VERSION ""

NS_ :

BS_:

BU_: PowertrainControlModule AtmosphericSensor SafetyRestraintSystem2 Aftertreatment_2_GasOutlet Aftertreatment_2_GasIntake DieselParticulateFilterControl Turbocharger SafetyRestraintSystem1 CabDisplay2 Aftertreatment_1_GasOutlet Aftertreatment_1_GasIntake OnBoardDataLogger OffBoardDiagnosticTool2 OffBoardDiagnosticTool1 FileServer ParkingBrakeController SeatController2 FanDriveController SteeringColumnUnit CommunicationUnitRadio CommunicationUnitSatellite CommunicationUnitCellular PropulsionBatteryCharger ChassisController2 ChassisController1 EngineValveControl AuxiliaryHeater2 AuxiliaryHeater1 ClutchUnit RampControl InformationSystem1 SuspensionSystemController2 OilSensor VehicleDynamicStability ExhaustEmissionController TransmissionDisplay2 TransmissionDisplay1 ClimateControl2 WaterPumpController RearAxleSteeringController LightingOperatorControl SeatController1 IgnitionController2 IgnitionController1 TirePressureController CabController2 CabController1 PneumaticSystemController SuspensionSystemController1 HydraulicPumpController EnduranceBrakingSystem RetarderExhaustEngine2 OnBoardDiagnosticUnit HeadwayController RetarderExhaustEngine1 CabDisplay1 ManagementComputer VirtualTerminal OffVehicleGateway PowerTakeOffFront HitchControl AuxiliaryValveControl BodyController TractorTrailerBridge1 StarterSystem ElectricalSystem VehicleSecurity VehicleNavigation AerodynamicControl ElectricalChargingSystem ClimateControl1 TripRecorder InstrumentCluster SuspensionDriveAxle2 SuspensionDriveAxle1 SuspensionSteerAxle SteeringController FuelSystem CruiseControl RetarderDriveline RetarderEngine BrakesDriveAxle2 BrakesDriveAxle1 BrakesSystemController BrakesSteerAxle AxleDrive2 AxleDrive1 AxleSteering PowerTakeOff ShiftConsoleSecondary ShiftConsolePrimary Transmission2 Transmission1 Engine2 Engine1

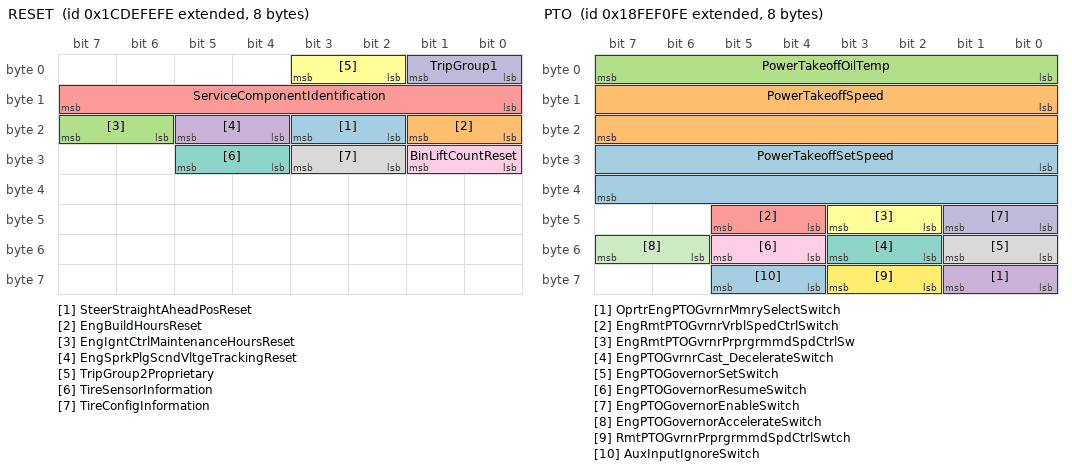
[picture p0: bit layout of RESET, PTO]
BO_ 2631859966 RESET: 8 Vector__XXX
 SG_ SteerStraightAheadPosReset : 18|2@1+ (1,0) [0|3] "" Vector__XXX
 SG_ EngBuildHoursReset : 16|2@1+ (1,0) [0|3] "" Vector__XXX
 SG_ EngIgntCtrlMaintenanceHoursReset : 22|2@1+ (1,0) [0|3] "" Vector__XXX
 SG_ EngSprkPlgScndVltgeTrackingReset : 20|2@1+ (1,0) [0|3] "" Vector__XXX
 SG_ ServiceComponentIdentification : 8|8@1+ (1,0) [0|250] "ID" Vector__XXX
 SG_ TripGroup2Proprietary : 2|2@1+ (1,0) [0|3] "" Vector__XXX
 SG_ TireSensorInformation : 28|2@1+ (1,0) [0|3] "" Vector__XXX
 SG_ TireConfigInformation : 26|2@1+ (1,0) [0|3] "" Vector__XXX
 SG_ BinLiftCountReset : 24|2@1+ (1,0) [0|3] "" Vector__XXX
 SG_ TripGroup1 : 0|2@1+ (1,0) [0|3] "" Vector__XXX

BO_ 2566840830 RC: 19 Vector__XXX
 SG_ PercentTorqueAtPeakTorquePoint5 : 144|8@1+ (1,-125) [-125|0] "%" Vector__XXX
 SG_ ReferenceRetarderTorque : 128|16@1+ (1,0) [0|64255] "Nm" Vector__XXX
 SG_ RetarderSpeedAtPeakTorquePoint5 : 112|16@1+ (0.125,0) [0|8031.875] "rpm" Vector__XXX
 SG_ PercentTorqueAtPoint4 : 104|8@1+ (1,-125) [-125|0] "%" Vector__XXX
 SG_ RetarderSpeedAtPoint4 : 88|16@1+ (0.125,0) [0|8031.875] "rpm" Vector__XXX
 SG_ PercentTorqueAtPoint3 : 80|8@1+ (1,-125) [-125|0] "%" Vector__XXX
 SG_ RetarderSpeedAtPoint3 : 64|16@1+ (0.125,0) [0|8031.875] "rpm" Vector__XXX
 SG_ PercentTorqueAtMaxSpeedPoint2 : 56|8@1+ (1,-125) [-125|0] "%" Vector__XXX
 SG_ MaxRetarderSpeedPoint2 : 40|16@1+ (0.125,0) [0|8031.875] "rpm" Vector__XXX
 SG_ PercentTorqueAtIdlePoint1 : 32|8@1+ (1,-125) [-125|0] "%" Vector__XXX
 SG_ RetarderSpeedAtIdlePoint1 : 16|16@1+ (0.125,0) [0|8031.875] "rpm" Vector__XXX
 SG_ RetarderCtrlMethod : 8|8@1+ (1,0) [0|250] "steps" Vector__XXX
 SG_ RetarderLocation : 4|4@1+ (1,0) [0|15] "" Vector__XXX
 SG_ RetarderType : 0|4@1+ (1,0) [0|15] "" Vector__XXX

BO_ 2633930238 RBI: 8 Vector__XXX
 SG_ EngOperationTimeSinceRebuild : 0|32@1+ (1,0) [0|4211081215] "s" Vector__XXX

BO_ 2566844670 PTO: 8 Vector__XXX
 SG_ PowerTakeoffSetSpeed : 24|16@1+ (0.125,0) [0|8031.875] "rpm" Vector__XXX
 SG_ PowerTakeoffSpeed : 8|16@1+ (0.125,0) [0|8031.875] "rpm" Vector__XXX
 SG_ PowerTakeoffOilTemp : 0|8@1+ (1,-40) [-40|210] "°C" Vector__XXX
 SG_ OprtrEngPTOGvrnrMmrySelectSwitch : 56|2@1+ (1,0) [0|3] "" Vector__XXX
 SG_ EngRmtPTOGvrnrVrblSpedCtrlSwitch : 44|2@1+ (1,0) [0|3] "" Vector__XXX
 SG_ EngRmtPTOGvrnrPrprgrmmdSpdCtrlSw : 42|2@1+ (1,0) [0|3] "" Vector__XXX
 SG_ EngPTOGvrnrCast_DecelerateSwitch : 50|2@1+ (1,0) [0|3] "" Vector__XXX
 SG_ EngPTOGovernorSetSwitch : 48|2@1+ (1,0) [0|3] "" Vector__XXX
 SG_ EngPTOGovernorResumeSwitch : 52|2@1+ (1,0) [0|3] "" Vector__XXX
 SG_ EngPTOGovernorEnableSwitch : 40|2@1+ (1,0) [0|3] "" Vector__XXX
 SG_ EngPTOGovernorAccelerateSwitch : 54|2@1+ (1,0) [0|3] "" Vector__XXX
 SG_ RmtPTOGvrnrPrprgrmmdSpdCtrlSwtch : 58|2@1+ (1,0) [0|3] "" Vector__XXX
 SG_ AuxInputIgnoreSwitch : 60|2@1+ (1,0) [0|3] "" Vector__XXX

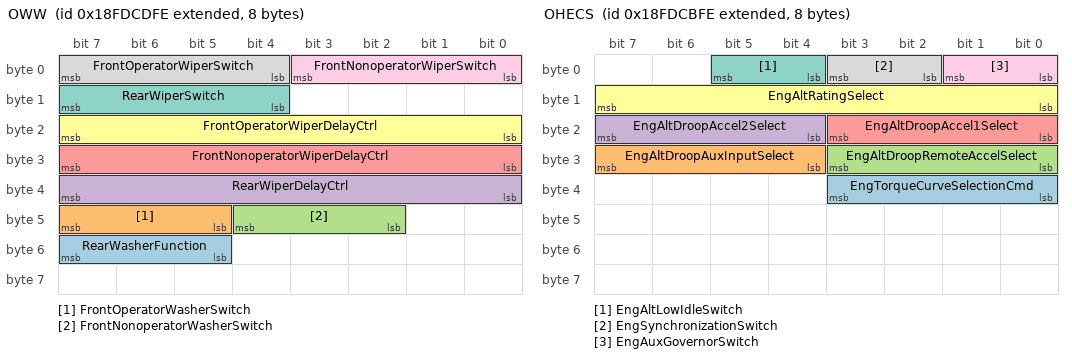
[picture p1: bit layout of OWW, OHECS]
BO_ 2566770174 OWW: 8 Vector__XXX
 SG_ RearWasherFunction : 53|3@1+ (1,0) [0|7] "" Vector__XXX
 SG_ FrontOperatorWasherSwitch : 45|3@1+ (1,0) [0|7] "" Vector__XXX
 SG_ FrontNonoperatorWasherSwitch : 42|3@1+ (1,0) [0|7] "" Vector__XXX
 SG_ RearWiperDelayCtrl : 32|8@1+ (0.4,0) [0|100] "%" Vector__XXX
 SG_ FrontNonoperatorWiperDelayCtrl : 24|8@1+ (0.4,0) [0|100] "%" Vector__XXX
 SG_ FrontOperatorWiperDelayCtrl : 16|8@1+ (0.4,0) [0|100] "%" Vector__XXX
 SG_ RearWiperSwitch : 12|4@1+ (1,0) [0|15] "" Vector__XXX
 SG_ FrontOperatorWiperSwitch : 4|4@1+ (1,0) [0|15] "" Vector__XXX
 SG_ FrontNonoperatorWiperSwitch : 0|4@1+ (1,0) [0|15] "" Vector__XXX

BO_ 2566769662 OHECS: 8 Vector__XXX
 SG_ EngTorqueCurveSelectionCmd : 32|4@1+ (1,0) [0|15] "" Vector__XXX
 SG_ EngAltDroopAuxInputSelect : 28|4@1+ (1,0) [0|15] "" Vector__XXX
 SG_ EngAltDroopRemoteAccelSelect : 24|4@1+ (1,0) [0|15] "" Vector__XXX
 SG_ EngAltDroopAccel2Select : 20|4@1+ (1,0) [0|15] "" Vector__XXX
 SG_ EngAltDroopAccel1Select : 16|4@1+ (1,0) [0|15] "" Vector__XXX
 SG_ EngAltRatingSelect : 8|8@1+ (1,0) [0|255] "" Vector__XXX
 SG_ EngAltLowIdleSwitch : 4|2@1+ (1,0) [0|3] "" Vector__XXX
 SG_ EngSynchronizationSwitch : 2|2@1+ (1,0) [0|3] "" Vector__XXX
 SG_ EngAuxGovernorSwitch : 0|2@1+ (1,0) [0|3] "" Vector__XXX

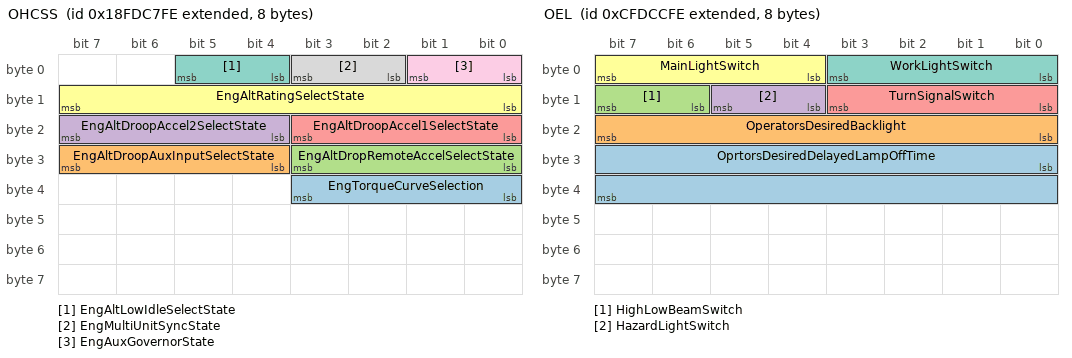
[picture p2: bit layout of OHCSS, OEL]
BO_ 2566768638 OHCSS: 8 Vector__XXX
 SG_ EngTorqueCurveSelection : 32|4@1+ (1,0) [0|15] "" Vector__XXX
 SG_ EngAltDroopAuxInputSelectState : 28|4@1+ (1,0) [0|15] "" Vector__XXX
 SG_ EngAltDropRemoteAccelSelectState : 24|4@1+ (1,0) [0|15] "" Vector__XXX
 SG_ EngAltDroopAccel2SelectState : 20|4@1+ (1,0) [0|15] "" Vector__XXX
 SG_ EngAltDroopAccel1SelectState : 16|4@1+ (1,0) [0|15] "" Vector__XXX
 SG_ EngAltRatingSelectState : 8|8@1+ (1,0) [0|255] "" Vector__XXX
 SG_ EngAltLowIdleSelectState : 4|2@1+ (1,0) [0|3] "" Vector__XXX
 SG_ EngMultiUnitSyncState : 2|2@1+ (1,0) [0|3] "" Vector__XXX
 SG_ EngAuxGovernorState : 0|2@1+ (1,0) [0|3] "" Vector__XXX

BO_ 2365443326 OEL: 8 Vector__XXX
 SG_ OprtorsDesiredDelayedLampOffTime : 24|16@1+ (1,0) [0|64255] "s" Vector__XXX
 SG_ OperatorsDesiredBacklight : 16|8@1+ (0.4,0) [0|100] "%" Vector__XXX
 SG_ HighLowBeamSwitch : 14|2@1+ (1,0) [0|3] "" Vector__XXX
 SG_ HazardLightSwitch : 12|2@1+ (1,0) [0|3] "" Vector__XXX
 SG_ TurnSignalSwitch : 8|4@1+ (1,0) [0|15] "" Vector__XXX
 SG_ MainLightSwitch : 4|4@1+ (1,0) [0|15] "" Vector__XXX
 SG_ WorkLightSwitch : 0|4@1+ (1,0) [0|15] "" Vector__XXX

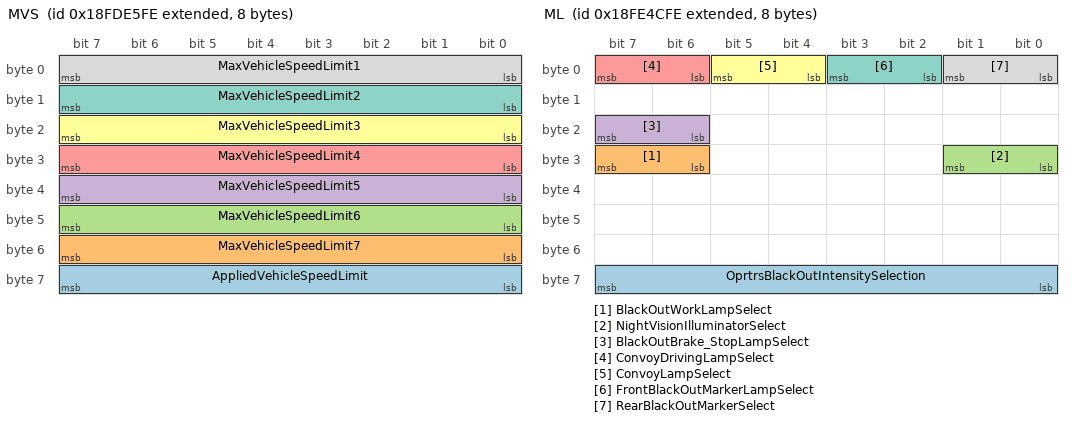
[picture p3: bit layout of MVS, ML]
BO_ 2566776318 MVS: 8 Vector__XXX
 SG_ AppliedVehicleSpeedLimit : 56|8@1+ (1,0) [0|250] "km/h" Vector__XXX
 SG_ MaxVehicleSpeedLimit7 : 48|8@1+ (1,0) [0|250] "km/h" Vector__XXX
 SG_ MaxVehicleSpeedLimit6 : 40|8@1+ (1,0) [0|250] "km/h" Vector__XXX
 SG_ MaxVehicleSpeedLimit5 : 32|8@1+ (1,0) [0|250] "km/h" Vector__XXX
 SG_ MaxVehicleSpeedLimit4 : 24|8@1+ (1,0) [0|250] "km/h" Vector__XXX
 SG_ MaxVehicleSpeedLimit3 : 16|8@1+ (1,0) [0|250] "km/h" Vector__XXX
 SG_ MaxVehicleSpeedLimit2 : 8|8@1+ (1,0) [0|250] "km/h" Vector__XXX
 SG_ MaxVehicleSpeedLimit1 : 0|8@1+ (1,0) [0|250] "km/h" Vector__XXX

BO_ 2566802686 ML: 8 Vector__XXX
 SG_ OprtrsBlackOutIntensitySelection : 56|8@1+ (0.4,0) [0|100] "%" Vector__XXX
 SG_ BlackOutWorkLampSelect : 30|2@1+ (1,0) [0|3] "" Vector__XXX
 SG_ NightVisionIlluminatorSelect : 24|2@1+ (1,0) [0|3] "" Vector__XXX
 SG_ BlackOutBrake_StopLampSelect : 22|2@1+ (1,0) [0|3] "" Vector__XXX
 SG_ ConvoyDrivingLampSelect : 6|2@1+ (1,0) [0|3] "" Vector__XXX
 SG_ ConvoyLampSelect : 4|2@1+ (1,0) [0|3] "" Vector__XXX
 SG_ FrontBlackOutMarkerLampSelect : 2|2@1+ (1,0) [0|3] "" Vector__XXX
 SG_ RearBlackOutMarkerSelect : 0|2@1+ (1,0) [0|3] "" Vector__XXX

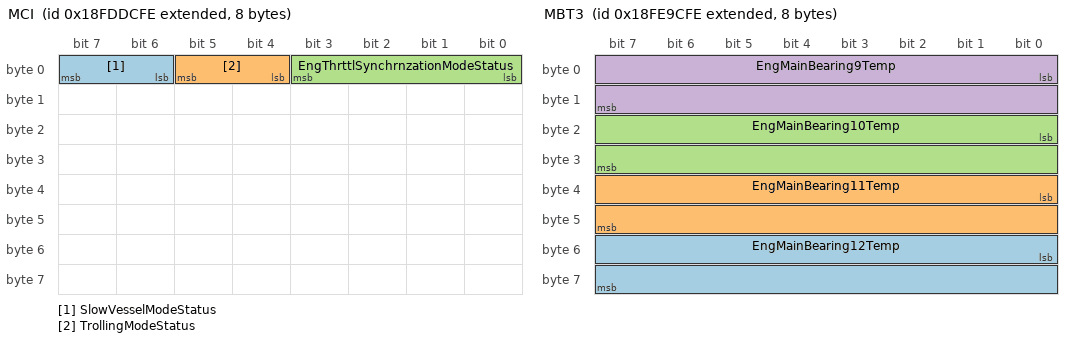
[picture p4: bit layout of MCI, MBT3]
BO_ 2566774014 MCI: 8 Vector__XXX
 SG_ SlowVesselModeStatus : 6|2@1+ (1,0) [0|3] "" Vector__XXX
 SG_ TrollingModeStatus : 4|2@1+ (1,0) [0|3] "" Vector__XXX
 SG_ EngThrttlSynchrnzationModeStatus : 0|4@1+ (1,0) [0|15] "" Vector__XXX

BO_ 2566823166 MBT3: 8 Vector__XXX
 SG_ EngMainBearing12Temp : 48|16@1+ (0.03125,-273) [-273|1734.96875] "°C" Vector__XXX
 SG_ EngMainBearing11Temp : 32|16@1+ (0.03125,-273) [-273|1734.96875] "°C" Vector__XXX
 SG_ EngMainBearing10Temp : 16|16@1+ (0.03125,-273) [-273|1734.96875] "°C" Vector__XXX
 SG_ EngMainBearing9Temp : 0|16@1+ (0.03125,-273) [-273|1734.96875] "°C" Vector__XXX

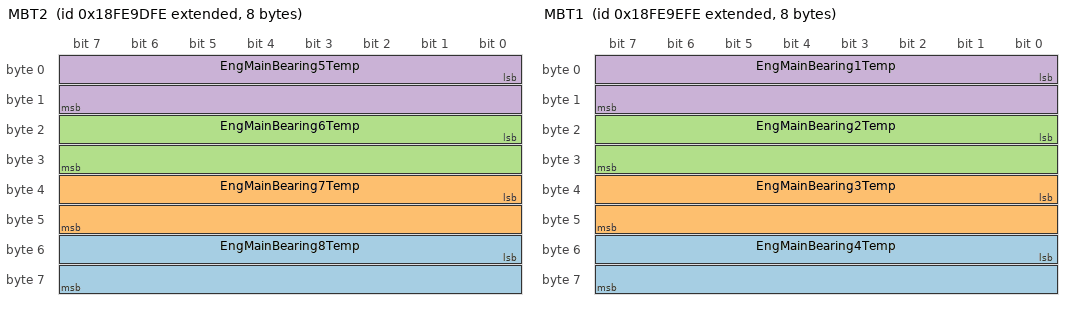
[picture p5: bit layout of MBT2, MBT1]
BO_ 2566823422 MBT2: 8 Vector__XXX
 SG_ EngMainBearing8Temp : 48|16@1+ (0.03125,-273) [-273|1734.96875] "°C" Vector__XXX
 SG_ EngMainBearing7Temp : 32|16@1+ (0.03125,-273) [-273|1734.96875] "°C" Vector__XXX
 SG_ EngMainBearing6Temp : 16|16@1+ (0.03125,-273) [-273|1734.96875] "°C" Vector__XXX
 SG_ EngMainBearing5Temp : 0|16@1+ (0.03125,-273) [-273|1734.96875] "°C" Vector__XXX

BO_ 2566823678 MBT1: 8 Vector__XXX
 SG_ EngMainBearing4Temp : 48|16@1+ (0.03125,-273) [-273|1734.96875] "°C" Vector__XXX
 SG_ EngMainBearing3Temp : 32|16@1+ (0.03125,-273) [-273|1734.96875] "°C" Vector__XXX
 SG_ EngMainBearing2Temp : 16|16@1+ (0.03125,-273) [-273|1734.96875] "°C" Vector__XXX
 SG_ EngMainBearing1Temp : 0|16@1+ (0.03125,-273) [-273|1734.96875] "°C" Vector__XXX

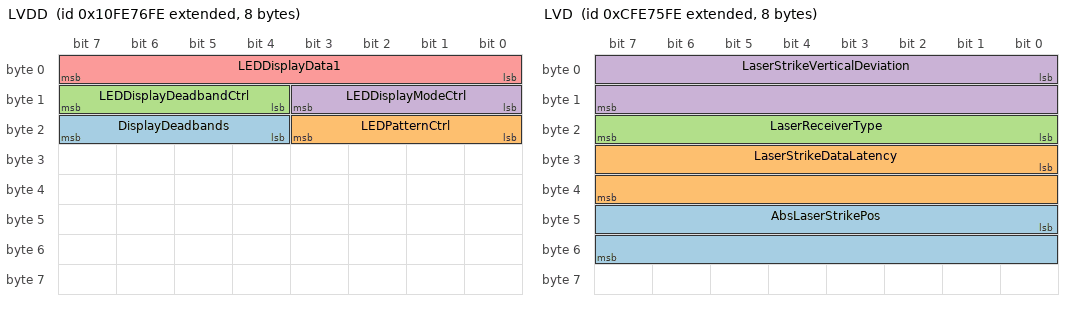
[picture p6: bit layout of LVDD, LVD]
BO_ 2432595710 LVDD: 8 Vector__XXX
 SG_ DisplayDeadbands : 20|4@1+ (1,0) [0|15] "" Vector__XXX
 SG_ LEDPatternCtrl : 16|4@1+ (1,0) [0|15] "" Vector__XXX
 SG_ LEDDisplayDeadbandCtrl : 12|4@1+ (1,0) [0|15] "" Vector__XXX
 SG_ LEDDisplayModeCtrl : 8|4@1+ (1,0) [0|15] "" Vector__XXX
 SG_ LEDDisplayData1 : 0|8@1+ (1,0) [0|255] "" Vector__XXX

BO_ 2365486590 LVD: 8 Vector__XXX
 SG_ AbsLaserStrikePos : 40|16@1+ (0.1,0) [0|6425.5] "mm" Vector__XXX
 SG_ LaserStrikeDataLatency : 24|16@1+ (5.12E-005,0) [0|3.289856] "s" Vector__XXX
 SG_ LaserReceiverType : 16|8@1+ (1,0) [0|250] "" Vector__XXX
 SG_ LaserStrikeVerticalDeviation : 0|16@1+ (0.1,-3200) [-3200|3225.5] "mm" Vector__XXX

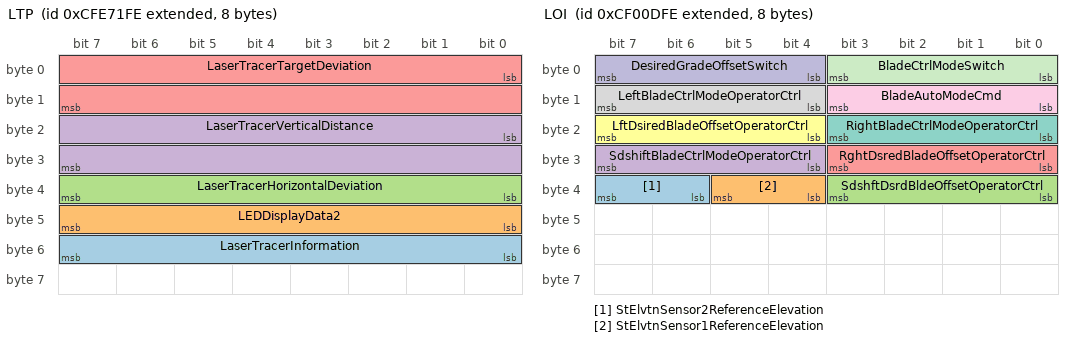
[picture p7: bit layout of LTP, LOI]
BO_ 2365485566 LTP: 8 Vector__XXX
 SG_ LaserTracerInformation : 48|8@1+ (1,0) [0|255] "" Vector__XXX
 SG_ LEDDisplayData2 : 40|8@1+ (1,0) [0|255] "" Vector__XXX
 SG_ LaserTracerHorizontalDeviation : 32|8@1+ (1,0) [0|200] "%" Vector__XXX
 SG_ LaserTracerVerticalDistance : 16|16@1+ (0.1,0) [0|6400] "mm" Vector__XXX
 SG_ LaserTracerTargetDeviation : 0|16@1+ (0.1,-3200) [-3200|3225.5] "mm" Vector__XXX

BO_ 2633939454 LTFI: 22 Vector__XXX
 SG_ TripDriveFuelEconomy : 160|16@1+ (0.001953125,0) [0|125.498046875] "km/L" Vector__XXX
 SG_ TripCruiseFuelUsed : 128|32@1+ (0.5,0) [0|2105540607.5] "L" Vector__XXX
 SG_ TripVehicleIdleFuelUsed : 96|32@1+ (0.5,0) [0|2105540607.5] "L" Vector__XXX
 SG_ TripPTOGovernorNonmovingFuelUsed : 64|32@1+ (0.5,0) [0|2105540607.5] "L" Vector__XXX
 SG_ TripPTOGovernorMovingFuelUsed : 32|32@1+ (0.5,0) [0|2105540607.5] "L" Vector__XXX
 SG_ TripDriveFuelUsed : 0|32@1+ (0.5,0) [0|2105540607.5] "L" Vector__XXX

BO_ 2365486334 LSP: 8 Vector__XXX
 SG_ BldeHeightSetPointHighResolution : 16|32@1+ (1E-007,-209.7152) [-209.7152|209.7152] "m" Vector__XXX
 SG_ ModifyLevelingSystemSetPoint : 0|16@1+ (0.1,-3200) [-3200|3225.5] "mm" Vector__XXX

BO_ 2364542462 LOI: 8 Vector__XXX
 SG_ StElvtnSensor2ReferenceElevation : 38|2@1+ (1,0) [0|3] "" Vector__XXX
 SG_ StElvtnSensor1ReferenceElevation : 36|2@1+ (1,0) [0|3] "" Vector__XXX
 SG_ SdshftDsrdBldeOffsetOperatorCtrl : 32|4@1+ (1,0) [0|15] "" Vector__XXX
 SG_ SdshiftBladeCtrlModeOperatorCtrl : 28|4@1+ (1,0) [0|15] "" Vector__XXX
 SG_ RghtDsredBladeOffsetOperatorCtrl : 24|4@1+ (1,0) [0|15] "" Vector__XXX
 SG_ LftDsiredBladeOffsetOperatorCtrl : 20|4@1+ (1,0) [0|15] "" Vector__XXX
 SG_ RightBladeCtrlModeOperatorCtrl : 16|4@1+ (1,0) [0|15] "" Vector__XXX
 SG_ LeftBladeCtrlModeOperatorCtrl : 12|4@1+ (1,0) [0|15] "" Vector__XXX
 SG_ BladeAutoModeCmd : 8|4@1+ (1,0) [0|15] "" Vector__XXX
 SG_ DesiredGradeOffsetSwitch : 4|4@1+ (1,0) [0|15] "" Vector__XXX
 SG_ BladeCtrlModeSwitch : 0|4@1+ (1,0) [0|15] "" Vector__XXX

BO_ 2365486078 LMP: 8 Vector__XXX
 SG_ MastPos : 0|16@1+ (0.1,-3200) [-3200|3225.5] "mm" Vector__XXX

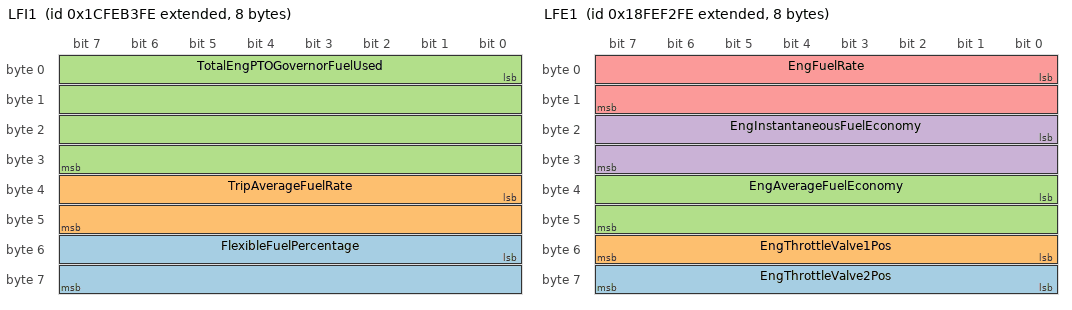
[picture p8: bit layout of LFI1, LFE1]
BO_ 2633937918 LFI1: 8 Vector__XXX
 SG_ FlexibleFuelPercentage : 48|16@1+ (0.0025,0) [0|100] "%" Vector__XXX
 SG_ TripAverageFuelRate : 32|16@1+ (0.05,0) [0|3212.75] "L/h" Vector__XXX
 SG_ TotalEngPTOGovernorFuelUsed : 0|32@1+ (0.5,0) [0|2105540607.5] "L" Vector__XXX

BO_ 2566845182 LFE1: 8 Vector__XXX
 SG_ EngThrottleValve2Pos : 56|8@1+ (0.4,0) [0|100] "%" Vector__XXX
 SG_ EngThrottleValve1Pos : 48|8@1+ (0.4,0) [0|100] "%" Vector__XXX
 SG_ EngAverageFuelEconomy : 32|16@1+ (0.001953125,0) [0|125.498046875] "km/L" Vector__XXX
 SG_ EngInstantaneousFuelEconomy : 16|16@1+ (0.001953125,0) [0|125.498046875] "km/L" Vector__XXX
 SG_ EngFuelRate : 0|16@1+ (0.05,0) [0|3212.75] "L/h" Vector__XXX

BO_ 2566842878 LFC1: 8 Vector__XXX
 SG_ EngTotalFuelUsed : 32|32@1+ (0.5,0) [0|2105540607.5] "L" Vector__XXX
 SG_ EngTripFuel : 0|32@1+ (0.5,0) [0|2105540607.5] "L" Vector__XXX

BO_ 2633883646 FWD: 8 Vector__XXX
 SG_ FrontWheelDriveActuatorStatus : 0|2@1+ (1,0) [0|3] "" Vector__XXX

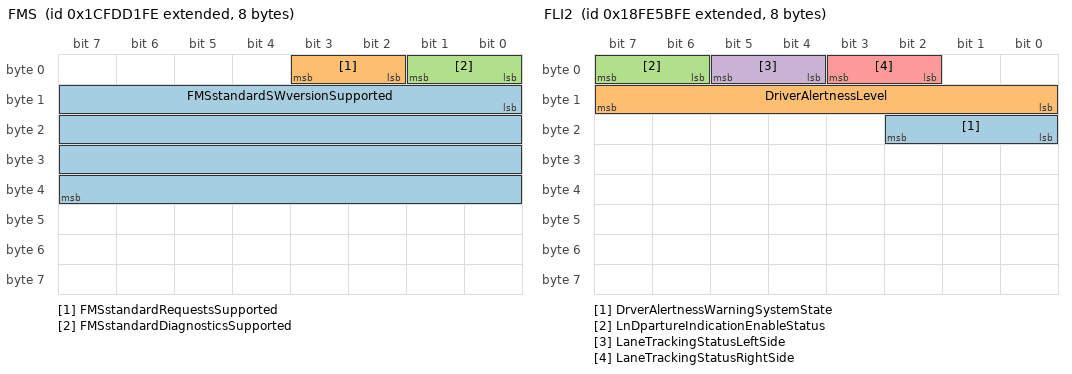
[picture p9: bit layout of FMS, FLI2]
BO_ 2633880062 FMS: 8 Vector__XXX
 SG_ FMSstandardSWversionSupported : 8|32@1+ (1,0) [0|255] "" Vector__XXX
 SG_ FMSstandardRequestsSupported : 2|2@1+ (1,0) [0|3] "" Vector__XXX
 SG_ FMSstandardDiagnosticsSupported : 0|2@1+ (1,0) [0|3] "" Vector__XXX

BO_ 2566806526 FLI2: 8 Vector__XXX
 SG_ DrverAlertnessWarningSystemState : 16|3@1+ (1,0) [0|7] "" Vector__XXX
 SG_ DriverAlertnessLevel : 8|8@1+ (0.4,0) [0|100] "%" Vector__XXX
 SG_ LnDpartureIndicationEnableStatus : 6|2@1+ (1,0) [0|3] "" Vector__XXX
 SG_ LaneTrackingStatusLeftSide : 4|2@1+ (1,0) [0|3] "" Vector__XXX
 SG_ LaneTrackingStatusRightSide : 2|2@1+ (1,0) [0|3] "" Vector__XXX

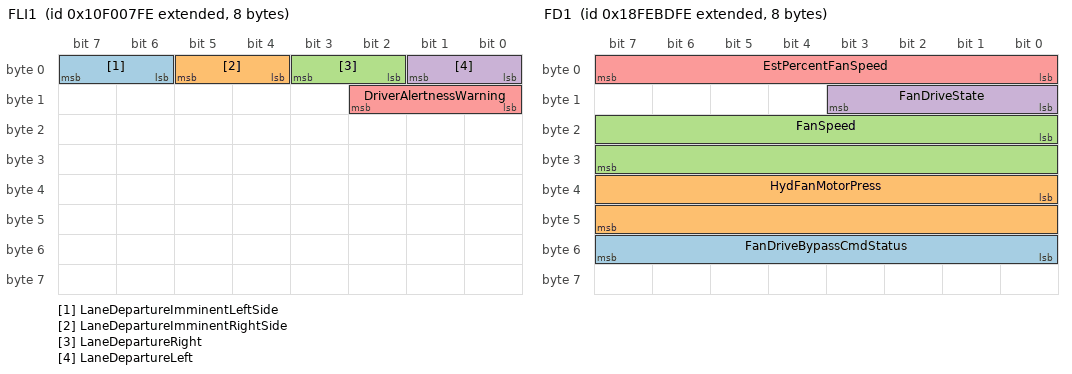
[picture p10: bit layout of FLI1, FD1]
BO_ 2431649790 FLI1: 8 Vector__XXX
 SG_ LaneDepartureImminentLeftSide : 6|2@1+ (1,0) [0|3] "" Vector__XXX
 SG_ LaneDepartureImminentRightSide : 4|2@1+ (1,0) [0|3] "" Vector__XXX
 SG_ LaneDepartureRight : 2|2@1+ (1,0) [0|3] "" Vector__XXX
 SG_ LaneDepartureLeft : 0|2@1+ (1,0) [0|3] "" Vector__XXX
 SG_ DriverAlertnessWarning : 8|3@1+ (1,0) [0|7] "" Vector__XXX

BO_ 2633929214 FL: 8 Vector__XXX
 SG_ EngFuelLeakage2 : 2|2@1+ (1,0) [0|3] "" Vector__XXX
 SG_ EngFuelLeakage1 : 0|2@1+ (1,0) [0|3] "" Vector__XXX

BO_ 2566831614 FD1: 8 Vector__XXX
 SG_ FanDriveBypassCmdStatus : 48|8@1+ (0.4,0) [0|100] "%" Vector__XXX
 SG_ HydFanMotorPress : 32|16@1+ (0.5,0) [0|32127.5] "kPa" Vector__XXX
 SG_ FanSpeed : 16|16@1+ (0.125,0) [0|8031.875] "rpm" Vector__XXX
 SG_ FanDriveState : 8|4@1+ (1,0) [0|15] "" Vector__XXX
 SG_ EstPercentFanSpeed : 0|8@1+ (0.4,0) [0|100] "%" Vector__XXX

BO_ 2566820094 ETH: 8 Vector__XXX
 SG_ EngTorqueLimit6AxleInput : 248|16@1+ (2,0) [0|128510] "Nm" Vector__XXX
 SG_ EngTorqueLimit5Switch : 232|16@1+ (1,0) [0|64255] "Nm" Vector__XXX
 SG_ EngTorqueLimit4Trans : 216|16@1+ (1,0) [0|64255] "Nm" Vector__XXX
 SG_ EngTorqueLimit3Trans : 200|16@1+ (1,0) [0|64255] "Nm" Vector__XXX
 SG_ TransGearRatio3 : 184|16@1+ (0.01,0) [0|642.55] "" Vector__XXX
 SG_ EngTorqueLimit2Trans : 168|16@1+ (1,0) [0|64255] "Nm" Vector__XXX
 SG_ TransGearRatio2 : 152|16@1+ (0.01,0) [0|642.55] "" Vector__XXX
 SG_ EngTorqueLimit1Trans : 136|16@1+ (1,0) [0|64255] "Nm" Vector__XXX
 SG_ TransGearRatio1 : 120|16@1+ (0.01,0) [0|642.55] "" Vector__XXX
 SG_ EngTorqueLimitFeature : 114|3@1+ (1,0) [0|7] "" Vector__XXX
 SG_ TorqueLimitingFeatureStatus : 112|2@1+ (1,0) [0|3] "" Vector__XXX
 SG_ CalibRecordDurationTime : 80|32@1+ (0.05,0) [0|210554060.75] "h" Vector__XXX
 SG_ CalibRecordStartYear : 72|8@1+ (1,1985) [1985|2235] "years" Vector__XXX
 SG_ CalibRecordStartDay : 64|8@1+ (0.25,0) [0.25|31.75] "days" Vector__XXX
 SG_ CalibRecordStartMonth : 56|8@1+ (1,0) [1|12] "months" Vector__XXX
 SG_ EngPeakTorque2 : 40|16@1+ (1,0) [0|64255] "Nm" Vector__XXX
 SG_ EngPeakTorque1 : 24|16@1+ (1,0) [0|64255] "Nm" Vector__XXX
 SG_ EngPower : 8|16@1+ (0.5,0) [0|32127.5] "kW" Vector__XXX
 SG_ NumberOfEngTorqueHistoryRecords : 0|8@1+ (1,0) [0|250] "records" Vector__XXX

BO_ 2364542206 ETC8: 8 Vector__XXX
 SG_ TransClutch_ConverterInputSpeed : 16|16@1+ (0.125,0) [0|8031.875] "rpm" Vector__XXX
 SG_ TransTorqueConverterRatio : 0|16@1+ (0.001,0) [0|64.255] "" Vector__XXX

BO_ 2566802174 ETC7: 8 Vector__XXX
 SG_ TransAutoNeutralSt : 50|2@1+ (1,0) [0|3] "" Vector__XXX
 SG_ TransWarningIndicator : 42|2@1+ (1,0) [0|3] "" Vector__XXX
 SG_ TrnsRverseGearShiftInhibitStatus : 40|2@1+ (1,0) [0|3] "" Vector__XXX
 SG_ TransMode8Indicator : 38|2@1+ (1,0) [0|3] "" Vector__XXX
 SG_ TransMode7Indicator : 36|2@1+ (1,0) [0|3] "" Vector__XXX
 SG_ TransMode6Indicator : 34|2@1+ (1,0) [0|3] "" Vector__XXX
 SG_ TransMode5Indicator : 32|2@1+ (1,0) [0|3] "" Vector__XXX
 SG_ TransRequestedGearFeedback : 24|8@1+ (1,-125) [-125|125] "" Vector__XXX
 SG_ TransMode1Indicator : 22|2@1+ (1,0) [0|3] "" Vector__XXX
 SG_ TransMode2Indicator : 20|2@1+ (1,0) [0|3] "" Vector__XXX
 SG_ TransMode3Indicator : 18|2@1+ (1,0) [0|3] "" Vector__XXX
 SG_ TransMode4Indicator : 16|2@1+ (1,0) [0|3] "" Vector__XXX
 SG_ TransShiftInhibitIndicator : 14|2@1+ (1,0) [0|3] "" Vector__XXX
 SG_ TransEngCrankEnable : 12|2@1+ (1,0) [0|3] "" Vector__XXX
 SG_ ActiveShiftConsoleIndicator : 10|2@1+ (1,0) [0|3] "" Vector__XXX
 SG_ TransReadyForBrakeRelease : 8|2@1+ (1,0) [0|3] "" Vector__XXX
 SG_ TrnsRqstedRangeDisplayFlashState : 6|2@1+ (1,0) [0|3] "" Vector__XXX
 SG_ TrnsRqstedRangeDisplayBlankState : 4|2@1+ (1,0) [0|3] "" Vector__XXX
 SG_ TransServiceIndicator : 2|2@1+ (1,0) [0|3] "" Vector__XXX
 SG_ TransAirSupplyPressIndicator : 48|2@1+ (1,0) [0|3] "" Vector__XXX
 SG_ TransMode10Indicator : 46|2@1+ (1,0) [0|3] "" Vector__XXX
 SG_ TransMode9Indicator : 44|2@1+ (1,0) [0|3] "" Vector__XXX
 SG_ TrnsCrrentRangeDisplayBlankState : 0|2@1+ (1,0) [0|3] "" Vector__XXX

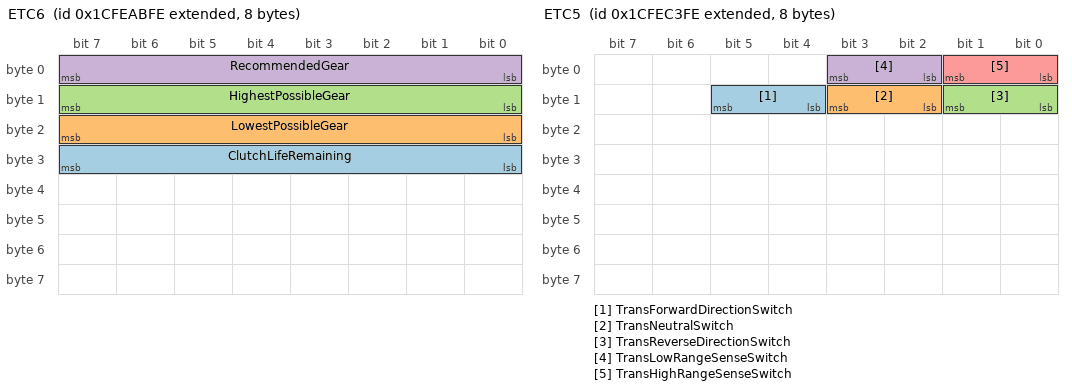
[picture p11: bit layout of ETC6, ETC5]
BO_ 2633935870 ETC6: 8 Vector__XXX
 SG_ ClutchLifeRemaining : 24|8@1+ (0.4,0) [0|100] "%" Vector__XXX
 SG_ LowestPossibleGear : 16|8@1+ (1,-125) [-125|125] "" Vector__XXX
 SG_ HighestPossibleGear : 8|8@1+ (1,-125) [-125|125] "" Vector__XXX
 SG_ RecommendedGear : 0|8@1+ (1,-125) [-125|125] "" Vector__XXX

BO_ 2633942014 ETC5: 8 Vector__XXX
 SG_ TransForwardDirectionSwitch : 12|2@1+ (1,0) [0|3] "" Vector__XXX
 SG_ TransNeutralSwitch : 10|2@1+ (1,0) [0|3] "" Vector__XXX
 SG_ TransReverseDirectionSwitch : 8|2@1+ (1,0) [0|3] "" Vector__XXX
 SG_ TransLowRangeSenseSwitch : 2|2@1+ (1,0) [0|3] "" Vector__XXX
 SG_ TransHighRangeSenseSwitch : 0|2@1+ (1,0) [0|3] "" Vector__XXX

BO_ 2633942526 ETC4: 8 Vector__XXX
 SG_ TransSynchronizerBrakeValue : 8|8@1+ (0.4,0) [0|100] "%" Vector__XXX
 SG_ TransSynchronizerClutchValue : 0|8@1+ (0.4,0) [0|100] "%" Vector__XXX

BO_ 2633943038 ETC3: 8 Vector__XXX
 SG_ TransInertiaBrakeActuator : 46|2@1+ (1,0) [0|3] "" Vector__XXX
 SG_ TransDefuelActuator : 44|2@1+ (1,0) [0|3] "" Vector__XXX
 SG_ TransLockupClutchActuator : 42|2@1+ (1,0) [0|3] "" Vector__XXX
 SG_ TransClutchActuator : 40|2@1+ (1,0) [0|3] "" Vector__XXX
 SG_ TransSplitterIndirectActuator : 38|2@1+ (1,0) [0|3] "" Vector__XXX
 SG_ TransSplitterDirectActuator : 36|2@1+ (1,0) [0|3] "" Vector__XXX
 SG_ TransRangeLowActuator : 34|2@1+ (1,0) [0|3] "" Vector__XXX
 SG_ TransRangeHighActuator : 32|2@1+ (1,0) [0|3] "" Vector__XXX
 SG_ TransShiftFingerGearActuator2 : 30|2@1+ (1,0) [0|3] "" Vector__XXX
 SG_ TransShiftFingerRailActuator2 : 28|2@1+ (1,0) [0|3] "" Vector__XXX
 SG_ TransShiftFingerGearActuator1 : 26|2@1+ (1,0) [0|3] "" Vector__XXX
 SG_ TransShiftFingerRailActuator1 : 24|2@1+ (1,0) [0|3] "" Vector__XXX
 SG_ TrnsShftFngerCenterRailIndicator : 20|2@1+ (1,0) [0|3] "" Vector__XXX
 SG_ TrnsShftFngerEngagementIndicator : 18|2@1+ (1,0) [0|3] "" Vector__XXX
 SG_ TransShiftFingerNeutralIndicator : 16|2@1+ (1,0) [0|3] "" Vector__XXX
 SG_ TransShiftFingerRailPos : 8|8@1+ (0.4,0) [0|100] "%" Vector__XXX
 SG_ TransShiftFingerGearPos : 0|8@1+ (0.4,0) [0|100] "%" Vector__XXX

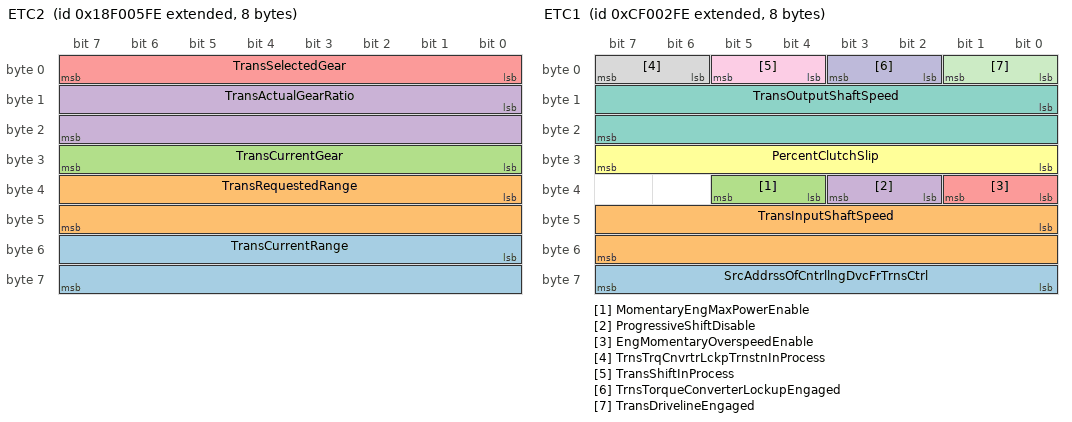
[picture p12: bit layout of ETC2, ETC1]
BO_ 2565867006 ETC2: 8 Vector__XXX
 SG_ TransCurrentRange : 48|16@1+ (1,0) [0|255] "" Vector__XXX
 SG_ TransRequestedRange : 32|16@1+ (1,0) [0|255] "" Vector__XXX
 SG_ TransCurrentGear : 24|8@1+ (1,-125) [-125|125] "" Vector__XXX
 SG_ TransActualGearRatio : 8|16@1+ (0.001,0) [0|64.255] "" Vector__XXX
 SG_ TransSelectedGear : 0|8@1+ (1,-125) [-125|125] "" Vector__XXX

BO_ 2364539646 ETC1: 8 Vector__XXX
 SG_ SrcAddrssOfCntrllngDvcFrTrnsCtrl : 56|8@1+ (1,0) [0|253] "" Vector__XXX
 SG_ TransInputShaftSpeed : 40|16@1+ (0.125,0) [0|8031.875] "rpm" Vector__XXX
 SG_ MomentaryEngMaxPowerEnable : 36|2@1+ (1,0) [0|3] "" Vector__XXX
 SG_ ProgressiveShiftDisable : 34|2@1+ (1,0) [0|3] "" Vector__XXX
 SG_ EngMomentaryOverspeedEnable : 32|2@1+ (1,0) [0|3] "" Vector__XXX
 SG_ PercentClutchSlip : 24|8@1+ (0.4,0) [0|100] "%" Vector__XXX
 SG_ TransOutputShaftSpeed : 8|16@1+ (0.125,0) [0|8031.875] "rpm" Vector__XXX
 SG_ TrnsTrqCnvrtrLckpTrnstnInProcess : 6|2@1+ (1,0) [0|3] "" Vector__XXX
 SG_ TransShiftInProcess : 4|2@1+ (1,0) [0|3] "" Vector__XXX
 SG_ TrnsTorqueConverterLockupEngaged : 2|2@1+ (1,0) [0|3] "" Vector__XXX
 SG_ TransDrivelineEngaged : 0|2@1+ (1,0) [0|3] "" Vector__XXX

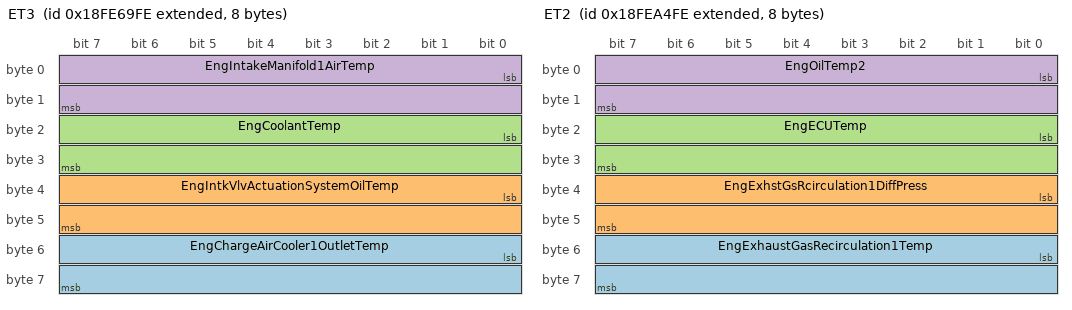
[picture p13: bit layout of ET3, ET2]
BO_ 2566810110 ET3: 8 Vector__XXX
 SG_ EngChargeAirCooler1OutletTemp : 48|16@1+ (0.03125,-273) [-273|1734.96875] "°C" Vector__XXX
 SG_ EngIntkVlvActuationSystemOilTemp : 32|16@1+ (0.03125,-273) [-273|1734.96875] "°C" Vector__XXX
 SG_ EngCoolantTemp : 16|16@1+ (0.03125,-273) [-273|1734.96875] "°C" Vector__XXX
 SG_ EngIntakeManifold1AirTemp : 0|16@1+ (0.03125,-273) [-273|1734.96875] "°C" Vector__XXX

BO_ 2566825214 ET2: 8 Vector__XXX
 SG_ EngExhaustGasRecirculation1Temp : 48|16@1+ (0.03125,-273) [-273|1734.96875] "°C" Vector__XXX
 SG_ EngExhstGsRcirculation1DiffPress : 32|16@1+ (0.0078125,-250) [-250|251.99] "kPa" Vector__XXX
 SG_ EngECUTemp : 16|16@1+ (0.03125,-273) [-273|1734.96875] "°C" Vector__XXX
 SG_ EngOilTemp2 : 0|16@1+ (0.03125,-273) [-273|1734.96875] "°C" Vector__XXX

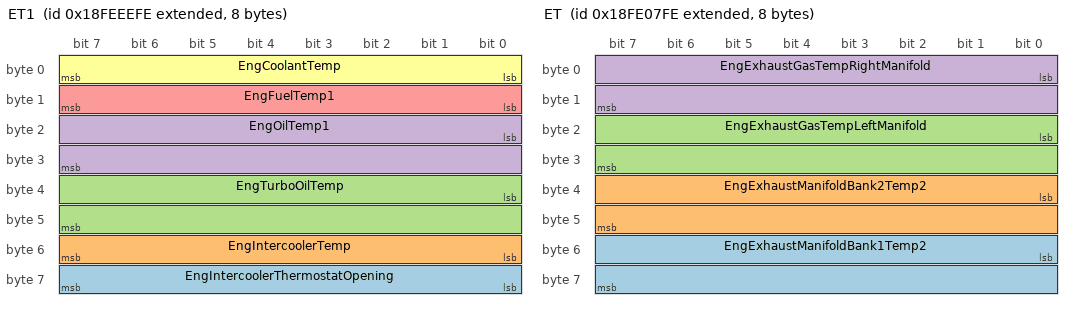
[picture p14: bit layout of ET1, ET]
BO_ 2566844158 ET1: 8 Vector__XXX
 SG_ EngIntercoolerThermostatOpening : 56|8@1+ (0.4,0) [0|100] "%" Vector__XXX
 SG_ EngIntercoolerTemp : 48|8@1+ (1,-40) [-40|210] "°C" Vector__XXX
 SG_ EngTurboOilTemp : 32|16@1+ (0.03125,-273) [-273|1734.96875] "°C" Vector__XXX
 SG_ EngOilTemp1 : 16|16@1+ (0.03125,-273) [-273|1734.96875] "°C" Vector__XXX
 SG_ EngFuelTemp1 : 8|8@1+ (1,-40) [-40|210] "°C" Vector__XXX
 SG_ EngCoolantTemp : 0|8@1+ (1,-40) [-40|210] "°C" Vector__XXX

BO_ 2566785022 ET: 8 Vector__XXX
 SG_ EngExhaustManifoldBank1Temp2 : 48|16@1+ (0.03125,-273) [-273|1734.96875] "°C" Vector__XXX
 SG_ EngExhaustManifoldBank2Temp2 : 32|16@1+ (0.03125,-273) [-273|1734.96875] "°C" Vector__XXX
 SG_ EngExhaustGasTempLeftManifold : 16|16@1+ (0.03125,-273) [-273|1734.96875] "°C" Vector__XXX
 SG_ EngExhaustGasTempRightManifold : 0|16@1+ (0.03125,-273) [-273|1734.96875] "°C" Vector__XXX

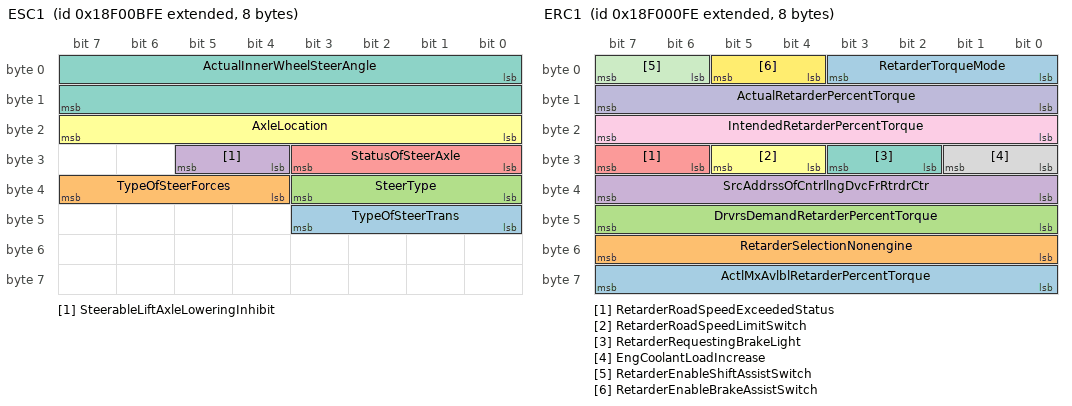
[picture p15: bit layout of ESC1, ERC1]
BO_ 2565868542 ESC1: 8 Vector__XXX
 SG_ TypeOfSteerTrans : 40|4@1+ (1,0) [0|15] "" Vector__XXX
 SG_ TypeOfSteerForces : 36|4@1+ (1,0) [0|15] "" Vector__XXX
 SG_ SteerType : 32|4@1+ (1,0) [0|15] "" Vector__XXX
 SG_ SteerableLiftAxleLoweringInhibit : 28|2@1+ (1,0) [0|3] "" Vector__XXX
 SG_ StatusOfSteerAxle : 24|4@1+ (1,0) [0|15] "" Vector__XXX
 SG_ AxleLocation : 16|8@1+ (1,0) [0|255] "" Vector__XXX
 SG_ ActualInnerWheelSteerAngle : 0|16@1+ (0.00390625,-125) [-125|125] "deg" Vector__XXX

BO_ 2633941758 ERC2: 8 Vector__XXX
 SG_ CrsCtrlRetarderActiveSpeedOffset : 8|16@1+ (0.00390625,-125) [0|125.996] "km/h" Vector__XXX
 SG_ TransOutputRetarder : 0|2@1+ (1,0) [0|3] "" Vector__XXX

BO_ 2565865726 ERC1: 8 Vector__XXX
 SG_ ActlMxAvlblRetarderPercentTorque : 56|8@1+ (1,-125) [-125|0] "%" Vector__XXX
 SG_ RetarderSelectionNonengine : 48|8@1+ (0.4,0) [0|100] "%" Vector__XXX
 SG_ DrvrsDemandRetarderPercentTorque : 40|8@1+ (1,-125) [-125|0] "%" Vector__XXX
 SG_ SrcAddrssOfCntrllngDvcFrRtrdrCtr : 32|8@1+ (1,0) [0|253] "" Vector__XXX
 SG_ RetarderRoadSpeedExceededStatus : 30|2@1+ (1,0) [0|3] "" Vector__XXX
 SG_ RetarderRoadSpeedLimitSwitch : 28|2@1+ (1,0) [0|3] "" Vector__XXX
 SG_ RetarderRequestingBrakeLight : 26|2@1+ (1,0) [0|3] "" Vector__XXX
 SG_ EngCoolantLoadIncrease : 24|2@1+ (1,0) [0|3] "" Vector__XXX
 SG_ IntendedRetarderPercentTorque : 16|8@1+ (1,-125) [-125|0] "%" Vector__XXX
 SG_ ActualRetarderPercentTorque : 8|8@1+ (1,-125) [-125|0] "%" Vector__XXX
 SG_ RetarderEnableShiftAssistSwitch : 6|2@1+ (1,0) [0|3] "" Vector__XXX
 SG_ RetarderEnableBrakeAssistSwitch : 4|2@1+ (1,0) [0|3] "" Vector__XXX
 SG_ RetarderTorqueMode : 0|4@1+ (1,0) [0|15] "" Vector__XXX

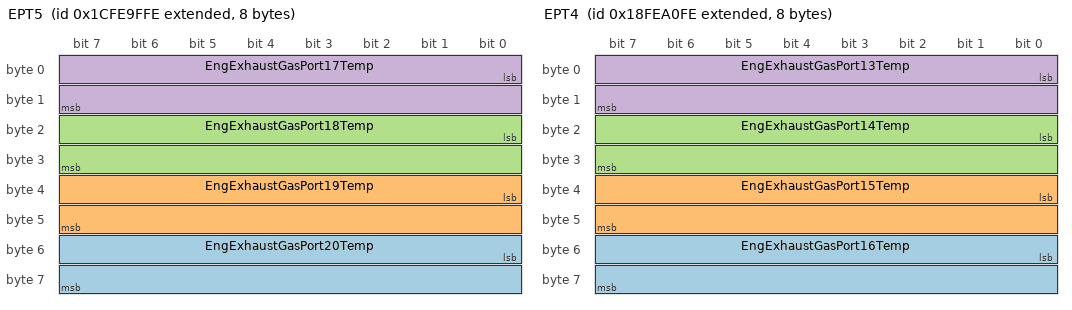
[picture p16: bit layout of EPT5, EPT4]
BO_ 2633932798 EPT5: 8 Vector__XXX
 SG_ EngExhaustGasPort20Temp : 48|16@1+ (0.03125,-273) [-273|1734.96875] "°C" Vector__XXX
 SG_ EngExhaustGasPort19Temp : 32|16@1+ (0.03125,-273) [-273|1734.96875] "°C" Vector__XXX
 SG_ EngExhaustGasPort18Temp : 16|16@1+ (0.03125,-273) [-273|1734.96875] "°C" Vector__XXX
 SG_ EngExhaustGasPort17Temp : 0|16@1+ (0.03125,-273) [-273|1734.96875] "°C" Vector__XXX

BO_ 2566824190 EPT4: 8 Vector__XXX
 SG_ EngExhaustGasPort16Temp : 48|16@1+ (0.03125,-273) [-273|1734.96875] "°C" Vector__XXX
 SG_ EngExhaustGasPort15Temp : 32|16@1+ (0.03125,-273) [-273|1734.96875] "°C" Vector__XXX
 SG_ EngExhaustGasPort14Temp : 16|16@1+ (0.03125,-273) [-273|1734.96875] "°C" Vector__XXX
 SG_ EngExhaustGasPort13Temp : 0|16@1+ (0.03125,-273) [-273|1734.96875] "°C" Vector__XXX

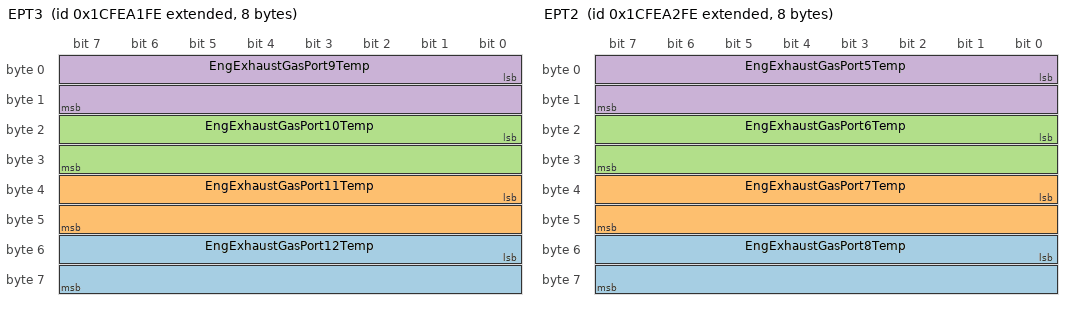
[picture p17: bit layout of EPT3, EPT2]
BO_ 2633933310 EPT3: 8 Vector__XXX
 SG_ EngExhaustGasPort12Temp : 48|16@1+ (0.03125,-273) [-273|1734.96875] "°C" Vector__XXX
 SG_ EngExhaustGasPort11Temp : 32|16@1+ (0.03125,-273) [-273|1734.96875] "°C" Vector__XXX
 SG_ EngExhaustGasPort10Temp : 16|16@1+ (0.03125,-273) [-273|1734.96875] "°C" Vector__XXX
 SG_ EngExhaustGasPort9Temp : 0|16@1+ (0.03125,-273) [-273|1734.96875] "°C" Vector__XXX

BO_ 2633933566 EPT2: 8 Vector__XXX
 SG_ EngExhaustGasPort8Temp : 48|16@1+ (0.03125,-273) [-273|1734.96875] "°C" Vector__XXX
 SG_ EngExhaustGasPort7Temp : 32|16@1+ (0.03125,-273) [-273|1734.96875] "°C" Vector__XXX
 SG_ EngExhaustGasPort6Temp : 16|16@1+ (0.03125,-273) [-273|1734.96875] "°C" Vector__XXX
 SG_ EngExhaustGasPort5Temp : 0|16@1+ (0.03125,-273) [-273|1734.96875] "°C" Vector__XXX

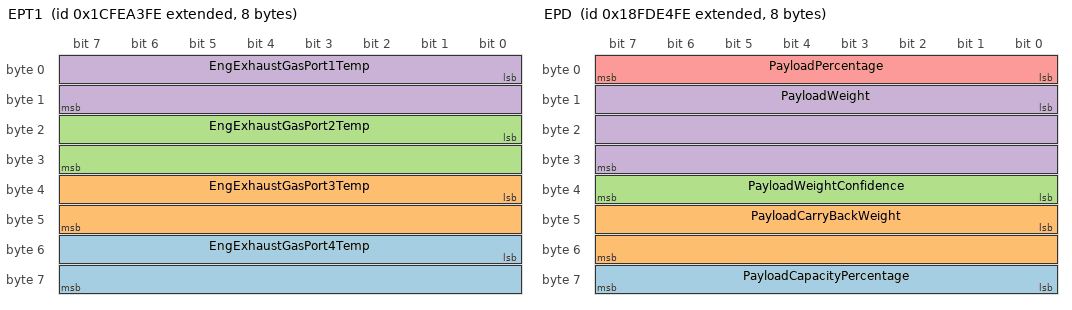
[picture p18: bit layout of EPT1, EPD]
BO_ 2633933822 EPT1: 8 Vector__XXX
 SG_ EngExhaustGasPort4Temp : 48|16@1+ (0.03125,-273) [-273|1734.96875] "°C" Vector__XXX
 SG_ EngExhaustGasPort3Temp : 32|16@1+ (0.03125,-273) [-273|1734.96875] "°C" Vector__XXX
 SG_ EngExhaustGasPort2Temp : 16|16@1+ (0.03125,-273) [-273|1734.96875] "°C" Vector__XXX
 SG_ EngExhaustGasPort1Temp : 0|16@1+ (0.03125,-273) [-273|1734.96875] "°C" Vector__XXX

BO_ 2566776062 EPD: 8 Vector__XXX
 SG_ PayloadCapacityPercentage : 56|8@1+ (1,0) [0|250] "%" Vector__XXX
 SG_ PayloadCarryBackWeight : 40|16@1+ (2,0) [0|128510] "kg" Vector__XXX
 SG_ PayloadWeightConfidence : 32|8@1+ (0.5,0) [0|100] "%" Vector__XXX
 SG_ PayloadWeight : 8|24@1+ (2,0) [0|32899070] "kg" Vector__XXX
 SG_ PayloadPercentage : 0|8@1+ (1,0) [0|250] "%" Vector__XXX

BO_ 2566771454 EP: 8 Vector__XXX
 SG_ DataMemoryUsage : 16|8@1+ (0.4,0) [0|100] "%" Vector__XXX
 SG_ KeepAliveBatteryConsumption : 0|16@1+ (1,0) [0|64255] "mAh" Vector__XXX

BO_ 2566775806 EOAC: 8 Vector__XXX
 SG_ TravelVelocityCtrlPos : 0|8@1+ (1,-125) [-125|125] "%" Vector__XXX

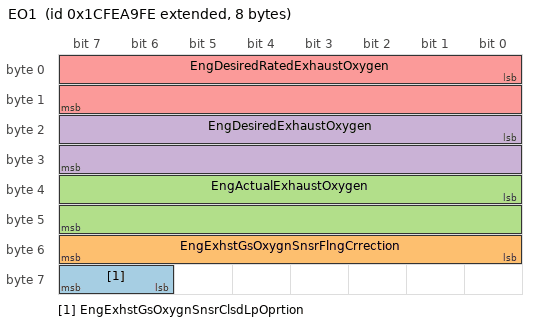
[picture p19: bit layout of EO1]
BO_ 2633935358 EO1: 8 Vector__XXX
 SG_ EngExhstGsOxygnSnsrClsdLpOprtion : 62|2@1+ (1,0) [0|3] "" Vector__XXX
 SG_ EngExhstGsOxygnSnsrFlngCrrection : 48|8@1+ (1,-125) [-125|125] "%" Vector__XXX
 SG_ EngActualExhaustOxygen : 32|16@1+ (0.0025,0) [0|160.6375] "%" Vector__XXX
 SG_ EngDesiredExhaustOxygen : 16|16@1+ (0.0025,0) [0|160.6375] "%" Vector__XXX
 SG_ EngDesiredRatedExhaustOxygen : 0|16@1+ (0.0025,0) [0|160.6375] "%" Vector__XXX

BO_ 2365447166 EJM3: 8 Vector__XXX
 SG_ Joystick3Button13PressedStatus : 62|2@1+ (1,0) [0|3] "" Vector__XXX
 SG_ Joystick3Button14PressedStatus : 60|2@1+ (1,0) [0|3] "" Vector__XXX
 SG_ Joystick3Button15PressedStatus : 58|2@1+ (1,0) [0|3] "" Vector__XXX
 SG_ Joystick3Button16PressedStatus : 56|2@1+ (1,0) [0|3] "" Vector__XXX
 SG_ Jystick3GripXAxisDetentPosStatus : 54|2@1+ (1,0) [0|3] "" Vector__XXX
 SG_ Jystick3GripYAxisDetentPosStatus : 52|2@1+ (1,0) [0|3] "" Vector__XXX
 SG_ Jystick3ThetaAxisDetentPosStatus : 50|2@1+ (1,0) [0|3] "" Vector__XXX
 SG_ Joystick3ThetaAxisPos : 38|10@1+ (0.1,0) [0|100] "%" Vector__XXX
 SG_ Jystck3ThtAxsClckwsPstvPosStatus : 36|2@1+ (1,0) [0|3] "" Vector__XXX
 SG_ Jystck3ThetaAxisNeutralPosStatus : 32|2@1+ (1,0) [0|3] "" Vector__XXX
 SG_ Joystick3GripYAxisPos : 22|10@1+ (0.1,0) [0|100] "%" Vector__XXX
 SG_ Jystck3GrpYAxsLvrFrwrdPstvPsStts : 20|2@1+ (1,0) [0|3] "" Vector__XXX
 SG_ Jystck3GrpYAxsLvrBckNgtvPsStatus : 18|2@1+ (1,0) [0|3] "" Vector__XXX
 SG_ Jystck3GripYAxisNeutralPosStatus : 16|2@1+ (1,0) [0|3] "" Vector__XXX
 SG_ Joystick3GripXAxisPos : 6|10@1+ (0.1,0) [0|100] "%" Vector__XXX
 SG_ Jystck3GrpXAxsLvrRghtPstvPsSttus : 4|2@1+ (1,0) [0|3] "" Vector__XXX
 SG_ Jystck3GrpXAxsLvrLftNgtvPsStatus : 2|2@1+ (1,0) [0|3] "" Vector__XXX
 SG_ Jystck3GripXAxisNeutralPosStatus : 0|2@1+ (1,0) [0|3] "" Vector__XXX
 SG_ Jystck3ThtAxsCntrClckwsNgtvPsStt : 34|2@1+ (1,0) [0|3] "" Vector__XXX

CM_ BO_ 2631859966 "Reset
NOTE—This message requires an Acknowledgement response (See J1939-21, PGN 59392) from the receiving node.  The use of individual proprietary protocols can still be used instead of the \"trip reset\" PGN to maintain security.";
CM_ SG_ 2631859966 SteerStraightAheadPosReset "Used to reset the straight ahead position for a steering sensor in the steering column or a steering controller's straight ahead position on any steerable axle.
00 Take no action - Do not Reset
01 Reset
10 Reserved, take no action
11 Not ...";
CM_ SG_ 2631859966 EngBuildHoursReset "Command signal used to reset the engine rebuild hours.

00 Do not reset
01 Reset
10 Reserved
11 Take no action";
CM_ SG_ 2631859966 EngIgntCtrlMaintenanceHoursReset "Used to reset the maintenance hour counter for an engine ignition control module.  The hours remaining until required maintenance is performed are reported in PGN 64688.

00 Do not reset
01 Reset
10 Reserved
11 Take no action";
CM_ SG_ 2631859966 EngSprkPlgScndVltgeTrackingReset "Command signal used to reset the ignition controller average, maximum, and minimum level tracking of the spark plug secondary voltages and to reset the learned misfire rate.  Average secondary voltage tracking is reported in PGNs 64882 - 64887 ...";
CM_ SG_ 2631859966 ServiceComponentIdentification "Identification of component needing service.  See Table SPN911_A.";
CM_ SG_ 2631859966 TripGroup2Proprietary "Command signal used to reset proprietary parameters associated with a trip but not defined within this document.

00 Take no action
01 Reset
10 Reserved
11 Not applicable";
CM_ SG_ 2631859966 TireSensorInformation "Command signal used to initiate change in the tire sensor identification information.

00 Take no action
01 Reset
10 Reserved
11 Not applicable";
CM_ SG_ 2631859966 TireConfigInformation "Command signal used to initiate change in the tire configuration of the vehicle system. On receipt of this reset, necessary changes will be made in the tire configuration command information.
00 - Take No Action
01 - Reset
10 - Reserved
11 - Not ...";
CM_ SG_ 2631859966 BinLiftCountReset "Used to reset the bin lift count as reported in PGN 64594.

00 Do not reset
01 Reset
10 Reserved
11 Take no action";
CM_ SG_ 2631859966 TripGroup1 "Command signal used to reset the PGNs and parameters as defined in Table SPN988_A.

00 Take no action
01 Reset
10 Reserved
11 Not applicable";
CM_ BO_ 2566840830 "Retarder Configuration
This map describes the stationary behavior of the retarder.
Note:  Grandfathered definition for systems that implemented this message prior to July, 2010: On change of torque/speed points of more than 10% since last ...";
CM_ SG_ 2566840830 PercentTorqueAtPeakTorquePoint5 "The torque limit that indicates the available retarder torque which can be provided by the retarder at point 5 of the retarder torque map.  Please reference PGN 65249.  The data is transmitted in indicated torque as a percent of the reference ...";
CM_ SG_ 2566840830 ReferenceRetarderTorque "This parameter is the 100% reference value for all defined indicated retarder torque parameters.  It is only defined once and doesn't change if a different retarder torque map becomes valid.";
CM_ SG_ 2566840830 RetarderSpeedAtPeakTorquePoint5 "Please reference PGN 65249";
CM_ SG_ 2566840830 PercentTorqueAtPoint4 "The torque limit that indicates the available retarder torque which can be provided by the retarder at points 3 and 4 of the retarder torque map.  Please reference PGN 65249.  The data is transmitted in indicated torque as a percent of the reference ...";
CM_ SG_ 2566840830 RetarderSpeedAtPoint4 "Retarder speed of point 4 of the engine retarder torque map.  Please reference PGN 65249.";
CM_ SG_ 2566840830 PercentTorqueAtPoint3 "The torque limit that indicates the available retarder torque which can be provided by the retarder at points 3 and 4 of the retarder torque map.  Please reference PGN 65249.  The data is transmitted in indicated torque as a percent of the reference ...";
CM_ SG_ 2566840830 RetarderSpeedAtPoint3 "Retarder speed of point 3 of the engine retarder torque map.  Please reference PGN 65249.";
CM_ SG_ 2566840830 PercentTorqueAtMaxSpeedPoint2 "The torque limit that indicates the available retarder torque which can be provided by the retarder at its maximum speed.  Please reference PGN 65249.  The data is transmitted in indicated torque as a percent of the reference retarder torque.";
CM_ SG_ 2566840830 MaxRetarderSpeedPoint2 "Maximum speed of retarder (Please reference PGN 65249).";
CM_ SG_ 2566840830 PercentTorqueAtIdlePoint1 "The torque limit that indicates the available retarder torque which can be provided by the retarder at idle speed.  The data is transmitted in indicated torque as a percent of the reference retarder torque.";
CM_ SG_ 2566840830 RetarderSpeedAtIdlePoint1 "Please reference PGN 65249";
CM_ SG_ 2566840830 RetarderCtrlMethod "This parameter identifies the number of steps used by the retarder.";
CM_ SG_ 2566840830 RetarderLocation "This parameter defines whether the “torque/speed curve” defined by the retarder configuration message (PGN 65249) is dependent on engine rpm, output shaft rpm, or other parameter.  The data type of this parameter is measured.
0000  (Primary) ...";
CM_ SG_ 2566840830 RetarderType "A vehicle retarder is a supplementary device to the wheel brakes for the driver to better control the vehicle.  The wheel brakes used in the vehicle are not designed for continuous retarding operation.  In a prolonged period of braking, the brakes ...";
CM_ BO_ 2633930238 "Rebuild Information";
CM_ SG_ 2633930238 EngOperationTimeSinceRebuild "The time in engine operation since the last engine rebuild.";
CM_ BO_ 2566844670 "Power Takeoff Information";
CM_ SG_ 2566844670 PowerTakeoffSetSpeed "Rotational velocity selected by operator for device used to transmit engine power to auxiliary equipment.";
CM_ SG_ 2566844670 PowerTakeoffSpeed "Rotational velocity of device used to transmit engine power to auxiliary equipment.";
CM_ SG_ 2566844670 PowerTakeoffOilTemp "Temperature of lubricant in device used to transmit engine power to auxiliary equipment.";
CM_ SG_ 2566844670 OprtrEngPTOGvrnrMmrySelectSwitch "Measured state of the operator’s engine PTO governor memory select switch. This switch selects which of the two available memory locations is to be used to store the dynamically assigned value. This speed will be set using the PTO governor set ...";
CM_ SG_ 2566844670 EngRmtPTOGvrnrVrblSpedCtrlSwitch "Switch signal which indicates that the remote PTO governor toggle switch is in the enabled (ON) position.  If the toggle switch is enabled and other conditions are satisfied then the remote PTO governor feature is activated and the PTO governor will ...";
CM_ SG_ 2566844670 EngRmtPTOGvrnrPrprgrmmdSpdCtrlSw "Switch signal which indicates that the remote PTO governor  toggle switch is in the enabled (ON) position.  If the toggle switch is enabled and other conditions are satisfied then the remote PTO governor feature is activated and the PTO governor ...";
CM_ SG_ 2566844670 EngPTOGvrnrCast_DecelerateSwitch "Switch signal of the PTO control activator which indicates that the activator is in the position to \"coast/decelerate\" the PTO governor set speed.

00 - Off
01 - On
10 - Error
11 - Not available";
CM_ SG_ 2566844670 EngPTOGovernorSetSwitch "Switch signal of the PTO control activator which indicates that the activator is in the position to \"set\" the engine PTO governor set speed.

00 - Off
01 - On
10 - Error
11 - Not available";
CM_ SG_ 2566844670 EngPTOGovernorResumeSwitch "Switch signal of the PTO control activator which indicates that the activator is in the position to \"resume\" a previously established PTO governor set speed.

00 - Off
01 - On
10 - Error
11 - Not available";
CM_ SG_ 2566844670 EngPTOGovernorEnableSwitch "Switch signal which indicates that the PTO governor toggle switch is in the enabled (ON) position and therefore it is possible to manage the PTO control function.

00 - Off
01 - On
10 - Error
11 - Not available";
CM_ SG_ 2566844670 EngPTOGovernorAccelerateSwitch "Switch signal of the PTO control activator which indicates that the activator is in the position to \"accelerate\" the PTO governor set speed.

00 - Off
01 - On
10 - Error
11 - Not available";
CM_ SG_ 2566844670 RmtPTOGvrnrPrprgrmmdSpdCtrlSwtch "Switch signal which indicates that the remote PTO governor toggle switch #2 is in the enabled (ON) position. If the toggle switch is enabled and other conditions are satisfied then the remote PTO governor control feature is activated and the PTO ...";
CM_ SG_ 2566844670 AuxInputIgnoreSwitch "Switch signal which overrides other switch input's ability to disable an engine's operating condition.
00 - Off
01 - On
10 - Error
11 - Not Available
This switch input can be used to prevent the PTO from disengaging if another switch input's ...";
CM_ BO_ 2566770174 "Operator Wiper and Washer Controls Message
Message for items related to the operators controls for the window wipers and washers on the front and rear cab windows";
CM_ SG_ 2566770174 RearWasherFunction "State of operation selected by operator switch for the rear washer.   The parameter, 'Front Operator Washer Switch’ should be used for the control information if this parameter is 'Not Available' and the associated washer still needs to be ...";
CM_ SG_ 2566770174 FrontOperatorWasherSwitch "State of operation selected by operator switch for the washer in front of the operator position. This parameter, 'Front Operator Washer Switch’ should be used for the control information if either of the other washer switch parameters  is 'Not ...";
CM_ SG_ 2566770174 FrontNonoperatorWasherSwitch "State of operation selected by operator switch for the front washer not in front of the operator position.  The parameter, 'Front Operator Washer Switch’ should be used for the control information if this parameter  is 'Not Available' and the ...";
CM_ SG_ 2566770174 RearWiperDelayCtrl "Time between cycles of the rear wiper (i.e. from end of cycle 'n' to start of cycle 'n+1') as selected by the operator control (switch, etc.) in percentage of position with maximum position corresponding to maximum delay selectable.  The parameter, ...";
CM_ SG_ 2566770174 FrontNonoperatorWiperDelayCtrl "Time between cycles of the front non-operator side wiper (i.e. from end of cycle 'n' to start of cycle 'n+1') as selected by the operator control (switch, etc.) in percentage of position with maximum position corresponding to maximum delay ...";
CM_ SG_ 2566770174 FrontOperatorWiperDelayCtrl "Time between cycles of the front operator side wiper (i.e. from end of cycle 'n' to start of cycle 'n+1') as selected by the operator control (switch, etc.) in percentage of position with maximum position corresponding to maximum delay selectable ...";
CM_ SG_ 2566770174 RearWiperSwitch "State of operation selected by operator switch for the rear wiper.  The parameter, 'Front Operator Washer Switch' should be used for the control information if this parameter is 'Not Available' and the associated washer still needs to be controlled.
 ...";
CM_ SG_ 2566770174 FrontOperatorWiperSwitch "State of operation selected by operator switch for the Wiper in front of the operator position. This parameter, 'Front Operator Wiper Switch' should be used for the control information if either of the other wiper switch parameters is 'Not ...";
CM_ SG_ 2566770174 FrontNonoperatorWiperSwitch "State of operation selected by operator switch for the front wiper not in front of the operator position.  The parameter, 'Front Operator Washer Switch' should be used for the control information if this parameter is 'Not Available' and the ...";
CM_ BO_ 2566769662 "Off-Highway Engine Control Selection
Allows for the selection of off-highway engine control modes, as they apply to different modes of engine operation which may be used to aid particular working environments. By offering characteristics suitable ...";
CM_ SG_ 2566769662 EngTorqueCurveSelectionCmd "This parameter will allow selection of a torque curve that is higher than the base curve.
0 - Indicates that this parameter is not presently requesting a different torque curve be used
1 - Indicates that Torque Curve 1 is selected
2 - Indicates ...";
CM_ SG_ 2566769662 EngAltDroopAuxInputSelect "In some off-highway applications it may be desirable to have multiple droop settings available across the range of engine operation.  For example, in an agricultural tractor application, this functionality allows a higher engine speed during low ...";
CM_ SG_ 2566769662 EngAltDroopRemoteAccelSelect "In some off-highway applications it may be desirable to have multiple droop settings available across the range of engine operation.  For example, in an agricultural tractor application, this functionality allows a higher engine speed during low ...";
CM_ SG_ 2566769662 EngAltDroopAccel2Select "In some off-highway applications it may be desirable to have multiple droop settings available across the range of engine operation.  For example, in an agricultural tractor application, this functionality allows a higher engine speed during low ...";
CM_ SG_ 2566769662 EngAltDroopAccel1Select "In some off-highway applications it may be desirable to have multiple droop settings available across the range of engine operation.  For example, in an agricultural tractor application, this functionality allows a higher engine speed during low ...";
CM_ SG_ 2566769662 EngAltRatingSelect "In some off-highway applications it may be desirable to have multiple engine ratings available for selection by the operator. There is the default engine rating, which provides the maximum available power across the range of operation. There are ...";
CM_ SG_ 2566769662 EngAltLowIdleSwitch "Operator switch which selects between two low idle speeds, default and alternate.
The normal programmed low idle is the default low idle, and when the Alternate Low Idle switch is activated, a alternate preprogrammed low idle speed is selected. The ...";
CM_ SG_ 2566769662 EngSynchronizationSwitch "This is the On/Off operation of the Multiple Unit Synchronization functionality. When it is enabled (i.e. On) the master engine will synchronize one or more slave engines to operate at the same speed. This switch position indicates whether this ...";
CM_ SG_ 2566769662 EngAuxGovernorSwitch "This is the On/Off operation of the Auxiliary Governor feature switch. This feature is used to allow engine speed to be controlled by an auxiliary input such as pressure or tailshaft speed. This switch position indicates whether this feature is ...";
CM_ BO_ 2566768638 "Off-Highway Engine Control Selection States
Reports the states of off-highway engine control modes, as they apply to different modes of engine operation which may be used to aid particular working environments. These states provide the controls ...";
CM_ SG_ 2566768638 EngTorqueCurveSelection "This parameter will report the selected torque curve, as indicated by SPN 6796.
0 - Indicates that the engine is using a torque that is not presently selected by SPN 6796
1 - Indicates that Torque Curve 1 is selected
2 - Indicates that Torque ...";
CM_ SG_ 2566768638 EngAltDroopAuxInputSelectState "In some off-highway applications it may be desirable to have multiple droop settings available across the range of engine operation.  For example, in an agricultural tractor application, this functionality allows a higher engine speed during low ...";
CM_ SG_ 2566768638 EngAltDropRemoteAccelSelectState "In some off-highway applications it may be desirable to have multiple droop settings available across the range of engine operation.  For example, in an agricultural tractor application, this functionality allows a higher engine speed during low ...";
CM_ SG_ 2566768638 EngAltDroopAccel2SelectState "In some off-highway applications it may be desirable to have multiple droop settings available across the range of engine operation.  For example, in an agricultural tractor application, this functionality allows a higher engine speed during low ...";
CM_ SG_ 2566768638 EngAltDroopAccel1SelectState "In some off-highway applications it may be desirable to have multiple droop settings available across the range of engine operation.  For example, in an agricultural tractor application, this functionality allows a higher engine speed during low ...";
CM_ SG_ 2566768638 EngAltRatingSelectState "This parameter reflects the control state that has been achieved based on the input from the SPN 2882.  In some off-highway applications it may be desirable to have multiple engine ratings available for selection by the operator.  There is the ...";
CM_ SG_ 2566768638 EngAltLowIdleSelectState "In many applications, it is desirable that an alternate low idle speed setting be made available via switch input. The normal programmed low idle is the default low idle, and when the Alternate Low Idle feature is activated, an alternate ...";
CM_ SG_ 2566768638 EngMultiUnitSyncState "This feature is widely used in Industry to operate multiple engines from a single command source. A master engine will “synchronize” one or more slave engines to operate at the same speed. This feature is requested by an operator switch, this ...";
CM_ SG_ 2566768638 EngAuxGovernorState "This is the Engine Auxiliary Governor feature. This feature is used to allow engine speed to be controlled by an auxiliary input such as pressure or tailshaft speed. This feature is requested by an operator switch, this parameter indicates the state ...";
CM_ BO_ 2365443326 "Operators External Light Controls Message
The message containing the information about the position of the operator's external light control switch(s).  Including switches for the Headlights, turn signals, hazard light, clearance lights, marker ...";
CM_ SG_ 2365443326 OprtorsDesiredDelayedLampOffTime "A 16 bit parameter to be associated with Delayed Off position (1000 binary) of the Main Light Switch.  This parameter indicates the time the operator wishes to have elapse following the Main Light switch being placed in Delayed Off position before ...";
CM_ SG_ 2365443326 OperatorsDesiredBacklight "A 8 bit parameter to indicate the level of back lighting the operator has selected for displays.  This is to be differentiated from the Illumination Brightness Percent (SPN:1487 PGN:53248 Cab Illumination Message) which is sent to the displays to ...";
CM_ SG_ 2365443326 HighLowBeamSwitch "A 2 bit parameter to indicate the selected position of the operator's high/low beam select switch.

00  Low Beam Selected
01  High Beam Selected
10  Error
11  Not available (do not change)";
CM_ SG_ 2365443326 HazardLightSwitch "A 2 bit parameter to indicate the selected position of the operator's hazard light switch.

00   Hazard Lamps to be Off
01   Hazard Lamps to be Flashing
10   Error
11   Not available (do not change)";
CM_ SG_ 2365443326 TurnSignalSwitch "A 4 bit parameter to indicate the selected position of the operator's turn signal switch.
0000   No Turn being signaled
0001   Left Turn to be Flashing
0010   Right turn to be Flashing
0011 - 1101   Reserved
1110   Error (to include both left ...";
CM_ SG_ 2365443326 MainLightSwitch "A 4 bit parameter to indicate the selected position of the operator's main light switch.
0000 Off - The position by which the operator selects that none of the lamps are to be on.
0001 Park On - The position by which the operator selects that the ...";
CM_ SG_ 2365443326 WorkLightSwitch "A 4 bit parameter to indicate the selected position of the operator's work light switch. In Ag applications the work lights are often refereed to as field lights.  In on-highway applications the work lights are often referred to as clearance lights ...";
CM_ BO_ 2566776318 "Maximum Vehicle Speed Limit Status
Reports the possible maximum vehicle speed limits, one through seven, and the applied maximum vehicle speed limit.";
CM_ SG_ 2566776318 AppliedVehicleSpeedLimit "The vehicle speed limit in effect.

251 (0xFB) is used to indicate that a maximum vehicle speed limit is not selected.

See SPN 7420 for alternate resolution.";
CM_ SG_ 2566776318 MaxVehicleSpeedLimit7 "The highest of the seven lowest vehicle speed limits";
CM_ SG_ 2566776318 MaxVehicleSpeedLimit6 "The highest of the six lowest vehicle speed limits";
CM_ SG_ 2566776318 MaxVehicleSpeedLimit5 "The highest of the five lowest vehicle speed limits";
CM_ SG_ 2566776318 MaxVehicleSpeedLimit4 "The highest of the four lowest vehicle speed limits";
CM_ SG_ 2566776318 MaxVehicleSpeedLimit3 "The highest of the three lowest vehicle speed limits";
CM_ SG_ 2566776318 MaxVehicleSpeedLimit2 "The highest of the two lowest vehicle speed limits";
CM_ SG_ 2566776318 MaxVehicleSpeedLimit1 "The lowest Maximum Vehicle Speed Limit. This value is the similar to SPN 74. However, SPN 74 was not specifically defined to convey  the applied vehicle speed limit or what was possible to be applied. This new SPN is the lowest vehicle speed limit ...";
CM_ BO_ 2566802686 "Military Lighting Command
The message contains parameters that control military specific lights.";
CM_ SG_ 2566802686 OprtrsBlackOutIntensitySelection "Operators Selection of lamp intensity in black out mode.  This parameter provides the operators selected illumination intensity as a percentage of available full scale.  This parameter would be typically used as a dash or instrument cluster ...";
CM_ SG_ 2566802686 BlackOutWorkLampSelect "Black Out Work Lamp Selection

00 Off
01 On
10 Reserved
11 Not Supported";
CM_ SG_ 2566802686 NightVisionIlluminatorSelect "Night Vision Illuminator Selection

00 Off
01 On
10 Reserved
11 Not Supported";
CM_ SG_ 2566802686 BlackOutBrake_StopLampSelect "Black Out Brake/Stop Lamp Selection

00 Off
01 On
10 Reserved
11 Not Supported";
CM_ SG_ 2566802686 ConvoyDrivingLampSelect "Black Out Convoy Driving Lamp Selection

00 Off
01 On
10 Reserved
11 Not Supported";
CM_ SG_ 2566802686 ConvoyLampSelect "Black Out Convoy Lamp Selection

00 Off
01 On
10 Reserved
11 Not Supported";
CM_ SG_ 2566802686 FrontBlackOutMarkerLampSelect "Front Black Out Marker Lamp Selection

00 Off
01 On
10 Reserved
11 Not Supported";
CM_ SG_ 2566802686 RearBlackOutMarkerSelect "Rear Black Out Marker Selection

00 Off
01 On
10 Reserved
11 Not Supported";
CM_ BO_ 2566774014 "Marine Control Information
This messages contains marine vessel control information for the engine";
CM_ SG_ 2566774014 SlowVesselModeStatus "The status of the Slow Vessel Mode.  Slow Vessel Mode puts the engine in a lower-than-normal low idle speed during docking or other slow vessel operations.
00 Slow vessel mode is OFF.
01 Slow vessel mode is ACTIVE.
10 Reserved
11 Take no action
 ...";
CM_ SG_ 2566774014 TrollingModeStatus "The status of the Trolling Mode.  Trolling mode limits the top speed.  Full range travel of the throttle level spans from low idle engine speed to maximum trolling speed.
00 Trolling mode is OFF.
01 Trolling mode is ACTIVE.
10 Reserved
11 Take ...";
CM_ SG_ 2566774014 EngThrttlSynchrnzationModeStatus "The status of the Throttle Synchronization Mode. Throttle Synchronization Mode is used to indicate which throttle, if any, is currently being used for the synchronized throttle.
0000 Not Synchronized
0001 Synchronized Center
0010 Synchronized ...";
CM_ BO_ 2566823166 "Main Bearing Temperature 3";
CM_ SG_ 2566823166 EngMainBearing12Temp "Temperature of the main bearing which supports the crankshaft of the engine.";
CM_ SG_ 2566823166 EngMainBearing11Temp "Temperature of the main bearing which supports the crankshaft of the engine.";
CM_ SG_ 2566823166 EngMainBearing10Temp "Temperature of the main bearing which supports the crankshaft of the engine.";
CM_ SG_ 2566823166 EngMainBearing9Temp "Temperature of the main bearing which supports the crankshaft of the engine.";
CM_ BO_ 2566823422 "Main Bearing Temperature 2";
CM_ SG_ 2566823422 EngMainBearing8Temp "Temperature of the main bearing which supports the crankshaft of the engine.";
CM_ SG_ 2566823422 EngMainBearing7Temp "Temperature of the main bearing which supports the crankshaft of the engine.";
CM_ SG_ 2566823422 EngMainBearing6Temp "Temperature of the main bearing which supports the crankshaft of the engine.";
CM_ SG_ 2566823422 EngMainBearing5Temp "Temperature of the main bearing which supports the crankshaft of the engine.";
CM_ BO_ 2566823678 "Main Bearing Temperature 1";
CM_ SG_ 2566823678 EngMainBearing4Temp "Temperature of the main bearing which supports the crankshaft of the engine.";
CM_ SG_ 2566823678 EngMainBearing3Temp "Temperature of the main bearing which supports the crankshaft of the engine.";
CM_ SG_ 2566823678 EngMainBearing2Temp "Temperature of the main bearing which supports the crankshaft of the engine.";
CM_ SG_ 2566823678 EngMainBearing1Temp "Temperature of the main bearing which supports the crankshaft of the engine.";
CM_ BO_ 2432595710 "Laser Leveling System Vertical Position Display Data";
CM_ SG_ 2432595710 DisplayDeadbands "Sets Display Deadbands mode.

0000 - Narrow = +/- 4.5mm
0001 - Standard = +/- 12mm
0010 - Wide = +/- 24mm
0011 - 1110 Reserved
1111 Not Available";
CM_ SG_ 2432595710 LEDPatternCtrl "Sets LED Pattern control mode on laser leveling systems.

0000 - 5 Channel
0001 - Offset
0010 - 7 Channel
0011 - 1110 Reserved
1111 Not Available";
CM_ SG_ 2432595710 LEDDisplayDeadbandCtrl "This parameter informs the system what the selected Display deadband will be.
0000    +/- 4.5 mm  (0.015 feet, 0.18 inches)
0001    +/- 12 mm   (0.040 feet, 0.45 inches)
0010    +/- 24 mm   (0.080 feet, 0.96 inches)
0011    +/- 5  mm    (0.017 ...";
CM_ SG_ 2432595710 LEDDisplayModeCtrl "This parameter informs the system what the selected Display mode will be.
0000 - Center On-Grade Display Mode 1 ( 5 CHANNEL )
0001 - Offset On-Grade Display Mode
0010 - Center On-Grade Display Mode 2 ( 7 CHANNEL )
0011 - 1110 Reserved
1111 - ...";
CM_ SG_ 2432595710 LEDDisplayData1 "Informs display devices how to display the current vertical position.
Values which are less than 128 decimal are bit-mapped values and any combination of these values is considered a valid value.  For example communicating the \"High Fine LED on\" ...";
CM_ BO_ 2365486590 "Laser Leveling System Vertical Deviation";
CM_ SG_ 2365486590 AbsLaserStrikePos "Laser Strike location on the survey type  laser receiver.";
CM_ SG_ 2365486590 LaserStrikeDataLatency "Time from laser strike to CAN message transmission.  This parameter will be reported by survey receiver type devices only. Byte 3 (SPN 2576) of  PGN 65141 identifies the type of Laser Receiver.";
CM_ SG_ 2365486590 LaserReceiverType "Identifies which type of Laser Receiver transmitted the message.

0 = Reserved 
1 = Linear Laser Receiver
2 = 1 Meter Survey Receiver
3 = 2 Meter Survey Receiver
4 = 2.5 Meter Survey Receiver
5-250 = Reserved";
CM_ SG_ 2365486590 LaserStrikeVerticalDeviation "The calculated distance from the laser strike position to the current land leveling system reference point.";
CM_ BO_ 2365485566 "Laser Tracer Position";
CM_ SG_ 2365485566 LaserTracerInformation "Provides the status of the laser tracer to the operator.
00000001 Laser power is on
00000010 Laser is ready
00000100 Valid target (1 = yes)
00001000 Previous pass (1 = yes)
00010000 Stringline (1 = yes)
00100000 Curb (1 = yes)
All other ...";
CM_ SG_ 2365485566 LEDDisplayData2 "Informs display devices how to display the current position of the laser tracer.
Values which are less than 128 decimal are bit-mapped values and any combination of these values is considered a valid value.  For example communicating the \"Up LED ...";
CM_ SG_ 2365485566 LaserTracerHorizontalDeviation "The calculated percent deviation between the target distance and the center of the laser tracer.";
CM_ SG_ 2365485566 LaserTracerVerticalDistance "The elevation of the laser tracer sensor in a laser leveling system.";
CM_ SG_ 2365485566 LaserTracerTargetDeviation "The calculated distance for the laser target to the current laser tracer reference point.

Parameter specific parameter: 0xFE03 indicates that the sensor can not sense the laser";
CM_ BO_ 2633939454 "Trip Fuel Information (Liquid)";
CM_ SG_ 2633939454 TripDriveFuelEconomy "Trip drive fuel economy is equal to the distance traveled by vehicle in the drive state (engine speed greater than zero, vehicle speed greater than or equal to 2 km/h, and neither the PTO or remote PTO governors are controlling engine power output) ...";
CM_ SG_ 2633939454 TripCruiseFuelUsed "Total fuel consumed while the engine is in the cruise hold state since the last trip reset.  If both cruise control and VSL (vehicle speed limiter) are commanding the same amount of fuel, the cruise control is deemed the active torque mode and fuel ...";
CM_ SG_ 2633939454 TripVehicleIdleFuelUsed "Total fuel consumed while neither the PTO or remote PTO governor is in the hold state, the engine speed is greater than zero, and vehicle speed is less than 2 km/h, since the last trip reset.
In marine applications, this parameter is defined as the ...";
CM_ SG_ 2633939454 TripPTOGovernorNonmovingFuelUsed "Total fuel consumed while either the PTO or remote PTO governors are in the hold state, the engine speed is greater than zero, and vehicle speed is less than 2 km/h, since the last trip reset.
NOTE—This parameter is intended for liquid fueled ...";
CM_ SG_ 2633939454 TripPTOGovernorMovingFuelUsed "Total fuel consumed while either the PTO or remote PTO governors are in the hold state, the engine speed is greater than zero, and vehicle speed is greater than or equal to 2 km/h, since the last trip reset.
NOTE—This parameter is intended for ...";
CM_ SG_ 2633939454 TripDriveFuelUsed "Total fuel consumed while the engine speed is greater than zero, vehicle speed is greater than or equal to 2 km/h, and neither the PTO or the remote PTO is controlling the engine power output, since the last trip reset.
NOTE—This parameter is ...";
CM_ BO_ 2365486334 "Modify Leveling System Control Set Point";
CM_ SG_ 2365486334 BldeHeightSetPointHighResolution "High resolution for the laser guided blade set point.  The high resolution required for more accurate control and 'accurate' unit conversions.

Negative values are below grade, positive values are above grade, zero is on grade.";
CM_ SG_ 2365486334 ModifyLevelingSystemSetPoint "Used to control and coordinate the set point for the leveling system.
Operating Range: -3200 to +3200 mm, negative values are below current position, positive values are above current position, zero is no change.
Parameter specific parameter:
 ...";
CM_ BO_ 2364542462 "Land Leveling System Operational Information
Group of operational parameters associated with the Land Leveling System, such as switch states.    This is provided to the device controlling the blade, and is usually directed at the primary land ...";
CM_ SG_ 2364542462 StElvtnSensor2ReferenceElevation "Command from a display or other external device (i.e. remote switch) to the land leveling system controller instructing the controller to set the reference elvation based on data received from the corresponding land leveling sensor.
00 = Do not Set ...";
CM_ SG_ 2364542462 StElvtnSensor1ReferenceElevation "Command from a display or other external device (i.e. remote switch) to the land leveling system controller instructing the controller to set the reference elvation based on data received from the corresponding land leveling sensor.
00 = Do not Set ...";
CM_ SG_ 2364542462 SdshftDsrdBldeOffsetOperatorCtrl "This parameter indicates the side-shift blade control mode operator control state the user has set for the land leveling system.  When an implement moves in a side-shift direction, it moves from side to side, usually along its longitudinal axis.
 ...";
CM_ SG_ 2364542462 SdshiftBladeCtrlModeOperatorCtrl "This parameter indicates the side-shift offset operator control state the user has set for the land leveling system. When an implement moves in a side-shift direction, it moves from side to side, usually along its longitudinal axis. The desired ...";
CM_ SG_ 2364542462 RghtDsredBladeOffsetOperatorCtrl "This parameter indicates the right blade offset operator control state the user has set for the land leveling system.  The right desired blade offset value is the offset measured from a given reference point to the bottom right edge of the blade ...";
CM_ SG_ 2364542462 LftDsiredBladeOffsetOperatorCtrl "This parameter indicates the left blade offset operator control state the user has set for the land leveling system.  The left desired blade offset value is the offset measured from a given reference point to the bottom left edge of the blade. This ...";
CM_ SG_ 2364542462 RightBladeCtrlModeOperatorCtrl "This parameter indicates the right blade control mode operator control state the user has set for the land leveling system.  The operator control value directly relates to the current operator control state correlating to the left edge of the blade ...";
CM_ SG_ 2364542462 LeftBladeCtrlModeOperatorCtrl "This parameter indicates the left blade control mode operator control state the user has set for the land leveling system.  The operator control value directly relates to the current operator control state correlating to the left edge of the blade ...";
CM_ SG_ 2364542462 BladeAutoModeCmd "Allows other controllers to command to the primary control system what they think is the appropriate auto control mode to be engaged in, based on the information they have available to them.  When in automatic mode, the blade automatically adjusts ...";
CM_ SG_ 2364542462 DesiredGradeOffsetSwitch "Indicates the grade offset switch state the user has set for the land leveling system.  The desired grade offset value is the vertical offset measured from a given elevation reference point to the bottom edge of the blade.  This parameter is ...";
CM_ SG_ 2364542462 BladeCtrlModeSwitch "Indicates the blade control mode switch state the user has set for the land leveling system.  The switch value directly correlates to the current switch state, regardless of the switch being used.  This parameter is intended for use in systems using ...";
CM_ BO_ 2365486078 "Laser Receiver Mast Position";
CM_ SG_ 2365486078 MastPos "Used to monitor the position of the sensor attached to the land leveling mast.";
CM_ BO_ 2633937918 "Fuel Information 1 (Liquid)";
CM_ SG_ 2633937918 FlexibleFuelPercentage "Measured signal that indicates the percentage of alcohol in the fuel currently being used.  0% means no alcohol in fuel, 100% means alcohol as fuel and nothing else.
EXAMPLE: If a Bi-fuel vehicle has less than 10% ethanol in the gasoline/petrol, ...";
CM_ SG_ 2633937918 TripAverageFuelRate "Average fuel rate, equal to trip fuel divided by trip time while the engine speed is above zero, since the last trip reset.  This includes idle, engine PTO governor (both moving and non-moving) and drive operation but excludes ignition-on time while ...";
CM_ SG_ 2633937918 TotalEngPTOGovernorFuelUsed "Total fuel used while the PTO or remote PTO governors are in the hold state and engine speed is above zero, over the life of the engine.

NOTE—This parameter is intended for liquid fueled engines.  See SPN 1030 for alternate resolution.";
CM_ BO_ 2566845182 "Fuel Economy (Liquid)";
CM_ SG_ 2566845182 EngThrottleValve2Pos "The sensed position feedback of the valve, coming from a second electrical actuator for a second throttle plate, used to regulate the supply of a fluid, usually air or fuel//air mixture.  0% represents no supply and 100% is full supply. SPN 51 is ...";
CM_ SG_ 2566845182 EngThrottleValve1Pos "The position of the valve used to regulate the supply of a fluid, usually air or fuel/air mixture, to an engine.  0% represents no supply and 100% is full supply.";
CM_ SG_ 2566845182 EngAverageFuelEconomy "Average of instantaneous fuel economy for that segment of vehicle operation of interest.";
CM_ SG_ 2566845182 EngInstantaneousFuelEconomy "Current fuel economy at current vehicle velocity.

0xFB00 = Infinite (for example, during engine motoring)";
CM_ SG_ 2566845182 EngFuelRate "Amount of fuel consumed by engine per unit of time.

NOTE - See SPN 1600 for alternate resolution.";
CM_ BO_ 2566842878 "Fuel Consumption (Liquid) 1
Engine fuel consumption accumulators.  See PGN 64777 for alternate resolution.";
CM_ SG_ 2566842878 EngTotalFuelUsed "Accumulated amount of fuel used during vehicle operation.  See SPN 5054 for alternate resolution.";
CM_ SG_ 2566842878 EngTripFuel "Fuel consumed during all or part of a journey.  See SPN 5053 for alternate resolution.";
CM_ BO_ 2633883646 "Front Wheel Drive Status
Front wheel drive ECU information";
CM_ SG_ 2633883646 FrontWheelDriveActuatorStatus "Feedback on the front wheel drive actuator.

00 Front Wheel Drive Actuator not engaged
01 Front Wheel Drive Actuator engaged
10 Error
11 Not Available";
CM_ BO_ 2633880062 "FMS-standard Interface Identity/Capabilities
Information which specifies the capabilities of the Fleet Management System (FMS) - standard interface device. This PGN typically is sourced from the network interconnect FMS - standard interface device.";
CM_ SG_ 2633880062 FMSstandardSWversionSupported "Information that identifies which issue level of the FMS-standard document the software included in the FMS gateway supports. Four bytes, representing xx.yy type revision level identification.
Information to be ASCII equivalent of the numeric ...";
CM_ SG_ 2633880062 FMSstandardRequestsSupported "Status signal which indicates if the FMS Vehicle Interface (FMS Gateway) will respond to requests from the FMS device for the PGNs listed in the FMS Interface Specification.
This mode is to support FMS  gateway devices that only operate in a ...";
CM_ SG_ 2633880062 FMSstandardDiagnosticsSupported "Status signal which indicates if the FMS Vehicle Interface (FMS Gateway) supports the handling of diagnostic messages from the vehicle network onto the FMS network.
The FMS gateway does NOT support the re-broadcast of diagnostics messages present ...";
CM_ BO_ 2566806526 "Forward Lane Image 2";
CM_ SG_ 2566806526 DrverAlertnessWarningSystemState "Indicates the various system state in the driver alertness warning system. This signal can be used independent of the technology and ECU used to estimate the driver alertness condition.
000 = System installed but disabled
001 = Initializing
010 = ...";
CM_ SG_ 2566806526 DriverAlertnessLevel "Indicates the alertness level of the driver measured by the driver alertness warning system. 100 % means driver is fully attentive. This signal can be used independent of the technology and ECU used to estimate the driver alertness condition.";
CM_ SG_ 2566806526 LnDpartureIndicationEnableStatus "Indicates whether lane departure indication is active.

00 Lane Departure indication disabled
01 Lane Departure Indication enabled 
10 Reserved
11 Not Used";
CM_ SG_ 2566806526 LaneTrackingStatusLeftSide "Indicates whether the left side is tracking lane.

00 Not Tracking Left side
01 Tracking Left side
10 Reserved
11 Don't care/Take no action";
CM_ SG_ 2566806526 LaneTrackingStatusRightSide "Indicates whether right side is tracking lane.

00 Not Tracking Right side
01 Tracking Right side
10 Reserved
11 Don't Care/take no action";
CM_ BO_ 2431649790 "Forward Lane Image 1";
CM_ SG_ 2431649790 LaneDepartureImminentLeftSide "Indicates departure imminent on left side of lane.

00 Not imminent
01 Imminent
10 Reserved
11 Not used";
CM_ SG_ 2431649790 LaneDepartureImminentRightSide "Indicates departure imminent on right side of lane.

00 Not imminent
01 Imminent
10 Reserved
11 Not Used";
CM_ SG_ 2431649790 LaneDepartureRight "Indicates that the middle of vehicle departs the lane on the right side. The parameter indicates that the vehicle is changing the lane to the right.
00   Middle of the vehicle does not depart the lane to the right side
01   Middle of the vehicle ...";
CM_ SG_ 2431649790 LaneDepartureLeft "Indicates that the middle of vehicle departs the lane on the left side. The parameter indicates that the vehicle is changing the lane to the left.
00   Middle of the vehicle does not depart the lane to the left side
01   Middle of the vehicle ...";
CM_ SG_ 2431649790 DriverAlertnessWarning "Indicates when a distracted driving condition is detected. This signal can be used independent of the technology and ECU used to estimate the distracted driver condition.
000 = No distracted driving condition detected
001 = Level 1 - Mild ...";
CM_ BO_ 2633929214 "Fuel Leakage";
CM_ SG_ 2633929214 EngFuelLeakage2 "Status signal which indicates fuel leakage in the fuel rail of the engine. Location can be either before or after the fuel pump.  

00 - no leakage detected
01 - leakage detected
10 - Error
11 - Not available";
CM_ SG_ 2633929214 EngFuelLeakage1 "Status signal which indicates fuel leakage in the fuel rail of the engine. Location can be either before or after the fuel pump.  

00 - no leakage detected
01 - leakage detected
10 - Error
11 - Not available";
CM_ BO_ 2566831614 "Fan Drive #1
This parameter group transfers status and measured information for an engine coolant fan.  This PGN is used for the primary fan if there are more than one fan in the syste.  PGN 64817 may be used for a second fan.";
CM_ SG_ 2566831614 FanDriveBypassCmdStatus "Status of the Fan Drive Bypass Command as being commanded by the ECU.  The fan drive bypass diverts pump pressure away from the hydraulic motor to maintain the fan drive pressure.  0% is defined as no bypass (i.e. diverting no fan drive pressure) ...";
CM_ SG_ 2566831614 HydFanMotorPress "The hydraulic pressure used to drive the fan system, sensed before the hydraulic fan motor.";
CM_ SG_ 2566831614 FanSpeed "The speed of the fan associated with engine coolant system.";
CM_ SG_ 2566831614 FanDriveState "This parameter is used to indicate the current state or mode of operation by the fan drive.
0000 Fan off
0001 Engine system-General
0010 Excessive engine air temperature
0011 Excessive engine oil temperature
0100 Excessive engine coolant ...";
CM_ SG_ 2566831614 EstPercentFanSpeed "Estimated fan speed as a ratio of the fan drive (current speed) to the fully engaged fan drive (maximum fan speed).  A two state fan (off/on) will use 0% and 100% respectively.  A three state fan (off/intermediate/on) will use 0%, 50% and 100% ...";
CM_ BO_ 2566820094 "Engine Torque History
NOTE - The torque history PGN is variable in length and may contain up to 125 torque history records.  Each torque history record MUST BE 38 bytes in length.  Any unused bytes must be 0xFF.
The last six bytes of each record ...";
CM_ SG_ 2566820094 EngTorqueLimit6AxleInput "Limit applied to the engine output torque based on the maximum allowable axle input torque.  Axle input torque is calculated as the current engine torque output multiplied by the transmission gear ratio.";
CM_ SG_ 2566820094 EngTorqueLimit5Switch "Limit applied to the engine output torque based on activation of an ECU switch input.";
CM_ SG_ 2566820094 EngTorqueLimit4Trans "Limit applied to the engine output torque during vehicle operation in transmission gear ratios numerically less than or equal to transmission gear ratio 3 (see SPN 1259).";
CM_ SG_ 2566820094 EngTorqueLimit3Trans "Limit applied to the engine output torque during vehicle operation in transmission gear ratios numerically less than or equal to transmission gear ratio 2 (see SPN 1257) and numerically greater than transmission gear ratio 3 (see.SPN 1259).  For ...";
CM_ SG_ 2566820094 TransGearRatio3 "Gear ratio value stored in the ECU that is used to define a range of transmission gears for which a limit is applied to the engine output torque.  Transmission gear ratio 3 should be the numerically highest transmission gear ratio breakpoint less ...";
CM_ SG_ 2566820094 EngTorqueLimit2Trans "Limit applied to the engine output torque during vehicle operation in transmission gear ratios numerically less than or equal to transmission gear ratio 1 (see SPN 1255) and numerically greater than transmission gear ratio 2 (see.SPN 1257).  For ...";
CM_ SG_ 2566820094 TransGearRatio2 "Gear ratio value stored in the ECU that is used to define a range of transmission gears for which a limit is applied to the engine output torque.  Transmission gear ratio 2 should be the numerically highest transmission gear ratio breakpoint less ...";
CM_ SG_ 2566820094 EngTorqueLimit1Trans "Limit applied to the engine output torque during vehicle operation in transmission gear ratios numerically greater than transmission gear ratio 1 (see SPN 1255).";
CM_ SG_ 2566820094 TransGearRatio1 "Gear ratio value stored in the ECU that is used to define a range of transmission gears for which a limit is applied to the engine output torque.  Transmission gear ratio 1 should be the numerically highest transmission gear ratio breakpoint that ...";
CM_ SG_ 2566820094 EngTorqueLimitFeature "Torque limit rating described in the current record.
000 Reserved
001 Highest torque rating
010 First torque rating
011 Previous torque rating (rating prior to the current rating)
100 Current torque rating
101-110 Reserved
111 Not available
 ...";
CM_ SG_ 2566820094 TorqueLimitingFeatureStatus "Status of an ECU feature which limits the torque output of the engine. 

00 - Disabled
01 - Enabled
10 - Error
11 - Not available";
CM_ SG_ 2566820094 CalibRecordDurationTime "Duration in hours for which the engine operated in the conditions captured in the current record.";
CM_ SG_ 2566820094 CalibRecordStartYear "Calendar year timestamp when an ECU record was established.

NOTE - A value of 0 for the year identifies the year 1985; a value of 1 identifies 1986; etc.";
CM_ SG_ 2566820094 CalibRecordStartDay "Calendar day timestamp when an ECU record was established.

NOTE - A value of 0 for the date is null.  The values 1, 2, 3, and 4 are used to identify the first day of the month; 5, 6, 7, and 8 identify the second day of the month; etc.";
CM_ SG_ 2566820094 CalibRecordStartMonth "Calendar month timestamp when an ECU record was established.

NOTE - A value of 0 for the month is null.  The value 1 identifies January; 2 identifies February; etc.";
CM_ SG_ 2566820094 EngPeakTorque2 "Maximum torque output of the current ECU calibration when the engine operates on torque curve 2.  For calibrations that support two torque curves, this parameter shall be assigned the value of the higher curve.  For calibrations that support only ...";
CM_ SG_ 2566820094 EngPeakTorque1 "Maximum torque output of the current ECU calibration when the engine operates on torque curve 1.  For calibrations that support two torque curves, this parameter shall be assigned the value of the lower curve.  For calibrations that support only one ...";
CM_ SG_ 2566820094 EngPower "Advertised engine power capability.  Advertised power is what a customer will find on a sales sheet for an engine with a certain calibration.";
CM_ SG_ 2566820094 NumberOfEngTorqueHistoryRecords "Number of torque history records contained in the engine torque history PGN.  A value of 0 is broadcast if no torque history records are stored in the ECU.";
CM_ BO_ 2364542206 "Electronic Transmission Controller #8
Electronic Transmission Controller #8";
CM_ SG_ 2364542206 TransClutch_ConverterInputSpeed "Rotational velocity of the input to a transmission's master clutch or torque converter. In most cases the rotational velocity will be the same as engine flywheel speed unless there is an intermediate device, such as a power divider, between the ...";
CM_ SG_ 2364542206 TransTorqueConverterRatio "Ratio of the transmissions torque converter output torque to torque converter input torque at current speed.
The ratio of 1.000 ( 03 E8 hex ) indicates torque converter lockup.
If the ratio is less than 1 and the ratio can not be properly ...";
CM_ BO_ 2566802174 "Electronic Transmission Controller 7
Transmission status information from the transmission controller to network.";
CM_ SG_ 2566802174 TransAutoNeutralSt "Indicates the transmission response to a Neutral request from SPN 7695 [Transmission Auto-Neutral (Manual Return) Request] or other vehicle input configured for Auto-Neutral (Manual Return) functionality. The applicability of the states and state ...";
CM_ SG_ 2566802174 TransWarningIndicator "Signal from transmission indicating that some aspect of its operation is not functioning correctly, and as a result, transmission operation may be altered or restricted.  The indicator is typically a lamp.  Distinctions in meaning between the ...";
CM_ SG_ 2566802174 TrnsRverseGearShiftInhibitStatus "Reflects the status of transmission reverse inhibit activity in response to requests via SPN 4242 - Transmission Reverse Gear Shift Inhibit Request.  Typically broadcast by the transmission controller.
00 = Reverse gear shifts are currently allowed
 ...";
CM_ SG_ 2566802174 TransMode8Indicator "This state signal is the transmission’s indication that it is operating under transmission mode 8 (SPN 4249) as commanded via the TC1 message (PGN 256).  The definition of the transmission mode is left to the discretion of the transmission ...";
CM_ SG_ 2566802174 TransMode7Indicator "This state signal is the transmission’s indication that it is operating under transmission mode 7 (SPN 4248) as commanded via the TC1 message (PGN 256).  The definition of the transmission mode is left to the discretion of the transmission ...";
CM_ SG_ 2566802174 TransMode6Indicator "This state signal is the transmission’s indication that it is operating under transmission mode 6 (SPN 4247) as commanded via the TC1 message (PGN 256).  The definition of the transmission mode is left to the discretion of the transmission ...";
CM_ SG_ 2566802174 TransMode5Indicator "This state signal is the transmission’s indication that it is operating under transmission mode 5 (SPN 4246) as commanded via the TC1 message (PGN 256).  The definition of the transmission mode is left to the discretion of the transmission ...";
CM_ SG_ 2566802174 TransRequestedGearFeedback "Feedback of the SPN 525 Transmission Requested Gear input as received from the shift selector, ABS or engine via PGN 256, Transmission Control 1 (TC1) or other transmission selector input.  Scaling, values and parameter specific indicators are ...";
CM_ SG_ 2566802174 TransMode1Indicator "This state signal is the transmission’s indication that it is operating under transmission mode 1 (SPN 1852) as commanded via the TC1 message (PGN 256).  The definition of the transmission mode is left to the discretion of the transmission ...";
CM_ SG_ 2566802174 TransMode2Indicator "This state signal is the transmission’s indication that it is operating under transmission mode 2 (SPN 1853) as commanded via the TC1 message (PGN 256).  The definition of the transmission mode is left to the discretion of the transmission ...";
CM_ SG_ 2566802174 TransMode3Indicator "This state signal is the transmission’s indication that it is operating under transmission mode 3 (SPN 1854) as commanded via the TC1 message (PGN 256).  The definition of the transmission mode is left to the discretion of the transmission ...";
CM_ SG_ 2566802174 TransMode4Indicator "This state signal is the transmission’s indication that it is operating under transmission mode 4 (SPN 1855) as commanded via the TC1 message (PGN 256).  The definition of the transmission mode is left to the discretion of the transmission ...";
CM_ SG_ 2566802174 TransShiftInhibitIndicator "State signal indicating a transmission request for the Shift Inhibit Indicator to be active or inactive. The shift inhibit indicator can be of lamp or text form, located on (but not limited to) the shift console, instrument cluster, or cab display ...";
CM_ SG_ 2566802174 TransEngCrankEnable "State signal from the transmission indicating if the transmission’s status is such that engine cranking is allowed (i.e.  at a minimum, transmission is in neutral and the driveline is disengaged).  As sender of this information, the transmission is ...";
CM_ SG_ 2566802174 ActiveShiftConsoleIndicator "Signal from transmission control unit indicating which shift console (primary or secondary) it currently considers as the active shift selector input.
00        Primary shift console is active
01        Secondary shift console is active
10 ...";
CM_ SG_ 2566802174 TransReadyForBrakeRelease "This parameter indicates that enough torque / motive force is available at the transmission output shaft to release all the brakes without a risk of unintentional movement in the opposite direction.
00 - Transmission Not Ready for Brake Release
01 ...";
CM_ SG_ 2566802174 TrnsRqstedRangeDisplayFlashState "State signal indicating a transmission request for the display of the Transmission Requested Range parameter (SPN 162) to flash or not to flash. The ‘Transmission Requested Range Display Flash State’ indicator can be utilized by (but not limited to) ...";
CM_ SG_ 2566802174 TrnsRqstedRangeDisplayBlankState "State signal indicating a transmission request for the display of the Transmission Requested Range parameter (SPN162) to be blanked or not blanked.  The ‘Transmission Requested Range Display Blank State’ indicator can be utilized by (but not limited ...";
CM_ SG_ 2566802174 TransServiceIndicator "Signal from transmission indicating that some aspect of the gearbox requires servicing, such as the oil, filter, clutch(es) or other component.
00  Transmission Service Indicator is off
01  Transmission Service Indicator is on continuously
10 ...";
CM_ SG_ 2566802174 TransAirSupplyPressIndicator "Indicates whether transmission air supply is sufficient
000   Normal Pressure Range - The transmission supply air pressure is within the normal operational range.
001   Low pressure - The transmission supply air pressure is within a range that may ...";
CM_ SG_ 2566802174 TransMode10Indicator "Indicates that the transmission is operating under transmission mode 10 (SPN 6570) as commanded via the TC2 message (PGN 3328). The definition of the transmission mode is left to the discretion of the transmission manufacturer.
00 Transmission Mode ...";
CM_ SG_ 2566802174 TransMode9Indicator "Indicates that the transmission is operating under transmission mode 9 (SPN 6569) as commanded via the TC2 message (PGN 3328). The definition of the transmission mode is left to the discretion of the transmission manufacturer.
00 Transmission Mode ...";
CM_ SG_ 2566802174 TrnsCrrentRangeDisplayBlankState "State signal indicating a transmission request for the display of the Transmission Current Range parameter (SPN 163) to be blanked or not blanked.  The 'Transmission Current Range Display Blank State' indicator can be utilized by (but not limited ...";
CM_ BO_ 2633935870 "Electronic Transmission Controller 6";
CM_ SG_ 2633935870 ClutchLifeRemaining "Signal which indicates the actual clutch life remaining in percent. One hundred percent means the clutch is brand new and zero percent means the clutch is at the end of its life.";
CM_ SG_ 2633935870 LowestPossibleGear "The transmission calculates this gear continuously.  Together with the highest possible gear (see SPN 1115), it enables a management computer to know the exact range of available gears.";
CM_ SG_ 2633935870 HighestPossibleGear "The transmission calculates this gear continuously.  Together with the lowest possible gear (see  SPN 1114), it enables a management computer to know the exact range of available gears.";
CM_ SG_ 2633935870 RecommendedGear "The transmission calculates this gear continuously.  In dangerous situations this gear may be selected to gain back vehicle control.";
CM_ BO_ 2633942014 "Electronic Transmission Controller 5";
CM_ SG_ 2633942014 TransForwardDirectionSwitch "Identifies the status of the switch that indicates forward direction.

00 - Off
01 - On
10 - Error
11 - Not available";
CM_ SG_ 2633942014 TransNeutralSwitch "Identifies the status of the switch that indicates neutral.

00 - Off
01 - On
10 - Error
11 - Not available";
CM_ SG_ 2633942014 TransReverseDirectionSwitch "Identifies the status of the switch that indicates reverse direction.

00 - Off
01 - On
10 - Error
11 - Not available";
CM_ SG_ 2633942014 TransLowRangeSenseSwitch "Identifies the status of the switch that represents low range.

00 - Off
01 - On
10 - Error
11 - Not available";
CM_ SG_ 2633942014 TransHighRangeSenseSwitch "Identifies the status of the switch that represents high range.

00 - Off
01 - On
10 - Error
11 - Not available";
CM_ BO_ 2633942526 "Electronic Transmission Controller 4";
CM_ SG_ 2633942526 TransSynchronizerBrakeValue "The current modulated value for the air supply to the synchronizer brake.";
CM_ SG_ 2633942526 TransSynchronizerClutchValue "The current modulated value for the air supply to the synchronizer clutch.";
CM_ BO_ 2633943038 "Electronic Transmission Controller 3";
CM_ SG_ 2633943038 TransInertiaBrakeActuator "Identifies the status of the actuator that controls the inertia brake.

00 - Off
01 - On
10 - Error
11 - Not available";
CM_ SG_ 2633943038 TransDefuelActuator "Identifies the status of the actuator that controls the engine defuel mechanism.

00 - Off
01 - On
10 - Error
11 - Not available";
CM_ SG_ 2633943038 TransLockupClutchActuator "Identifies the status of the actuator that controls the torque converter lockup clutch.

00 - Off
01 - On
10 - Error
11 - Not available";
CM_ SG_ 2633943038 TransClutchActuator "Identifies the status of the actuator that controls the clutch.

00 - Off
01 - On
10 - Error
11 - Not available";
CM_ SG_ 2633943038 TransSplitterIndirectActuator "Identifies the status of the splitter indirect actuator in the auxiliary unit.

00 - Off
01 - On
10 - Error
11 - Not available";
CM_ SG_ 2633943038 TransSplitterDirectActuator "Identifies the status of the splitter direct actuator in the auxiliary unit.

00 - Off
01 - On
10 - Error
11 - Not available";
CM_ SG_ 2633943038 TransRangeLowActuator "Identifies the status of the range low actuator in the auxiliary unit.

00 - Off
01 - On
10 - Error
11 - Not available";
CM_ SG_ 2633943038 TransRangeHighActuator "Identifies the status of the range high actuator in the auxiliary unit.

00 -Off
01 -On
10 - Error
11 - Not available";
CM_ SG_ 2633943038 TransShiftFingerGearActuator2 "Identifies the status of the actuator that moves the shift finger identified as gear actuator #2.

00 - Off
01 - On
10 - Error
11 - Not available";
CM_ SG_ 2633943038 TransShiftFingerRailActuator2 "Identifies the status of the actuator that moves the shift finger identified as rail actuator #2.

00 - Off
01 - On
10 - Error
11 - Not available";
CM_ SG_ 2633943038 TransShiftFingerGearActuator1 "Identifies the status of the actuator that moves the shift finger identified as gear actuator #1.

00 - Off
01 - On
10 - Error
11 - Not available";
CM_ SG_ 2633943038 TransShiftFingerRailActuator1 "Identifies the status of the actuator that moves the shift finger identified as rail actuator #1.

00 - Off
01 - On
10 - Error
11 - Not available";
CM_ SG_ 2633943038 TrnsShftFngerCenterRailIndicator "Identifies the status of the shift finger in the center rail position.

00 - Off
01 - On
10 - Error
11 - Not available";
CM_ SG_ 2633943038 TrnsShftFngerEngagementIndicator "Identifies the status of the shift finger in the engagement position.

00 - Off
01 - On
10 - Error
11 - Not available";
CM_ SG_ 2633943038 TransShiftFingerNeutralIndicator "Indicates the status of the shift finger in the neutral position.

00 - Off
01 - On
10 - Error
11 - Not available";
CM_ SG_ 2633943038 TransShiftFingerRailPos "The current position of the shift finger in the rail direction.";
CM_ SG_ 2633943038 TransShiftFingerGearPos "The current position of the shift finger in the gear direction.";
CM_ BO_ 2565867006 "Electronic Transmission Controller 2";
CM_ SG_ 2565867006 TransCurrentRange "Range currently being commanded by the transmission control system. Characters may include P, Rx, Rx-1...R2, R1, R, Nx, Nx-1...N2, N1, N, D, D1, D2..., Dx, L, L1, L2..., Lx-1, 1, 2, 3,... If only one displayed character is required, the second ...";
CM_ SG_ 2565867006 TransRequestedRange "Range selected by the operator.  Characters may include P, Rx, Rx-1...R2, R1, R, Nx, Nx-1...N2, N1, N, D, D1, D2..., Dx, L, L1, L2..., Lx-1, 1, 2, 3,...  If only one displayed character is required, the second character shall be used and the first ...";
CM_ SG_ 2565867006 TransCurrentGear "The gear currently engaged in the transmission or the last gear engaged while the transmission is in the process of shifting to the new or selected gear.  Transitions toward a destination gear will not be indicated.  Once the selected gear has been ...";
CM_ SG_ 2565867006 TransActualGearRatio "Actual ratio of input shaft speed to output shaft speed.";
CM_ SG_ 2565867006 TransSelectedGear "The gear that the transmission will attempt to achieve during the current shift if a shift is in progress, or the next shift if one is pending (i.e., waiting for torque reduction to initiate the shift).";
CM_ BO_ 2364539646 "Electronic Transmission Controller 1
Electronic Transmission Controller #1
Note:
Single input shaft transmissions should use SPN 161 (Transmission Input Shaft Speed).
Multiple input shaft transmissions should use SPN 5960 and 5961 (DCT Input ...";
CM_ SG_ 2364539646 SrcAddrssOfCntrllngDvcFrTrnsCtrl "The source address of the SAE J1939 device currently controlling the transmission. Its value may be the source address of the ECU transmitting the message (which means that no external SAE J1939 message is providing the active command) or the source ...";
CM_ SG_ 2364539646 TransInputShaftSpeed "Rotational velocity of the primary shaft transferring power into the transmission.  When a torque converter is present, it is the output of the torque converter.
Note:
Single input shaft transmissions should use SPN 161 (Transmission Input Shaft ...";
CM_ SG_ 2364539646 MomentaryEngMaxPowerEnable "Momentarily Requesting highest torque map from the engine control

00 not requesting maximum power available
01 momentarily requesting maximum power available
10 fault
11 not available";
CM_ SG_ 2364539646 ProgressiveShiftDisable "Command signal used to indicate that progressive shifting by the engine should be disallowed.

00 Progressive shift is not disabled
01 Progressive shift is disabled
10 Reserved
11 Take no action";
CM_ SG_ 2364539646 EngMomentaryOverspeedEnable "Command signal used to indicate that the engine speed may be boosted up to the maximum engine overspeed value to accommodate transmission downshifts.  The maximum time for overspeed is limited by the time defined in the engine configuration message ...";
CM_ SG_ 2364539646 PercentClutchSlip "Parameter which represents the ratio of input shaft speed to current engine speed (in percent).

Percent Clutch Slip = ((Engine rpm - Input shaft rpm)/(Engine rpm)) x 100";
CM_ SG_ 2364539646 TransOutputShaftSpeed "Calculated speed of the transmission output shaft.";
CM_ SG_ 2364539646 TrnsTrqCnvrtrLckpTrnstnInProcess "State signal indicating whether or not the transmission torque converter lock up clutch is transitioning between being applied and being released.  The broadcast value should be set to 01 as soon as an apply or release of the lockup clutch is ...";
CM_ SG_ 2364539646 TransShiftInProcess "Indicates that the transmission is in process of shifting from the current gear to the selected gear. This state is generally ACTIVE during the entire time that the transmission controls the vehicle during a shift. This includes any transmission ...";
CM_ SG_ 2364539646 TrnsTorqueConverterLockupEngaged "State signal which indicates whether the torque converter lockup is engaged.

00 Torque converter lockup disengaged
01 Torque converter lockup engaged
10 Error
11 Not available";
CM_ SG_ 2364539646 TransDrivelineEngaged "Driveline engaged indicates the transmission controlled portion of the driveline is engaged sufficiently to allow a transfer of torque through the transmission.  Driveline engaged is ACTIVE whenever the transmission is in gear and the clutch (if ...";
CM_ BO_ 2566810110 "Engine Temperature 3
This parameter group is used to transmit high resolution engine temperatures for control purposes.";
CM_ SG_ 2566810110 EngChargeAirCooler1OutletTemp "Temperature of combustion air after it exits from the Charge Air Cooler 1 but before any mixing of recirculated exhaust gas.";
CM_ SG_ 2566810110 EngIntkVlvActuationSystemOilTemp "The temperature of the oil in the hydraulic system that powers the intake valve actuation system.";
CM_ SG_ 2566810110 EngCoolantTemp "Temperature of liquid found in engine cooling system. The higher resolution is required for control purposes.";
CM_ SG_ 2566810110 EngIntakeManifold1AirTemp "Temperature of pre-combustion air found in intake manifold of engine air supply system. The higher resolution is required for control purposes.";
CM_ BO_ 2566825214 "Engine Temperature 2";
CM_ SG_ 2566825214 EngExhaustGasRecirculation1Temp "Temperature of Recirculated Exhaust Gas.  This should not be used for Exhaust Gas Recirculation Mixer Intake Temperature.  See SPN 5020.";
CM_ SG_ 2566825214 EngExhstGsRcirculation1DiffPress "Differential pressure across the Exhaust Gas Recirculation (EGR) system";
CM_ SG_ 2566825214 EngECUTemp "Temperature of the engine electronic control unit.";
CM_ SG_ 2566825214 EngOilTemp2 "Temperature of the engine lubricant.

Note:  If there is only one engine oil temperature measurement, SPN 175 should be used. 

See also SPNs 175 and 5925 for additional engine oil temperature measurements.";
CM_ BO_ 2566844158 "Engine Temperature 1";
CM_ SG_ 2566844158 EngIntercoolerThermostatOpening "The current position of the thermostat used to regulate the temperature of the engine charge air cooler.  A value of 0% represents the thermostat being completely closed and 100% represents the thermostat being completely open.";
CM_ SG_ 2566844158 EngIntercoolerTemp "Temperature of liquid found in the intercooler located after the turbocharger.";
CM_ SG_ 2566844158 EngTurboOilTemp "Temperature of the turbocharger lubricant.";
CM_ SG_ 2566844158 EngOilTemp1 "Temperature of the engine lubricant.
Note:  If there is only one engine oil temperature measurement, this SPN should be used.  This is the SPN that is typically displayed on an on-highway truck instrument cluster.
See also SPNs 1135 and 5925 for ...";
CM_ SG_ 2566844158 EngFuelTemp1 "Temperature of fuel (or gas) of the first fuel type. See SPN 3468 for a second temperature measurement of the first fuel type.";
CM_ SG_ 2566844158 EngCoolantTemp "Temperature of liquid found in engine cooling system.";
CM_ BO_ 2566785022 "Exhaust Temperature";
CM_ SG_ 2566785022 EngExhaustManifoldBank1Temp2 "Temperature of combustion byproducts measured by a second sensor in engine bank 1 (left bank) exhaust manifold. This should be used for the sensor toward the rear of the engine on the bank 1 manifold.";
CM_ SG_ 2566785022 EngExhaustManifoldBank2Temp2 "Temperature of combustion byproducts measured by a second sensor in engine bank 2 (right bank) exhaust manifold. This should be used for the sensor toward the rear of the engine on the bank 2 manifold.";
CM_ SG_ 2566785022 EngExhaustGasTempLeftManifold "Temperature of combustion byproducts measured in engine bank 1 (left bank) exhaust manifold.  Single manifold engines should use exhaust temperature (SPN 173).";
CM_ SG_ 2566785022 EngExhaustGasTempRightManifold "Temperature of combustion byproducts measured in engine bank 2 (right bank) exhaust manifold.  Single manifold engines should use exhaust temperature (SPN 173).";
CM_ BO_ 2565868542 "Electronic Steering Control
PGN which indicates the actual angle and the status of a steerable axle";
CM_ SG_ 2565868542 TypeOfSteerTrans "Type of Steering Transmission (Ref. ECE Regulation 79 paragraph 2.6)
0000             Purely mechanical steering transmission
0001             Purely hydraulic steering transmission
0010             Purely electric steering transmission
0011 ...";
CM_ SG_ 2565868542 TypeOfSteerForces "Type of Steering Forces (Ref. ECE Regulation 79 paragraph 2.5)
0000             Manual steering equipment
0001             Power assisted steering equipment
0010             Full power steering equipment
0011             Self tracking steering ...";
CM_ SG_ 2565868542 SteerType "Indicates the different types of steering systems (ref. ECE Regulation 79 paragraph 2.5)
0000             Main steering system
0001             Auxiliary steering equipment
0010-1110   Reserved for Assignment by SAE
1111             Not ...";
CM_ SG_ 2565868542 SteerableLiftAxleLoweringInhibit "A signal which indicates if lowering of lifted axle is allowed or inhibited.

00      Lowering allowed
01      Lowering inhibited
10      Reserved
11      Not available";
CM_ SG_ 2565868542 StatusOfSteerAxle "A signal which indicates different states of the steering axle
0000               Axle steering not active (adhesion steering)
0001               Axle steering active
0010               Axle centered
0011               Axle centered, because of ...";
CM_ SG_ 2565868542 AxleLocation "To identify to which of several similar devices (such as tires or fuel tanks) the information applies.
The low order 4 bits represent a position number, counting left to right when facing in the direction of normal vehicle travel (forward).
The ...";
CM_ SG_ 2565868542 ActualInnerWheelSteerAngle "Signal which indicates the actual inner wheel steering angle.  The steering angle is the angle of wheel turn relative to the vehicle x-axis (yaw angle of inner wheel). See Figure SPN2927_A for explanation of positive and negative angles.  This ...";
CM_ BO_ 2633941758 "Electronic Retarder Controller 2
This message will be transmitted by several types of retarding devices such as engine compression release brakes, exhaust system restriction brakes, and driveline retarders using hydraulic, electric, or mechanical ...";
CM_ SG_ 2633941758 CrsCtrlRetarderActiveSpeedOffset "The additional speed above the operator selected cruise control set speed at which the retarder will activate when cruise control is active.";
CM_ SG_ 2633941758 TransOutputRetarder "Identifies the status of the transmission output retarder.

00 - Off
01 - On
10 - Error
11 - Not available";
CM_ BO_ 2565865726 "Electronic Retarder Controller 1
NOTE- This message will be transmitted by several types of retarding devices such as engine compression release brakes, exhaust system restriction brakes, and driveline retarders using hydraulic, electric, or ...";
CM_ SG_ 2565865726 ActlMxAvlblRetarderPercentTorque "This is the maximum amount of torque that the retarder can immediately deliver.   It is the same as the maximum torque shown in the Retarder’s Configuration message, but allows for a much faster rate of change than could be communicated by reissuing ...";
CM_ SG_ 2565865726 RetarderSelectionNonengine "The “Retarder Selection, non-engine” is the position of the driver’s selector for retarders that are not part of the engine system, expressed as percent and determined by the ratio of current position to the maximum possible position. The physical ...";
CM_ SG_ 2565865726 DrvrsDemandRetarderPercentTorque "The Drivers demand retarder - percent torque is the maximum torque selected by the driver when one or more modes  are selected by the driver, such as hand lever, switch, constant torque, constant velocity, etc.";
CM_ SG_ 2565865726 SrcAddrssOfCntrllngDvcFrRtrdrCtr "The source address of the SAE J1939 device currently controlling the retarder.  It is used to expand the torque mode parameter (see SPN 899) in cases where control is in response to an ECU that is not listed in Table SPN899_A.  Its value may be the ...";
CM_ SG_ 2565865726 RetarderRoadSpeedExceededStatus "Retarder Road Speed Exceeded Status:

00   Road speed is below threshold 
01   Road speed is above threshold and retarder is allowed to be activated
10   Reserved
11   Don't care/Take no action";
CM_ SG_ 2565865726 RetarderRoadSpeedLimitSwitch "Retarder road speed limit switch states:
00   Road speed limiting by retarder is disabled
01   Road speed limiting by retarder is enabled.  The road speed that the retarder will limit will be determined when the switch transitions from 00 to 01
 ...";
CM_ SG_ 2565865726 RetarderRequestingBrakeLight "Indicates that whether the retarder is requesting that the brake lights are illuminated.
00 - Retarder is not requesting that the brake lights are illuminated
01 - Retarder is requesting that the brake lights are illuminated
10 - Reserved
11 - ...";
CM_ SG_ 2565865726 EngCoolantLoadIncrease "Status of an event, external to the engine, that may increase the nominal temperature of the engine coolant liquid.

00 - No coolant load increase
01 - Coolant load increase possible
10 - Error
11 - Not available";
CM_ SG_ 2565865726 IntendedRetarderPercentTorque "Braking torque of retarder that the retarder is currently trying to achieve.  This value takes into account all static limitations, but not the limitations due to the dynamic behavior of the retarder.  This value, if unchanged over a certain time, ...";
CM_ SG_ 2565865726 ActualRetarderPercentTorque "Actual braking torque of the retarder as a percent of retarder configuration reference torque SPN 556.

Note:  Refer to section 5.2.1 in SAE J1939-71.";
CM_ SG_ 2565865726 RetarderEnableShiftAssistSwitch "Switch signal which indicates whether the operator wishes the retarder to be enabled for transmission shift assist.  The retarder does not check this switch, nor does the enabling of this switch engage the retarder.  When this switch is “enabled,” ...";
CM_ SG_ 2565865726 RetarderEnableBrakeAssistSwitch "Switch signal which indicates whether the operator wishes the retarder to be enabled for vehicle braking assist. The retarder does not check this switch, nor does the enabling of this switch engage the retarder. When this switch is “enabled,” the ...";
CM_ SG_ 2565865726 RetarderTorqueMode "State signal which indicates which retarder torque mode is currently generating, limiting, or controlling the torque.  Note that the modes are not in prioritized order. Not all modes may be relevant for a given device.  Some devices may not ...";
CM_ BO_ 2633932798 "Exhaust Port Temperature 5";
CM_ SG_ 2633932798 EngExhaustGasPort20Temp "Temperature at the cylinder exhaust port of the engine.";
CM_ SG_ 2633932798 EngExhaustGasPort19Temp "Temperature at the cylinder exhaust port of the engine.";
CM_ SG_ 2633932798 EngExhaustGasPort18Temp "Temperature at the cylinder exhaust port of the engine.";
CM_ SG_ 2633932798 EngExhaustGasPort17Temp "Temperature at the cylinder exhaust port of the engine.";
CM_ BO_ 2566824190 "Exhaust Port Temperature 4";
CM_ SG_ 2566824190 EngExhaustGasPort16Temp "Temperature at the cylinder exhaust port of the engine.";
CM_ SG_ 2566824190 EngExhaustGasPort15Temp "Temperature at the cylinder exhaust port of the engine.";
CM_ SG_ 2566824190 EngExhaustGasPort14Temp "Temperature at the cylinder exhaust port of the engine.";
CM_ SG_ 2566824190 EngExhaustGasPort13Temp "Temperature at the cylinder exhaust port of the engine.";
CM_ BO_ 2633933310 "Exhaust Port Temperature 3";
CM_ SG_ 2633933310 EngExhaustGasPort12Temp "Temperature at the cylinder exhaust port of the engine.";
CM_ SG_ 2633933310 EngExhaustGasPort11Temp "Temperature at the cylinder exhaust port of the engine.";
CM_ SG_ 2633933310 EngExhaustGasPort10Temp "Temperature at the cylinder exhaust port of the engine.";
CM_ SG_ 2633933310 EngExhaustGasPort9Temp "Temperature at the cylinder exhaust port of the engine.";
CM_ BO_ 2633933566 "Exhaust Port Temperature 2";
CM_ SG_ 2633933566 EngExhaustGasPort8Temp "Temperature at the cylinder exhaust port of the engine.";
CM_ SG_ 2633933566 EngExhaustGasPort7Temp "Temperature at the cylinder exhaust port of the engine.";
CM_ SG_ 2633933566 EngExhaustGasPort6Temp "Temperature at the cylinder exhaust port of the engine.";
CM_ SG_ 2633933566 EngExhaustGasPort5Temp "Temperature at the cylinder exhaust port of the engine.";
CM_ BO_ 2633933822 "Exhaust Port Temperature 1";
CM_ SG_ 2633933822 EngExhaustGasPort4Temp "Temperature at the cylinder exhaust port of the engine.";
CM_ SG_ 2633933822 EngExhaustGasPort3Temp "Temperature at the cylinder exhaust port of the engine.";
CM_ SG_ 2633933822 EngExhaustGasPort2Temp "Temperature at the cylinder exhaust port of the engine.";
CM_ SG_ 2633933822 EngExhaustGasPort1Temp "Temperature at the cylinder exhaust port of the engine.";
CM_ BO_ 2566776062 "Equipment Performance Data
Parameters related to the performance characteristics of equipment";
CM_ SG_ 2566776062 PayloadCapacityPercentage "The current equipment payload plus the weight of any after-factory modifications reported as a percentage of the equipment's maximum payload capacity. The equipment's maximum payload capacity is the maximum capacity of the equipment before the added ...";
CM_ SG_ 2566776062 PayloadCarryBackWeight "The payload weight left on the machine after the last payload dump event.";
CM_ SG_ 2566776062 PayloadWeightConfidence "The level of confidence of the real time payload weight measurement (SPN 6851). Higher confidence values indicate greater probability the real time payload weight is the actual weight and providing feedback on the potential for improving system ...";
CM_ SG_ 2566776062 PayloadWeight "The current payload weight carried by the machine.";
CM_ SG_ 2566776062 PayloadPercentage "The current payload of the equipment, reported as a percentage of the equipment's rated payload limit.";
CM_ BO_ 2566771454 "ECU Performance
Message used to transfer ECU performance parameters.";
CM_ SG_ 2566771454 DataMemoryUsage "The used storage capacity of the data buffer memory internal to an ECU, such as a data logger.";
CM_ SG_ 2566771454 KeepAliveBatteryConsumption "The capacity consumed from the direct battery connection since the key was last turned off.  This value is maintained and does not accumulate while the key switch is on.  The value is reset to 0 when the key switch is turned to the off position.";
CM_ BO_ 2566775806 "Equipment Operation and Control
Parameters related to the operation and controls for equipment";
CM_ SG_ 2566775806 TravelVelocityCtrlPos "The position of the travel velocity control component reported as a percentage of the control's full displacement in each direction respectively.  Positive position values indicate forward travel direction;  negative position values indicate ...";
CM_ BO_ 2633935358 "Exhaust Oxygen 1";
CM_ SG_ 2633935358 EngExhstGsOxygnSnsrClsdLpOprtion "Indicates whether the engine is using the exhaust oxygen sensor to control the air/fuel ratio.
00 Engine not using the exhaust oxygen sensor (open loop)
01 Engine using the exhaust oxygen sensor for a closed loop operation
10 Reserved
11 Don't ...";
CM_ SG_ 2633935358 EngExhstGsOxygnSnsrFlngCrrection "The amount of fueling change required by the system based on the measured exhaust oxygen value compared to the maximum fueling change permitted by the system, expressed as percentages.";
CM_ SG_ 2633935358 EngActualExhaustOxygen "The actual amount of oxygen in the exhaust represented as a percentage by volume with respect to the total volume of exhaust gases leaving the engine.";
CM_ SG_ 2633935358 EngDesiredExhaustOxygen "The desired amount of oxygen in the exhaust represented as a percentage by volume with respect to the total volume of exhaust gases leaving the engine.";
CM_ SG_ 2633935358 EngDesiredRatedExhaustOxygen "The desired amount of oxygen in the exhaust at rated conditions represented as a percentage by volume with respect to the total volume of exhaust gases leaving the engine.";
CM_ BO_ 2365447166 "Extended Joystick Message 3
Used to transfer information about the measured status of three additional axes of a joystick and switches of the joystick grip or handle.  The joystick axial motion information is available in the Basic Joystick ...";
CM_ SG_ 2365447166 Joystick3Button13PressedStatus "Reports when the joystick button has been pressed.

00 Button not pressed
01 Button pressed
10 Error Indicator
11 Not Available";
CM_ SG_ 2365447166 Joystick3Button14PressedStatus "Reports when the joystick button has been pressed.

00 Button not pressed
01 Button pressed
10 Error Indicator
11 Not Available";
CM_ SG_ 2365447166 Joystick3Button15PressedStatus "Reports when the joystick button has been pressed.

00 Button not pressed
01 Button pressed
10 Error Indicator
11 Not Available";
CM_ SG_ 2365447166 Joystick3Button16PressedStatus "Reports when the joystick button has been pressed.

00 Button not pressed
01 Button pressed
10 Error Indicator
11 Not Available";
CM_ SG_ 2365447166 Jystick3GripXAxisDetentPosStatus "Reports when the current joystick grip position is in the detent position for that axis of travel.

00 Not in the Detent Position
01 In the Detent Position
10 Error Indicator
11 Not Available";
CM_ SG_ 2365447166 Jystick3GripYAxisDetentPosStatus "Reports when the current joystick grip position is in the detent position for that axis of travel.

00 Not in the Detent Position
01 In the Detent Position
10 Error Indicator
11 Not Available";
CM_ SG_ 2365447166 Jystick3ThetaAxisDetentPosStatus "Reports when the current joystick position is in the detent position for that axis of travel.

00 Not in the Detent Position
01 In the Detent Position
10 Error Indicator
11 Not Available";
CM_ SG_ 2365447166 Joystick3ThetaAxisPos "The position of the joystick in the relative motion of travel from the neutral position.  Position value of 0 is Neutral and position value 1000 (100%) is the end of linear zone.  Value of 1022 indicates an error has occurred.";
CM_ SG_ 2365447166 Jystck3ThtAxsClckwsPstvPosStatus "Reports when the current joystick position is on the positive travel side (forward, right, clockwise, up) relative to the neutral position for that axis of travel.
00 Not on Positive side of Neutral
01 On positive side of Neutral
10 Error ...";
CM_ SG_ 2365447166 Jystck3ThetaAxisNeutralPosStatus "Reports when the current joystick position is in the neutral position for that axis of travel.  The neutral position measurement must be determined from some mechanism other than the axis position measurement device.
00 Not in Neutral Position
01 ...";
CM_ SG_ 2365447166 Joystick3GripYAxisPos "The position of the joystick grip in the relative motion of travel from the neutral position.  Position value of 0 is Neutral and position value 1000 (100%) is the end of linear zone.  Value of 1022 indicates an error has occurred.";
CM_ SG_ 2365447166 Jystck3GrpYAxsLvrFrwrdPstvPsStts "Reports when the current joystick grip position is on the positive travel side (forward, right, clockwise, up) relative to the neutral position for that axis of travel.
00 Not on Positive side of Neutral
01 On positive side of Neutral
10 Error ...";
CM_ SG_ 2365447166 Jystck3GrpYAxsLvrBckNgtvPsStatus "Reports when the current joystick grip position is on the negative travel side (back, left, counterclockwise, down) relative to the neutral position for that axis of travel.
00 Not on negative side of Neutral
01 On negative side of Neutral
10 ...";
CM_ SG_ 2365447166 Jystck3GripYAxisNeutralPosStatus "Reports when the current joystick grip position is in the neutral position for that axis of travel.  The neutral position measurement must be determined from some mechanism other than the axis position measurement device.
00 Not in Neutral Position
 ...";
CM_ SG_ 2365447166 Joystick3GripXAxisPos "The position of the joystick grip in the relative motion of travel from the neutral position.  Position value of 0 is Neutral and position value 1000 (100%) is the end of linear zone.  Value of 1022 indicates an error has occurred.";
CM_ SG_ 2365447166 Jystck3GrpXAxsLvrRghtPstvPsSttus "Reports when the current joystick grip position is on the positive travel side (forward, right, clockwise, up) relative to the neutral position for that axis of travel.
00 Not on Positive side of Neutral
01 On positive side of Neutral
10 Error ...";
CM_ SG_ 2365447166 Jystck3GrpXAxsLvrLftNgtvPsStatus "Reports when the current joystick grip position is on the negative travel side (back, left, counterclockwise, down) relative to the neutral position for that axis of travel.
00 Not on negative side of Neutral
01 On negative side of Neutral
10 ...";
CM_ SG_ 2365447166 Jystck3GripXAxisNeutralPosStatus "Reports when the current joystick grip position is in the neutral position for that axis of travel.  The neutral position measurement must be determined from some mechanism other than the axis position measurement device.
00 Not on negative side of ...";
CM_ SG_ 2365447166 Jystck3ThtAxsCntrClckwsNgtvPsStt "Reports when the current joystick position is on the negative travel side (back, left, counterclockwise, down) relative to the neutral position for that axis of travel.
00 Not on negative side of Neutral
01 On negative side of Neutral
10 Error ...";
BA_DEF_ SG_  "SigType" ENUM  "Default","Range","RangeSigned","ASCII","Discrete","Control","ReferencePGN","DTC","StringDelimiter","StringLength","StringLengthControl","MessageCounter","MessageChecksum";
BA_DEF_ SG_  "GenSigStartValue" INT 0 2147483647;
BA_DEF_ SG_  "GenSigSendType" ENUM  "Cyclic","OnWrite","OnWriteWithRepetition","OnChange","OnChangeWithRepetition","IfActive","IfActiveWithRepetition","NoSigSendType";
BA_DEF_ SG_  "GenSigILSupport" ENUM  "No","Yes";
BA_DEF_ SG_  "GenSigEVName" STRING ;
BA_DEF_ SG_  "SPN" INT 0 524287;
BA_DEF_ BO_  "TpJ1939VarDlc" ENUM  "No","Yes";
BA_DEF_ BO_  "GenMsgStartDelayTime" INT 0 100000;
BA_DEF_ BO_  "GenMsgILSupport" ENUM  "No","Yes";
BA_DEF_ BO_  "GenMsgDelayTime" INT 0 1000;
BA_DEF_ BO_  "GenMsgRequestable" INT 0 1;
BA_DEF_ BO_  "GenMsgSendType" ENUM  "cyclic","NotUsed","NotUsed","NotUsed","NotUsed","NotUsed","NotUsed","IfActive","noMsgSendType";
BA_DEF_ BO_  "VFrameFormat" ENUM  "StandardCAN","ExtendedCAN","reserved","J1939PG";
BA_DEF_ BO_  "GenMsgCycleTime" INT 0 3600000;
BA_DEF_ SG_  "SystemSignalLongSymbol" STRING ;
BA_DEF_DEF_  "SigType" "Default";
BA_DEF_DEF_  "GenSigStartValue" 0;
BA_DEF_DEF_  "GenSigSendType" "NoSigSendType";
BA_DEF_DEF_  "GenSigILSupport" "Yes";
BA_DEF_DEF_  "GenSigEVName" "Env@Nodename_@Signame";
BA_DEF_DEF_  "SPN" 0;
BA_DEF_DEF_  "TpJ1939VarDlc" "No";
BA_DEF_DEF_  "GenMsgStartDelayTime" 0;
BA_DEF_DEF_  "GenMsgILSupport" "Yes";
BA_DEF_DEF_  "GenMsgDelayTime" 0;
BA_DEF_DEF_  "GenMsgRequestable" 1;
BA_DEF_DEF_  "GenMsgSendType" "noMsgSendType";
BA_DEF_DEF_  "VFrameFormat" "J1939PG";
BA_DEF_DEF_  "GenMsgCycleTime" 0;
BA_DEF_DEF_  "SystemSignalLongSymbol" "";
BA_ "GenMsgCycleTime" BO_ 2566840830 5000;
BA_ "GenMsgSendType" BO_ 2566840830 0;
BA_ "GenMsgDelayTime" BO_ 2566840830 500;
BA_ "GenMsgCycleTime" BO_ 2566844670 100;
BA_ "GenMsgSendType" BO_ 2566844670 0;
BA_ "GenMsgCycleTime" BO_ 2566770174 200;
BA_ "GenMsgSendType" BO_ 2566770174 0;
BA_ "GenMsgCycleTime" BO_ 2566769662 500;
BA_ "GenMsgSendType" BO_ 2566769662 0;
BA_ "GenMsgCycleTime" BO_ 2566768638 5000;
BA_ "GenMsgSendType" BO_ 2566768638 0;
BA_ "GenMsgCycleTime" BO_ 2365443326 1000;
BA_ "GenMsgSendType" BO_ 2365443326 0;
BA_ "GenMsgDelayTime" BO_ 2365443326 100;
BA_ "GenMsgCycleTime" BO_ 2566776318 1000;
BA_ "GenMsgSendType" BO_ 2566776318 0;
BA_ "GenMsgCycleTime" BO_ 2566802686 500;
BA_ "GenMsgSendType" BO_ 2566802686 0;
BA_ "GenMsgDelayTime" BO_ 2566802686 100;
BA_ "GenMsgCycleTime" BO_ 2566774014 1000;
BA_ "GenMsgSendType" BO_ 2566774014 0;
BA_ "GenMsgCycleTime" BO_ 2566823166 1000;
BA_ "GenMsgSendType" BO_ 2566823166 0;
BA_ "GenMsgCycleTime" BO_ 2566823422 1000;
BA_ "GenMsgSendType" BO_ 2566823422 0;
BA_ "GenMsgCycleTime" BO_ 2566823678 1000;
BA_ "GenMsgSendType" BO_ 2566823678 0;
BA_ "GenMsgCycleTime" BO_ 2432595710 100;
BA_ "GenMsgSendType" BO_ 2432595710 0;
BA_ "GenMsgCycleTime" BO_ 2365486590 50;
BA_ "GenMsgSendType" BO_ 2365486590 0;
BA_ "GenMsgCycleTime" BO_ 2365485566 50;
BA_ "GenMsgSendType" BO_ 2365485566 0;
BA_ "GenMsgCycleTime" BO_ 2365486334 50;
BA_ "GenMsgSendType" BO_ 2365486334 0;
BA_ "GenMsgCycleTime" BO_ 2364542462 100;
BA_ "GenMsgSendType" BO_ 2364542462 0;
BA_ "GenMsgCycleTime" BO_ 2365486078 50;
BA_ "GenMsgSendType" BO_ 2365486078 0;
BA_ "GenMsgCycleTime" BO_ 2566845182 100;
BA_ "GenMsgSendType" BO_ 2566845182 0;
BA_ "GenMsgCycleTime" BO_ 2633883646 5000;
BA_ "GenMsgSendType" BO_ 2633883646 0;
BA_ "GenMsgCycleTime" BO_ 2633880062 10000;
BA_ "GenMsgSendType" BO_ 2633880062 0;
BA_ "GenMsgCycleTime" BO_ 2566806526 100;
BA_ "GenMsgSendType" BO_ 2566806526 0;
BA_ "GenMsgCycleTime" BO_ 2431649790 50;
BA_ "GenMsgCycleTime" BO_ 2633929214 1000;
BA_ "GenMsgSendType" BO_ 2633929214 0;
BA_ "GenMsgCycleTime" BO_ 2566831614 1000;
BA_ "GenMsgSendType" BO_ 2566831614 0;
BA_ "GenMsgCycleTime" BO_ 2364542206 20;
BA_ "GenMsgSendType" BO_ 2364542206 0;
BA_ "GenMsgCycleTime" BO_ 2566802174 100;
BA_ "GenMsgSendType" BO_ 2566802174 0;
BA_ "GenMsgCycleTime" BO_ 2565867006 100;
BA_ "GenMsgSendType" BO_ 2565867006 0;
BA_ "GenMsgCycleTime" BO_ 2364539646 10;
BA_ "GenMsgSendType" BO_ 2364539646 0;
BA_ "GenMsgCycleTime" BO_ 2566810110 1000;
BA_ "GenMsgSendType" BO_ 2566810110 0;
BA_ "GenMsgCycleTime" BO_ 2566825214 1000;
BA_ "GenMsgSendType" BO_ 2566825214 0;
BA_ "GenMsgCycleTime" BO_ 2566844158 1000;
BA_ "GenMsgSendType" BO_ 2566844158 0;
BA_ "GenMsgCycleTime" BO_ 2566785022 5000;
BA_ "GenMsgSendType" BO_ 2566785022 0;
BA_ "GenMsgCycleTime" BO_ 2565868542 20;
BA_ "GenMsgSendType" BO_ 2565868542 0;
BA_ "GenMsgCycleTime" BO_ 2633941758 1000;
BA_ "GenMsgSendType" BO_ 2633941758 0;
BA_ "GenMsgDelayTime" BO_ 2633941758 100;
BA_ "GenMsgCycleTime" BO_ 2565865726 100;
BA_ "GenMsgSendType" BO_ 2565865726 0;
BA_ "GenMsgCycleTime" BO_ 2633932798 1000;
BA_ "GenMsgSendType" BO_ 2633932798 0;
BA_ "GenMsgCycleTime" BO_ 2566824190 1000;
BA_ "GenMsgSendType" BO_ 2566824190 0;
BA_ "GenMsgCycleTime" BO_ 2633933310 1000;
BA_ "GenMsgSendType" BO_ 2633933310 0;
BA_ "GenMsgCycleTime" BO_ 2633933566 1000;
BA_ "GenMsgSendType" BO_ 2633933566 0;
BA_ "GenMsgCycleTime" BO_ 2633933822 1000;
BA_ "GenMsgSendType" BO_ 2633933822 0;
BA_ "GenMsgCycleTime" BO_ 2566776062 500;
BA_ "GenMsgSendType" BO_ 2566776062 0;
BA_ "GenMsgCycleTime" BO_ 2566775806 250;
BA_ "GenMsgSendType" BO_ 2566775806 0;
BA_ "GenMsgCycleTime" BO_ 2365447166 100;
BA_ "GenMsgSendType" BO_ 2365447166 0;
BA_ "GenMsgDelayTime" BO_ 2365447166 20;
BA_ "SPN" SG_ 2631859966 SteerStraightAheadPosReset 3600;
BA_ "SigType" SG_ 2631859966 SteerStraightAheadPosReset 5;
BA_ "SPN" SG_ 2631859966 EngBuildHoursReset 1211;
BA_ "SigType" SG_ 2631859966 EngBuildHoursReset 5;
BA_ "SPN" SG_ 2631859966 EngIgntCtrlMaintenanceHoursReset 6219;
BA_ "SigType" SG_ 2631859966 EngIgntCtrlMaintenanceHoursReset 4;
BA_ "SPN" SG_ 2631859966 EngSprkPlgScndVltgeTrackingReset 6218;
BA_ "SigType" SG_ 2631859966 EngSprkPlgScndVltgeTrackingReset 5;
BA_ "SPN" SG_ 2631859966 ServiceComponentIdentification 1584;
BA_ "SigType" SG_ 2631859966 ServiceComponentIdentification 1;
BA_ "SPN" SG_ 2631859966 TripGroup2Proprietary 989;
BA_ "SigType" SG_ 2631859966 TripGroup2Proprietary 5;
BA_ "SPN" SG_ 2631859966 TireSensorInformation 6986;
BA_ "SigType" SG_ 2631859966 TireSensorInformation 4;
BA_ "SPN" SG_ 2631859966 TireConfigInformation 6985;
BA_ "SigType" SG_ 2631859966 TireConfigInformation 4;
BA_ "SPN" SG_ 2631859966 BinLiftCountReset 6898;
BA_ "SigType" SG_ 2631859966 BinLiftCountReset 4;
BA_ "SPN" SG_ 2631859966 TripGroup1 988;
BA_ "SigType" SG_ 2631859966 TripGroup1 5;
BA_ "SPN" SG_ 2566840830 PercentTorqueAtPeakTorquePoint5 555;
BA_ "SigType" SG_ 2566840830 PercentTorqueAtPeakTorquePoint5 1;
BA_ "SPN" SG_ 2566840830 ReferenceRetarderTorque 556;
BA_ "SigType" SG_ 2566840830 ReferenceRetarderTorque 1;
BA_ "SPN" SG_ 2566840830 RetarderSpeedAtPeakTorquePoint5 547;
BA_ "SigType" SG_ 2566840830 RetarderSpeedAtPeakTorquePoint5 1;
BA_ "SPN" SG_ 2566840830 PercentTorqueAtPoint4 554;
BA_ "SigType" SG_ 2566840830 PercentTorqueAtPoint4 1;
BA_ "SPN" SG_ 2566840830 RetarderSpeedAtPoint4 550;
BA_ "SigType" SG_ 2566840830 RetarderSpeedAtPoint4 1;
BA_ "SPN" SG_ 2566840830 PercentTorqueAtPoint3 553;
BA_ "SigType" SG_ 2566840830 PercentTorqueAtPoint3 1;
BA_ "SPN" SG_ 2566840830 RetarderSpeedAtPoint3 549;
BA_ "SigType" SG_ 2566840830 RetarderSpeedAtPoint3 1;
BA_ "SPN" SG_ 2566840830 PercentTorqueAtMaxSpeedPoint2 552;
BA_ "SigType" SG_ 2566840830 PercentTorqueAtMaxSpeedPoint2 1;
BA_ "SPN" SG_ 2566840830 MaxRetarderSpeedPoint2 548;
BA_ "SigType" SG_ 2566840830 MaxRetarderSpeedPoint2 1;
BA_ "SPN" SG_ 2566840830 PercentTorqueAtIdlePoint1 551;
BA_ "SigType" SG_ 2566840830 PercentTorqueAtIdlePoint1 1;
BA_ "SPN" SG_ 2566840830 RetarderSpeedAtIdlePoint1 546;
BA_ "SigType" SG_ 2566840830 RetarderSpeedAtIdlePoint1 1;
BA_ "SPN" SG_ 2566840830 RetarderCtrlMethod 557;
BA_ "SigType" SG_ 2566840830 RetarderCtrlMethod 1;
BA_ "SPN" SG_ 2566840830 RetarderLocation 902;
BA_ "SPN" SG_ 2566840830 RetarderType 901;
BA_ "SPN" SG_ 2633930238 EngOperationTimeSinceRebuild 1193;
BA_ "SigType" SG_ 2633930238 EngOperationTimeSinceRebuild 1;
BA_ "SPN" SG_ 2566844670 PowerTakeoffSetSpeed 187;
BA_ "SigType" SG_ 2566844670 PowerTakeoffSetSpeed 1;
BA_ "SPN" SG_ 2566844670 PowerTakeoffSpeed 186;
BA_ "SigType" SG_ 2566844670 PowerTakeoffSpeed 1;
BA_ "SPN" SG_ 2566844670 PowerTakeoffOilTemp 90;
BA_ "SigType" SG_ 2566844670 PowerTakeoffOilTemp 1;
BA_ "SPN" SG_ 2566844670 OprtrEngPTOGvrnrMmrySelectSwitch 2897;
BA_ "SigType" SG_ 2566844670 OprtrEngPTOGvrnrMmrySelectSwitch 4;
BA_ "SPN" SG_ 2566844670 EngRmtPTOGvrnrVrblSpedCtrlSwitch 978;
BA_ "SigType" SG_ 2566844670 EngRmtPTOGvrnrVrblSpedCtrlSwitch 4;
BA_ "SPN" SG_ 2566844670 EngRmtPTOGvrnrPrprgrmmdSpdCtrlSw 979;
BA_ "SigType" SG_ 2566844670 EngRmtPTOGvrnrPrprgrmmdSpdCtrlSw 4;
BA_ "SPN" SG_ 2566844670 EngPTOGvrnrCast_DecelerateSwitch 983;
BA_ "SigType" SG_ 2566844670 EngPTOGvrnrCast_DecelerateSwitch 4;
BA_ "SPN" SG_ 2566844670 EngPTOGovernorSetSwitch 984;
BA_ "SigType" SG_ 2566844670 EngPTOGovernorSetSwitch 4;
BA_ "SPN" SG_ 2566844670 EngPTOGovernorResumeSwitch 982;
BA_ "SigType" SG_ 2566844670 EngPTOGovernorResumeSwitch 4;
BA_ "SPN" SG_ 2566844670 EngPTOGovernorEnableSwitch 980;
BA_ "SigType" SG_ 2566844670 EngPTOGovernorEnableSwitch 4;
BA_ "SPN" SG_ 2566844670 EngPTOGovernorAccelerateSwitch 981;
BA_ "SigType" SG_ 2566844670 EngPTOGovernorAccelerateSwitch 4;
BA_ "SPN" SG_ 2566844670 RmtPTOGvrnrPrprgrmmdSpdCtrlSwtch 3447;
BA_ "SigType" SG_ 2566844670 RmtPTOGvrnrPrprgrmmdSpdCtrlSwtch 4;
BA_ "SPN" SG_ 2566844670 AuxInputIgnoreSwitch 3448;
BA_ "SigType" SG_ 2566844670 AuxInputIgnoreSwitch 4;
BA_ "SPN" SG_ 2566770174 RearWasherFunction 2868;
BA_ "SPN" SG_ 2566770174 FrontOperatorWasherSwitch 2866;
BA_ "SPN" SG_ 2566770174 FrontNonoperatorWasherSwitch 2867;
BA_ "SPN" SG_ 2566770174 RearWiperDelayCtrl 2871;
BA_ "SigType" SG_ 2566770174 RearWiperDelayCtrl 1;
BA_ "SPN" SG_ 2566770174 FrontNonoperatorWiperDelayCtrl 2870;
BA_ "SigType" SG_ 2566770174 FrontNonoperatorWiperDelayCtrl 1;
BA_ "SPN" SG_ 2566770174 FrontOperatorWiperDelayCtrl 2869;
BA_ "SigType" SG_ 2566770174 FrontOperatorWiperDelayCtrl 1;
BA_ "SPN" SG_ 2566770174 RearWiperSwitch 2865;
BA_ "SPN" SG_ 2566770174 FrontOperatorWiperSwitch 2863;
BA_ "SPN" SG_ 2566770174 FrontNonoperatorWiperSwitch 2864;
BA_ "SPN" SG_ 2566769662 EngTorqueCurveSelectionCmd 6796;
BA_ "SPN" SG_ 2566769662 EngAltDroopAuxInputSelect 2885;
BA_ "SPN" SG_ 2566769662 EngAltDroopRemoteAccelSelect 2886;
BA_ "SPN" SG_ 2566769662 EngAltDroopAccel2Select 2879;
BA_ "SPN" SG_ 2566769662 EngAltDroopAccel1Select 2881;
BA_ "SPN" SG_ 2566769662 EngAltRatingSelect 2882;
BA_ "SigType" SG_ 2566769662 EngAltRatingSelect 1;
BA_ "SPN" SG_ 2566769662 EngAltLowIdleSwitch 2883;
BA_ "SigType" SG_ 2566769662 EngAltLowIdleSwitch 4;
BA_ "SPN" SG_ 2566769662 EngSynchronizationSwitch 1377;
BA_ "SigType" SG_ 2566769662 EngSynchronizationSwitch 4;
BA_ "SPN" SG_ 2566769662 EngAuxGovernorSwitch 2884;
BA_ "SigType" SG_ 2566769662 EngAuxGovernorSwitch 4;
BA_ "SPN" SG_ 2566768638 EngTorqueCurveSelection 1568;
BA_ "SPN" SG_ 2566768638 EngAltDroopAuxInputSelectState 2895;
BA_ "SPN" SG_ 2566768638 EngAltDropRemoteAccelSelectState 2894;
BA_ "SPN" SG_ 2566768638 EngAltDroopAccel2SelectState 2893;
BA_ "SPN" SG_ 2566768638 EngAltDroopAccel1SelectState 2889;
BA_ "SPN" SG_ 2566768638 EngAltRatingSelectState 2888;
BA_ "SPN" SG_ 2566768638 EngAltLowIdleSelectState 2891;
BA_ "SigType" SG_ 2566768638 EngAltLowIdleSelectState 5;
BA_ "SPN" SG_ 2566768638 EngMultiUnitSyncState 2890;
BA_ "SigType" SG_ 2566768638 EngMultiUnitSyncState 5;
BA_ "SPN" SG_ 2566768638 EngAuxGovernorState 2896;
BA_ "SigType" SG_ 2566768638 EngAuxGovernorState 5;
BA_ "SPN" SG_ 2365443326 OprtorsDesiredDelayedLampOffTime 2877;
BA_ "SigType" SG_ 2365443326 OprtorsDesiredDelayedLampOffTime 1;
BA_ "SPN" SG_ 2365443326 OperatorsDesiredBacklight 2878;
BA_ "SigType" SG_ 2365443326 OperatorsDesiredBacklight 1;
BA_ "SPN" SG_ 2365443326 HighLowBeamSwitch 2874;
BA_ "SigType" SG_ 2365443326 HighLowBeamSwitch 4;
BA_ "SPN" SG_ 2365443326 HazardLightSwitch 2875;
BA_ "SigType" SG_ 2365443326 HazardLightSwitch 4;
BA_ "SPN" SG_ 2365443326 TurnSignalSwitch 2876;
BA_ "SPN" SG_ 2365443326 MainLightSwitch 2872;
BA_ "SPN" SG_ 2365443326 WorkLightSwitch 2873;
BA_ "SPN" SG_ 2566776318 AppliedVehicleSpeedLimit 2595;
BA_ "SigType" SG_ 2566776318 AppliedVehicleSpeedLimit 1;
BA_ "SPN" SG_ 2566776318 MaxVehicleSpeedLimit7 2594;
BA_ "SigType" SG_ 2566776318 MaxVehicleSpeedLimit7 1;
BA_ "SPN" SG_ 2566776318 MaxVehicleSpeedLimit6 2593;
BA_ "SigType" SG_ 2566776318 MaxVehicleSpeedLimit6 1;
BA_ "SPN" SG_ 2566776318 MaxVehicleSpeedLimit5 2592;
BA_ "SigType" SG_ 2566776318 MaxVehicleSpeedLimit5 1;
BA_ "SPN" SG_ 2566776318 MaxVehicleSpeedLimit4 2591;
BA_ "SigType" SG_ 2566776318 MaxVehicleSpeedLimit4 1;
BA_ "SPN" SG_ 2566776318 MaxVehicleSpeedLimit3 2590;
BA_ "SigType" SG_ 2566776318 MaxVehicleSpeedLimit3 1;
BA_ "SPN" SG_ 2566776318 MaxVehicleSpeedLimit2 2589;
BA_ "SigType" SG_ 2566776318 MaxVehicleSpeedLimit2 1;
BA_ "SPN" SG_ 2566776318 MaxVehicleSpeedLimit1 2588;
BA_ "SigType" SG_ 2566776318 MaxVehicleSpeedLimit1 1;
BA_ "SPN" SG_ 2566802686 OprtrsBlackOutIntensitySelection 1844;
BA_ "SigType" SG_ 2566802686 OprtrsBlackOutIntensitySelection 1;
BA_ "SPN" SG_ 2566802686 BlackOutWorkLampSelect 1842;
BA_ "SigType" SG_ 2566802686 BlackOutWorkLampSelect 5;
BA_ "SPN" SG_ 2566802686 NightVisionIlluminatorSelect 1843;
BA_ "SigType" SG_ 2566802686 NightVisionIlluminatorSelect 5;
BA_ "SPN" SG_ 2566802686 BlackOutBrake_StopLampSelect 1841;
BA_ "SigType" SG_ 2566802686 BlackOutBrake_StopLampSelect 5;
BA_ "SPN" SG_ 2566802686 ConvoyDrivingLampSelect 1837;
BA_ "SigType" SG_ 2566802686 ConvoyDrivingLampSelect 5;
BA_ "SPN" SG_ 2566802686 ConvoyLampSelect 1838;
BA_ "SigType" SG_ 2566802686 ConvoyLampSelect 5;
BA_ "SPN" SG_ 2566802686 FrontBlackOutMarkerLampSelect 1839;
BA_ "SigType" SG_ 2566802686 FrontBlackOutMarkerLampSelect 5;
BA_ "SPN" SG_ 2566802686 RearBlackOutMarkerSelect 1840;
BA_ "SigType" SG_ 2566802686 RearBlackOutMarkerSelect 5;
BA_ "SPN" SG_ 2566774014 SlowVesselModeStatus 2617;
BA_ "SigType" SG_ 2566774014 SlowVesselModeStatus 5;
BA_ "SPN" SG_ 2566774014 TrollingModeStatus 2616;
BA_ "SigType" SG_ 2566774014 TrollingModeStatus 5;
BA_ "SPN" SG_ 2566774014 EngThrttlSynchrnzationModeStatus 2615;
BA_ "SPN" SG_ 2566823166 EngMainBearing12Temp 6830;
BA_ "SigType" SG_ 2566823166 EngMainBearing12Temp 1;
BA_ "SPN" SG_ 2566823166 EngMainBearing11Temp 1167;
BA_ "SigType" SG_ 2566823166 EngMainBearing11Temp 1;
BA_ "SPN" SG_ 2566823166 EngMainBearing10Temp 1166;
BA_ "SigType" SG_ 2566823166 EngMainBearing10Temp 1;
BA_ "SPN" SG_ 2566823166 EngMainBearing9Temp 1165;
BA_ "SigType" SG_ 2566823166 EngMainBearing9Temp 1;
BA_ "SPN" SG_ 2566823422 EngMainBearing8Temp 1164;
BA_ "SigType" SG_ 2566823422 EngMainBearing8Temp 1;
BA_ "SPN" SG_ 2566823422 EngMainBearing7Temp 1163;
BA_ "SigType" SG_ 2566823422 EngMainBearing7Temp 1;
BA_ "SPN" SG_ 2566823422 EngMainBearing6Temp 1162;
BA_ "SigType" SG_ 2566823422 EngMainBearing6Temp 1;
BA_ "SPN" SG_ 2566823422 EngMainBearing5Temp 1161;
BA_ "SigType" SG_ 2566823422 EngMainBearing5Temp 1;
BA_ "SPN" SG_ 2566823678 EngMainBearing4Temp 1160;
BA_ "SigType" SG_ 2566823678 EngMainBearing4Temp 1;
BA_ "SPN" SG_ 2566823678 EngMainBearing3Temp 1159;
BA_ "SigType" SG_ 2566823678 EngMainBearing3Temp 1;
BA_ "SPN" SG_ 2566823678 EngMainBearing2Temp 1158;
BA_ "SigType" SG_ 2566823678 EngMainBearing2Temp 1;
BA_ "SPN" SG_ 2566823678 EngMainBearing1Temp 1157;
BA_ "SigType" SG_ 2566823678 EngMainBearing1Temp 1;
BA_ "SPN" SG_ 2432595710 DisplayDeadbands 2577;
BA_ "SPN" SG_ 2432595710 LEDPatternCtrl 2578;
BA_ "SPN" SG_ 2432595710 LEDDisplayDeadbandCtrl 1806;
BA_ "SPN" SG_ 2432595710 LEDDisplayModeCtrl 1805;
BA_ "SPN" SG_ 2432595710 LEDDisplayData1 1573;
BA_ "SPN" SG_ 2365486590 AbsLaserStrikePos 2794;
BA_ "SigType" SG_ 2365486590 AbsLaserStrikePos 1;
BA_ "SPN" SG_ 2365486590 LaserStrikeDataLatency 2793;
BA_ "SigType" SG_ 2365486590 LaserStrikeDataLatency 1;
BA_ "SPN" SG_ 2365486590 LaserReceiverType 2576;
BA_ "SigType" SG_ 2365486590 LaserReceiverType 1;
BA_ "SPN" SG_ 2365486590 LaserStrikeVerticalDeviation 1574;
BA_ "SigType" SG_ 2365486590 LaserStrikeVerticalDeviation 1;
BA_ "SPN" SG_ 2365485566 LaserTracerInformation 1583;
BA_ "SPN" SG_ 2365485566 LEDDisplayData2 1582;
BA_ "SPN" SG_ 2365485566 LaserTracerHorizontalDeviation 1581;
BA_ "SigType" SG_ 2365485566 LaserTracerHorizontalDeviation 1;
BA_ "SPN" SG_ 2365485566 LaserTracerVerticalDistance 1580;
BA_ "SigType" SG_ 2365485566 LaserTracerVerticalDistance 1;
BA_ "SPN" SG_ 2365485566 LaserTracerTargetDeviation 1579;
BA_ "SigType" SG_ 2365485566 LaserTracerTargetDeviation 1;
BA_ "SPN" SG_ 2633939454 TripDriveFuelEconomy 1006;
BA_ "SigType" SG_ 2633939454 TripDriveFuelEconomy 1;
BA_ "SPN" SG_ 2633939454 TripCruiseFuelUsed 1005;
BA_ "SigType" SG_ 2633939454 TripCruiseFuelUsed 1;
BA_ "SPN" SG_ 2633939454 TripVehicleIdleFuelUsed 1004;
BA_ "SigType" SG_ 2633939454 TripVehicleIdleFuelUsed 1;
BA_ "SPN" SG_ 2633939454 TripPTOGovernorNonmovingFuelUsed 1003;
BA_ "SigType" SG_ 2633939454 TripPTOGovernorNonmovingFuelUsed 1;
BA_ "SPN" SG_ 2633939454 TripPTOGovernorMovingFuelUsed 1002;
BA_ "SigType" SG_ 2633939454 TripPTOGovernorMovingFuelUsed 1;
BA_ "SPN" SG_ 2633939454 TripDriveFuelUsed 1001;
BA_ "SigType" SG_ 2633939454 TripDriveFuelUsed 1;
BA_ "SPN" SG_ 2365486334 BldeHeightSetPointHighResolution 1759;
BA_ "SigType" SG_ 2365486334 BldeHeightSetPointHighResolution 1;
BA_ "SPN" SG_ 2365486334 ModifyLevelingSystemSetPoint 1575;
BA_ "SigType" SG_ 2365486334 ModifyLevelingSystemSetPoint 1;
BA_ "SPN" SG_ 2364542462 StElvtnSensor2ReferenceElevation 5406;
BA_ "SigType" SG_ 2364542462 StElvtnSensor2ReferenceElevation 5;
BA_ "SPN" SG_ 2364542462 StElvtnSensor1ReferenceElevation 5405;
BA_ "SigType" SG_ 2364542462 StElvtnSensor1ReferenceElevation 5;
BA_ "SPN" SG_ 2364542462 SdshftDsrdBldeOffsetOperatorCtrl 3339;
BA_ "SPN" SG_ 2364542462 SdshiftBladeCtrlModeOperatorCtrl 3338;
BA_ "SPN" SG_ 2364542462 RghtDsredBladeOffsetOperatorCtrl 3337;
BA_ "SPN" SG_ 2364542462 LftDsiredBladeOffsetOperatorCtrl 3336;
BA_ "SPN" SG_ 2364542462 RightBladeCtrlModeOperatorCtrl 3335;
BA_ "SPN" SG_ 2364542462 LeftBladeCtrlModeOperatorCtrl 3334;
BA_ "SPN" SG_ 2364542462 BladeAutoModeCmd 3158;
BA_ "SPN" SG_ 2364542462 DesiredGradeOffsetSwitch 3157;
BA_ "SPN" SG_ 2364542462 BladeCtrlModeSwitch 3156;
BA_ "SPN" SG_ 2365486078 MastPos 1576;
BA_ "SigType" SG_ 2365486078 MastPos 1;
BA_ "SPN" SG_ 2633937918 FlexibleFuelPercentage 5458;
BA_ "SigType" SG_ 2633937918 FlexibleFuelPercentage 1;
BA_ "SPN" SG_ 2633937918 TripAverageFuelRate 1029;
BA_ "SigType" SG_ 2633937918 TripAverageFuelRate 1;
BA_ "SPN" SG_ 2633937918 TotalEngPTOGovernorFuelUsed 1028;
BA_ "SigType" SG_ 2633937918 TotalEngPTOGovernorFuelUsed 1;
BA_ "SPN" SG_ 2566845182 EngThrottleValve2Pos 3673;
BA_ "SigType" SG_ 2566845182 EngThrottleValve2Pos 1;
BA_ "SPN" SG_ 2566845182 EngThrottleValve1Pos 51;
BA_ "SigType" SG_ 2566845182 EngThrottleValve1Pos 1;
BA_ "SPN" SG_ 2566845182 EngAverageFuelEconomy 185;
BA_ "SigType" SG_ 2566845182 EngAverageFuelEconomy 1;
BA_ "SPN" SG_ 2566845182 EngInstantaneousFuelEconomy 184;
BA_ "SigType" SG_ 2566845182 EngInstantaneousFuelEconomy 1;
BA_ "SPN" SG_ 2566845182 EngFuelRate 183;
BA_ "SigType" SG_ 2566845182 EngFuelRate 1;
BA_ "SPN" SG_ 2566842878 EngTotalFuelUsed 250;
BA_ "SigType" SG_ 2566842878 EngTotalFuelUsed 1;
BA_ "SPN" SG_ 2566842878 EngTripFuel 182;
BA_ "SigType" SG_ 2566842878 EngTripFuel 1;
BA_ "SPN" SG_ 2633883646 FrontWheelDriveActuatorStatus 2612;
BA_ "SigType" SG_ 2633883646 FrontWheelDriveActuatorStatus 4;
BA_ "SPN" SG_ 2633880062 FMSstandardSWversionSupported 2806;
BA_ "SigType" SG_ 2633880062 FMSstandardSWversionSupported 1;
BA_ "SPN" SG_ 2633880062 FMSstandardRequestsSupported 2805;
BA_ "SigType" SG_ 2633880062 FMSstandardRequestsSupported 5;
BA_ "SPN" SG_ 2633880062 FMSstandardDiagnosticsSupported 2804;
BA_ "SigType" SG_ 2633880062 FMSstandardDiagnosticsSupported 5;
BA_ "SPN" SG_ 2566806526 DrverAlertnessWarningSystemState 7475;
BA_ "SPN" SG_ 2566806526 DriverAlertnessLevel 7474;
BA_ "SigType" SG_ 2566806526 DriverAlertnessLevel 1;
BA_ "SPN" SG_ 2566806526 LnDpartureIndicationEnableStatus 1702;
BA_ "SigType" SG_ 2566806526 LnDpartureIndicationEnableStatus 5;
BA_ "SPN" SG_ 2566806526 LaneTrackingStatusLeftSide 1710;
BA_ "SigType" SG_ 2566806526 LaneTrackingStatusLeftSide 5;
BA_ "SPN" SG_ 2566806526 LaneTrackingStatusRightSide 1711;
BA_ "SigType" SG_ 2566806526 LaneTrackingStatusRightSide 5;
BA_ "SPN" SG_ 2431649790 LaneDepartureImminentLeftSide 1700;
BA_ "SigType" SG_ 2431649790 LaneDepartureImminentLeftSide 5;
BA_ "SPN" SG_ 2431649790 LaneDepartureImminentRightSide 1701;
BA_ "SigType" SG_ 2431649790 LaneDepartureImminentRightSide 5;
BA_ "SPN" SG_ 2431649790 LaneDepartureRight 3566;
BA_ "SigType" SG_ 2431649790 LaneDepartureRight 5;
BA_ "SPN" SG_ 2431649790 LaneDepartureLeft 3565;
BA_ "SigType" SG_ 2431649790 LaneDepartureLeft 5;
BA_ "SPN" SG_ 2431649790 DriverAlertnessWarning 7473;
BA_ "SPN" SG_ 2633929214 EngFuelLeakage2 1240;
BA_ "SigType" SG_ 2633929214 EngFuelLeakage2 5;
BA_ "SPN" SG_ 2633929214 EngFuelLeakage1 1239;
BA_ "SigType" SG_ 2633929214 EngFuelLeakage1 5;
BA_ "SPN" SG_ 2566831614 FanDriveBypassCmdStatus 4212;
BA_ "SigType" SG_ 2566831614 FanDriveBypassCmdStatus 1;
BA_ "SPN" SG_ 2566831614 HydFanMotorPress 4211;
BA_ "SigType" SG_ 2566831614 HydFanMotorPress 1;
BA_ "SPN" SG_ 2566831614 FanSpeed 1639;
BA_ "SigType" SG_ 2566831614 FanSpeed 1;
BA_ "SPN" SG_ 2566831614 FanDriveState 977;
BA_ "SPN" SG_ 2566831614 EstPercentFanSpeed 975;
BA_ "SigType" SG_ 2566831614 EstPercentFanSpeed 1;
BA_ "SPN" SG_ 2566820094 EngTorqueLimit6AxleInput 1263;
BA_ "SigType" SG_ 2566820094 EngTorqueLimit6AxleInput 1;
BA_ "SPN" SG_ 2566820094 EngTorqueLimit5Switch 1262;
BA_ "SigType" SG_ 2566820094 EngTorqueLimit5Switch 1;
BA_ "SPN" SG_ 2566820094 EngTorqueLimit4Trans 1261;
BA_ "SigType" SG_ 2566820094 EngTorqueLimit4Trans 1;
BA_ "SPN" SG_ 2566820094 EngTorqueLimit3Trans 1260;
BA_ "SigType" SG_ 2566820094 EngTorqueLimit3Trans 1;
BA_ "SPN" SG_ 2566820094 TransGearRatio3 1259;
BA_ "SigType" SG_ 2566820094 TransGearRatio3 1;
BA_ "SPN" SG_ 2566820094 EngTorqueLimit2Trans 1258;
BA_ "SigType" SG_ 2566820094 EngTorqueLimit2Trans 1;
BA_ "SPN" SG_ 2566820094 TransGearRatio2 1257;
BA_ "SigType" SG_ 2566820094 TransGearRatio2 1;
BA_ "SPN" SG_ 2566820094 EngTorqueLimit1Trans 1256;
BA_ "SigType" SG_ 2566820094 EngTorqueLimit1Trans 1;
BA_ "SPN" SG_ 2566820094 TransGearRatio1 1255;
BA_ "SigType" SG_ 2566820094 TransGearRatio1 1;
BA_ "SPN" SG_ 2566820094 EngTorqueLimitFeature 1632;
BA_ "SPN" SG_ 2566820094 TorqueLimitingFeatureStatus 1254;
BA_ "SigType" SG_ 2566820094 TorqueLimitingFeatureStatus 5;
BA_ "SPN" SG_ 2566820094 CalibRecordDurationTime 1253;
BA_ "SigType" SG_ 2566820094 CalibRecordDurationTime 1;
BA_ "SPN" SG_ 2566820094 CalibRecordStartYear 1252;
BA_ "SigType" SG_ 2566820094 CalibRecordStartYear 1;
BA_ "SPN" SG_ 2566820094 CalibRecordStartDay 1251;
BA_ "GenSigStartValue" SG_ 2566820094 CalibRecordStartDay 1;
BA_ "SigType" SG_ 2566820094 CalibRecordStartDay 1;
BA_ "SPN" SG_ 2566820094 CalibRecordStartMonth 1250;
BA_ "GenSigStartValue" SG_ 2566820094 CalibRecordStartMonth 1;
BA_ "SigType" SG_ 2566820094 CalibRecordStartMonth 1;
BA_ "SPN" SG_ 2566820094 EngPeakTorque2 1249;
BA_ "SigType" SG_ 2566820094 EngPeakTorque2 1;
BA_ "SPN" SG_ 2566820094 EngPeakTorque1 1248;
BA_ "SigType" SG_ 2566820094 EngPeakTorque1 1;
BA_ "SPN" SG_ 2566820094 EngPower 1247;
BA_ "SigType" SG_ 2566820094 EngPower 1;
BA_ "SPN" SG_ 2566820094 NumberOfEngTorqueHistoryRecords 1246;
BA_ "SigType" SG_ 2566820094 NumberOfEngTorqueHistoryRecords 1;
BA_ "SPN" SG_ 2364542206 TransClutch_ConverterInputSpeed 5052;
BA_ "SigType" SG_ 2364542206 TransClutch_ConverterInputSpeed 1;
BA_ "SPN" SG_ 2364542206 TransTorqueConverterRatio 3030;
BA_ "SigType" SG_ 2364542206 TransTorqueConverterRatio 1;
BA_ "SPN" SG_ 2566802174 TransAutoNeutralSt 7696;
BA_ "SigType" SG_ 2566802174 TransAutoNeutralSt 5;
BA_ "SPN" SG_ 2566802174 TransWarningIndicator 5344;
BA_ "SigType" SG_ 2566802174 TransWarningIndicator 5;
BA_ "SPN" SG_ 2566802174 TrnsRverseGearShiftInhibitStatus 4261;
BA_ "SigType" SG_ 2566802174 TrnsRverseGearShiftInhibitStatus 4;
BA_ "SPN" SG_ 2566802174 TransMode8Indicator 4253;
BA_ "SigType" SG_ 2566802174 TransMode8Indicator 4;
BA_ "SPN" SG_ 2566802174 TransMode7Indicator 4252;
BA_ "SigType" SG_ 2566802174 TransMode7Indicator 4;
BA_ "SPN" SG_ 2566802174 TransMode6Indicator 4251;
BA_ "SigType" SG_ 2566802174 TransMode6Indicator 4;
BA_ "SPN" SG_ 2566802174 TransMode5Indicator 4250;
BA_ "SigType" SG_ 2566802174 TransMode5Indicator 4;
BA_ "SPN" SG_ 2566802174 TransRequestedGearFeedback 3289;
BA_ "SigType" SG_ 2566802174 TransRequestedGearFeedback 1;
BA_ "SPN" SG_ 2566802174 TransMode1Indicator 2536;
BA_ "SigType" SG_ 2566802174 TransMode1Indicator 4;
BA_ "SPN" SG_ 2566802174 TransMode2Indicator 2537;
BA_ "SigType" SG_ 2566802174 TransMode2Indicator 4;
BA_ "SPN" SG_ 2566802174 TransMode3Indicator 2538;
BA_ "SigType" SG_ 2566802174 TransMode3Indicator 4;
BA_ "SPN" SG_ 2566802174 TransMode4Indicator 2539;
BA_ "SigType" SG_ 2566802174 TransMode4Indicator 4;
BA_ "SPN" SG_ 2566802174 TransShiftInhibitIndicator 1851;
BA_ "SigType" SG_ 2566802174 TransShiftInhibitIndicator 5;
BA_ "SPN" SG_ 2566802174 TransEngCrankEnable 2900;
BA_ "SigType" SG_ 2566802174 TransEngCrankEnable 5;
BA_ "SPN" SG_ 2566802174 ActiveShiftConsoleIndicator 2945;
BA_ "SigType" SG_ 2566802174 ActiveShiftConsoleIndicator 5;
BA_ "SPN" SG_ 2566802174 TransReadyForBrakeRelease 3086;
BA_ "SigType" SG_ 2566802174 TransReadyForBrakeRelease 5;
BA_ "SPN" SG_ 2566802174 TrnsRqstedRangeDisplayFlashState 1849;
BA_ "SigType" SG_ 2566802174 TrnsRqstedRangeDisplayFlashState 5;
BA_ "SPN" SG_ 2566802174 TrnsRqstedRangeDisplayBlankState 1850;
BA_ "SigType" SG_ 2566802174 TrnsRqstedRangeDisplayBlankState 5;
BA_ "SPN" SG_ 2566802174 TransServiceIndicator 4178;
BA_ "SigType" SG_ 2566802174 TransServiceIndicator 5;
BA_ "SPN" SG_ 2566802174 TransAirSupplyPressIndicator 6566;
BA_ "SigType" SG_ 2566802174 TransAirSupplyPressIndicator 4;
BA_ "SPN" SG_ 2566802174 TransMode10Indicator 6568;
BA_ "SigType" SG_ 2566802174 TransMode10Indicator 4;
BA_ "SPN" SG_ 2566802174 TransMode9Indicator 6567;
BA_ "SigType" SG_ 2566802174 TransMode9Indicator 4;
BA_ "SPN" SG_ 2566802174 TrnsCrrentRangeDisplayBlankState 4176;
BA_ "SigType" SG_ 2566802174 TrnsCrrentRangeDisplayBlankState 5;
BA_ "SPN" SG_ 2633935870 ClutchLifeRemaining 2983;
BA_ "SigType" SG_ 2633935870 ClutchLifeRemaining 1;
BA_ "SPN" SG_ 2633935870 LowestPossibleGear 1114;
BA_ "SigType" SG_ 2633935870 LowestPossibleGear 1;
BA_ "SPN" SG_ 2633935870 HighestPossibleGear 1115;
BA_ "SigType" SG_ 2633935870 HighestPossibleGear 1;
BA_ "SPN" SG_ 2633935870 RecommendedGear 1113;
BA_ "SigType" SG_ 2633935870 RecommendedGear 1;
BA_ "SPN" SG_ 2633942014 TransForwardDirectionSwitch 903;
BA_ "SigType" SG_ 2633942014 TransForwardDirectionSwitch 5;
BA_ "SPN" SG_ 2633942014 TransNeutralSwitch 604;
BA_ "SigType" SG_ 2633942014 TransNeutralSwitch 5;
BA_ "SPN" SG_ 2633942014 TransReverseDirectionSwitch 767;
BA_ "SigType" SG_ 2633942014 TransReverseDirectionSwitch 5;
BA_ "SPN" SG_ 2633942014 TransLowRangeSenseSwitch 779;
BA_ "SigType" SG_ 2633942014 TransLowRangeSenseSwitch 5;
BA_ "SPN" SG_ 2633942014 TransHighRangeSenseSwitch 778;
BA_ "SigType" SG_ 2633942014 TransHighRangeSenseSwitch 5;
BA_ "SPN" SG_ 2633942526 TransSynchronizerBrakeValue 54;
BA_ "SigType" SG_ 2633942526 TransSynchronizerBrakeValue 1;
BA_ "SPN" SG_ 2633942526 TransSynchronizerClutchValue 53;
BA_ "SigType" SG_ 2633942526 TransSynchronizerClutchValue 1;
BA_ "SPN" SG_ 2633943038 TransInertiaBrakeActuator 787;
BA_ "SigType" SG_ 2633943038 TransInertiaBrakeActuator 5;
BA_ "SPN" SG_ 2633943038 TransDefuelActuator 786;
BA_ "SigType" SG_ 2633943038 TransDefuelActuator 5;
BA_ "SPN" SG_ 2633943038 TransLockupClutchActuator 740;
BA_ "SigType" SG_ 2633943038 TransLockupClutchActuator 5;
BA_ "SPN" SG_ 2633943038 TransClutchActuator 788;
BA_ "SigType" SG_ 2633943038 TransClutchActuator 5;
BA_ "SPN" SG_ 2633943038 TransSplitterIndirectActuator 771;
BA_ "SigType" SG_ 2633943038 TransSplitterIndirectActuator 5;
BA_ "SPN" SG_ 2633943038 TransSplitterDirectActuator 770;
BA_ "SigType" SG_ 2633943038 TransSplitterDirectActuator 5;
BA_ "SPN" SG_ 2633943038 TransRangeLowActuator 769;
BA_ "SigType" SG_ 2633943038 TransRangeLowActuator 5;
BA_ "SPN" SG_ 2633943038 TransRangeHighActuator 768;
BA_ "SigType" SG_ 2633943038 TransRangeHighActuator 5;
BA_ "SPN" SG_ 2633943038 TransShiftFingerGearActuator2 784;
BA_ "SigType" SG_ 2633943038 TransShiftFingerGearActuator2 5;
BA_ "SPN" SG_ 2633943038 TransShiftFingerRailActuator2 783;
BA_ "SigType" SG_ 2633943038 TransShiftFingerRailActuator2 5;
BA_ "SPN" SG_ 2633943038 TransShiftFingerGearActuator1 773;
BA_ "SigType" SG_ 2633943038 TransShiftFingerGearActuator1 5;
BA_ "SPN" SG_ 2633943038 TransShiftFingerRailActuator1 772;
BA_ "SigType" SG_ 2633943038 TransShiftFingerRailActuator1 5;
BA_ "SPN" SG_ 2633943038 TrnsShftFngerCenterRailIndicator 782;
BA_ "SigType" SG_ 2633943038 TrnsShftFngerCenterRailIndicator 5;
BA_ "SPN" SG_ 2633943038 TrnsShftFngerEngagementIndicator 781;
BA_ "SigType" SG_ 2633943038 TrnsShftFngerEngagementIndicator 5;
BA_ "SPN" SG_ 2633943038 TransShiftFingerNeutralIndicator 780;
BA_ "SigType" SG_ 2633943038 TransShiftFingerNeutralIndicator 5;
BA_ "SPN" SG_ 2633943038 TransShiftFingerRailPos 60;
BA_ "SigType" SG_ 2633943038 TransShiftFingerRailPos 1;
BA_ "SPN" SG_ 2633943038 TransShiftFingerGearPos 59;
BA_ "SigType" SG_ 2633943038 TransShiftFingerGearPos 1;
BA_ "SPN" SG_ 2565867006 TransCurrentRange 163;
BA_ "SigType" SG_ 2565867006 TransCurrentRange 1;
BA_ "SPN" SG_ 2565867006 TransRequestedRange 162;
BA_ "SigType" SG_ 2565867006 TransRequestedRange 1;
BA_ "SPN" SG_ 2565867006 TransCurrentGear 523;
BA_ "SigType" SG_ 2565867006 TransCurrentGear 1;
BA_ "SPN" SG_ 2565867006 TransActualGearRatio 526;
BA_ "SigType" SG_ 2565867006 TransActualGearRatio 1;
BA_ "SPN" SG_ 2565867006 TransSelectedGear 524;
BA_ "SigType" SG_ 2565867006 TransSelectedGear 1;
BA_ "SPN" SG_ 2364539646 SrcAddrssOfCntrllngDvcFrTrnsCtrl 1482;
BA_ "SPN" SG_ 2364539646 TransInputShaftSpeed 161;
BA_ "SigType" SG_ 2364539646 TransInputShaftSpeed 1;
BA_ "SPN" SG_ 2364539646 MomentaryEngMaxPowerEnable 5015;
BA_ "SigType" SG_ 2364539646 MomentaryEngMaxPowerEnable 5;
BA_ "SPN" SG_ 2364539646 ProgressiveShiftDisable 607;
BA_ "SigType" SG_ 2364539646 ProgressiveShiftDisable 5;
BA_ "SPN" SG_ 2364539646 EngMomentaryOverspeedEnable 606;
BA_ "SigType" SG_ 2364539646 EngMomentaryOverspeedEnable 5;
BA_ "SPN" SG_ 2364539646 PercentClutchSlip 522;
BA_ "SigType" SG_ 2364539646 PercentClutchSlip 1;
BA_ "SPN" SG_ 2364539646 TransOutputShaftSpeed 191;
BA_ "SigType" SG_ 2364539646 TransOutputShaftSpeed 1;
BA_ "SPN" SG_ 2364539646 TrnsTrqCnvrtrLckpTrnstnInProcess 4816;
BA_ "SigType" SG_ 2364539646 TrnsTrqCnvrtrLckpTrnstnInProcess 4;
BA_ "SPN" SG_ 2364539646 TransShiftInProcess 574;
BA_ "SigType" SG_ 2364539646 TransShiftInProcess 4;
BA_ "SPN" SG_ 2364539646 TrnsTorqueConverterLockupEngaged 573;
BA_ "SigType" SG_ 2364539646 TrnsTorqueConverterLockupEngaged 5;
BA_ "SPN" SG_ 2364539646 TransDrivelineEngaged 560;
BA_ "SigType" SG_ 2364539646 TransDrivelineEngaged 4;
BA_ "SPN" SG_ 2566810110 EngChargeAirCooler1OutletTemp 2630;
BA_ "SigType" SG_ 2566810110 EngChargeAirCooler1OutletTemp 1;
BA_ "SPN" SG_ 2566810110 EngIntkVlvActuationSystemOilTemp 2986;
BA_ "SigType" SG_ 2566810110 EngIntkVlvActuationSystemOilTemp 1;
BA_ "SPN" SG_ 2566810110 EngCoolantTemp 1637;
BA_ "SigType" SG_ 2566810110 EngCoolantTemp 1;
BA_ "SPN" SG_ 2566810110 EngIntakeManifold1AirTemp 1636;
BA_ "SigType" SG_ 2566810110 EngIntakeManifold1AirTemp 1;
BA_ "SPN" SG_ 2566825214 EngExhaustGasRecirculation1Temp 412;
BA_ "SigType" SG_ 2566825214 EngExhaustGasRecirculation1Temp 1;
BA_ "SPN" SG_ 2566825214 EngExhstGsRcirculation1DiffPress 411;
BA_ "SigType" SG_ 2566825214 EngExhstGsRcirculation1DiffPress 1;
BA_ "SPN" SG_ 2566825214 EngECUTemp 1136;
BA_ "SigType" SG_ 2566825214 EngECUTemp 1;
BA_ "SPN" SG_ 2566825214 EngOilTemp2 1135;
BA_ "SigType" SG_ 2566825214 EngOilTemp2 1;
BA_ "SPN" SG_ 2566844158 EngIntercoolerThermostatOpening 1134;
BA_ "SigType" SG_ 2566844158 EngIntercoolerThermostatOpening 1;
BA_ "SPN" SG_ 2566844158 EngIntercoolerTemp 52;
BA_ "SigType" SG_ 2566844158 EngIntercoolerTemp 1;
BA_ "SPN" SG_ 2566844158 EngTurboOilTemp 176;
BA_ "SigType" SG_ 2566844158 EngTurboOilTemp 1;
BA_ "SPN" SG_ 2566844158 EngOilTemp1 175;
BA_ "SigType" SG_ 2566844158 EngOilTemp1 1;
BA_ "SPN" SG_ 2566844158 EngFuelTemp1 174;
BA_ "SigType" SG_ 2566844158 EngFuelTemp1 1;
BA_ "SPN" SG_ 2566844158 EngCoolantTemp 110;
BA_ "SigType" SG_ 2566844158 EngCoolantTemp 1;
BA_ "SPN" SG_ 2566785022 EngExhaustManifoldBank1Temp2 5970;
BA_ "SigType" SG_ 2566785022 EngExhaustManifoldBank1Temp2 1;
BA_ "SPN" SG_ 2566785022 EngExhaustManifoldBank2Temp2 5969;
BA_ "SigType" SG_ 2566785022 EngExhaustManifoldBank2Temp2 1;
BA_ "SPN" SG_ 2566785022 EngExhaustGasTempLeftManifold 2434;
BA_ "SigType" SG_ 2566785022 EngExhaustGasTempLeftManifold 1;
BA_ "SPN" SG_ 2566785022 EngExhaustGasTempRightManifold 2433;
BA_ "SigType" SG_ 2566785022 EngExhaustGasTempRightManifold 1;
BA_ "SPN" SG_ 2565868542 TypeOfSteerTrans 2926;
BA_ "SPN" SG_ 2565868542 TypeOfSteerForces 2925;
BA_ "SPN" SG_ 2565868542 SteerType 2924;
BA_ "SPN" SG_ 2565868542 SteerableLiftAxleLoweringInhibit 2922;
BA_ "SigType" SG_ 2565868542 SteerableLiftAxleLoweringInhibit 5;
BA_ "SPN" SG_ 2565868542 StatusOfSteerAxle 2923;
BA_ "SPN" SG_ 2565868542 AxleLocation 2928;
BA_ "SPN" SG_ 2565868542 ActualInnerWheelSteerAngle 2927;
BA_ "SigType" SG_ 2565868542 ActualInnerWheelSteerAngle 1;
BA_ "SPN" SG_ 2633941758 CrsCtrlRetarderActiveSpeedOffset 7496;
BA_ "GenSigStartValue" SG_ 2633941758 CrsCtrlRetarderActiveSpeedOffset 32000;
BA_ "SigType" SG_ 2633941758 CrsCtrlRetarderActiveSpeedOffset 1;
BA_ "SPN" SG_ 2633941758 TransOutputRetarder 748;
BA_ "SigType" SG_ 2633941758 TransOutputRetarder 5;
BA_ "SPN" SG_ 2565865726 ActlMxAvlblRetarderPercentTorque 1717;
BA_ "SigType" SG_ 2565865726 ActlMxAvlblRetarderPercentTorque 1;
BA_ "SPN" SG_ 2565865726 RetarderSelectionNonengine 1716;
BA_ "SigType" SG_ 2565865726 RetarderSelectionNonengine 1;
BA_ "SPN" SG_ 2565865726 DrvrsDemandRetarderPercentTorque 1715;
BA_ "SigType" SG_ 2565865726 DrvrsDemandRetarderPercentTorque 1;
BA_ "SPN" SG_ 2565865726 SrcAddrssOfCntrllngDvcFrRtrdrCtr 1480;
BA_ "SPN" SG_ 2565865726 RetarderRoadSpeedExceededStatus 4234;
BA_ "SigType" SG_ 2565865726 RetarderRoadSpeedExceededStatus 5;
BA_ "SPN" SG_ 2565865726 RetarderRoadSpeedLimitSwitch 4233;
BA_ "SigType" SG_ 2565865726 RetarderRoadSpeedLimitSwitch 4;
BA_ "SPN" SG_ 2565865726 RetarderRequestingBrakeLight 1667;
BA_ "SigType" SG_ 2565865726 RetarderRequestingBrakeLight 5;
BA_ "SPN" SG_ 2565865726 EngCoolantLoadIncrease 1082;
BA_ "SigType" SG_ 2565865726 EngCoolantLoadIncrease 5;
BA_ "SPN" SG_ 2565865726 IntendedRetarderPercentTorque 1085;
BA_ "SigType" SG_ 2565865726 IntendedRetarderPercentTorque 1;
BA_ "SPN" SG_ 2565865726 ActualRetarderPercentTorque 520;
BA_ "SigType" SG_ 2565865726 ActualRetarderPercentTorque 1;
BA_ "SPN" SG_ 2565865726 RetarderEnableShiftAssistSwitch 572;
BA_ "SigType" SG_ 2565865726 RetarderEnableShiftAssistSwitch 4;
BA_ "SPN" SG_ 2565865726 RetarderEnableBrakeAssistSwitch 571;
BA_ "SigType" SG_ 2565865726 RetarderEnableBrakeAssistSwitch 4;
BA_ "SPN" SG_ 2565865726 RetarderTorqueMode 900;
BA_ "SPN" SG_ 2633932798 EngExhaustGasPort20Temp 1156;
BA_ "SigType" SG_ 2633932798 EngExhaustGasPort20Temp 1;
BA_ "SPN" SG_ 2633932798 EngExhaustGasPort19Temp 1155;
BA_ "SigType" SG_ 2633932798 EngExhaustGasPort19Temp 1;
BA_ "SPN" SG_ 2633932798 EngExhaustGasPort18Temp 1154;
BA_ "SigType" SG_ 2633932798 EngExhaustGasPort18Temp 1;
BA_ "SPN" SG_ 2633932798 EngExhaustGasPort17Temp 1153;
BA_ "SigType" SG_ 2633932798 EngExhaustGasPort17Temp 1;
BA_ "SPN" SG_ 2566824190 EngExhaustGasPort16Temp 1152;
BA_ "SigType" SG_ 2566824190 EngExhaustGasPort16Temp 1;
BA_ "SPN" SG_ 2566824190 EngExhaustGasPort15Temp 1151;
BA_ "SigType" SG_ 2566824190 EngExhaustGasPort15Temp 1;
BA_ "SPN" SG_ 2566824190 EngExhaustGasPort14Temp 1150;
BA_ "SigType" SG_ 2566824190 EngExhaustGasPort14Temp 1;
BA_ "SPN" SG_ 2566824190 EngExhaustGasPort13Temp 1149;
BA_ "SigType" SG_ 2566824190 EngExhaustGasPort13Temp 1;
BA_ "SPN" SG_ 2633933310 EngExhaustGasPort12Temp 1148;
BA_ "SigType" SG_ 2633933310 EngExhaustGasPort12Temp 1;
BA_ "SPN" SG_ 2633933310 EngExhaustGasPort11Temp 1147;
BA_ "SigType" SG_ 2633933310 EngExhaustGasPort11Temp 1;
BA_ "SPN" SG_ 2633933310 EngExhaustGasPort10Temp 1146;
BA_ "SigType" SG_ 2633933310 EngExhaustGasPort10Temp 1;
BA_ "SPN" SG_ 2633933310 EngExhaustGasPort9Temp 1145;
BA_ "SigType" SG_ 2633933310 EngExhaustGasPort9Temp 1;
BA_ "SPN" SG_ 2633933566 EngExhaustGasPort8Temp 1144;
BA_ "SigType" SG_ 2633933566 EngExhaustGasPort8Temp 1;
BA_ "SPN" SG_ 2633933566 EngExhaustGasPort7Temp 1143;
BA_ "SigType" SG_ 2633933566 EngExhaustGasPort7Temp 1;
BA_ "SPN" SG_ 2633933566 EngExhaustGasPort6Temp 1142;
BA_ "SigType" SG_ 2633933566 EngExhaustGasPort6Temp 1;
BA_ "SPN" SG_ 2633933566 EngExhaustGasPort5Temp 1141;
BA_ "SigType" SG_ 2633933566 EngExhaustGasPort5Temp 1;
BA_ "SPN" SG_ 2633933822 EngExhaustGasPort4Temp 1140;
BA_ "SigType" SG_ 2633933822 EngExhaustGasPort4Temp 1;
BA_ "SPN" SG_ 2633933822 EngExhaustGasPort3Temp 1139;
BA_ "SigType" SG_ 2633933822 EngExhaustGasPort3Temp 1;
BA_ "SPN" SG_ 2633933822 EngExhaustGasPort2Temp 1138;
BA_ "SigType" SG_ 2633933822 EngExhaustGasPort2Temp 1;
BA_ "SPN" SG_ 2633933822 EngExhaustGasPort1Temp 1137;
BA_ "SigType" SG_ 2633933822 EngExhaustGasPort1Temp 1;
BA_ "SPN" SG_ 2566776062 PayloadCapacityPercentage 6854;
BA_ "SigType" SG_ 2566776062 PayloadCapacityPercentage 1;
BA_ "SPN" SG_ 2566776062 PayloadCarryBackWeight 6853;
BA_ "SigType" SG_ 2566776062 PayloadCarryBackWeight 1;
BA_ "SPN" SG_ 2566776062 PayloadWeightConfidence 6852;
BA_ "SigType" SG_ 2566776062 PayloadWeightConfidence 1;
BA_ "SPN" SG_ 2566776062 PayloadWeight 6851;
BA_ "SPN" SG_ 2566776062 PayloadPercentage 2600;
BA_ "SigType" SG_ 2566776062 PayloadPercentage 1;
BA_ "SPN" SG_ 2566771454 DataMemoryUsage 2802;
BA_ "SigType" SG_ 2566771454 DataMemoryUsage 1;
BA_ "SPN" SG_ 2566771454 KeepAliveBatteryConsumption 2803;
BA_ "SigType" SG_ 2566771454 KeepAliveBatteryConsumption 1;
BA_ "SPN" SG_ 2566775806 TravelVelocityCtrlPos 2601;
BA_ "SigType" SG_ 2566775806 TravelVelocityCtrlPos 1;
BA_ "SPN" SG_ 2633935358 EngExhstGsOxygnSnsrClsdLpOprtion 1696;
BA_ "SigType" SG_ 2633935358 EngExhstGsOxygnSnsrClsdLpOprtion 5;
BA_ "SPN" SG_ 2633935358 EngExhstGsOxygnSnsrFlngCrrection 1695;
BA_ "SigType" SG_ 2633935358 EngExhstGsOxygnSnsrFlngCrrection 1;
BA_ "SPN" SG_ 2633935358 EngActualExhaustOxygen 1119;
BA_ "SigType" SG_ 2633935358 EngActualExhaustOxygen 1;
BA_ "SPN" SG_ 2633935358 EngDesiredExhaustOxygen 1118;
BA_ "SigType" SG_ 2633935358 EngDesiredExhaustOxygen 1;
BA_ "SPN" SG_ 2633935358 EngDesiredRatedExhaustOxygen 1117;
BA_ "SigType" SG_ 2633935358 EngDesiredRatedExhaustOxygen 1;
BA_ "SPN" SG_ 2365447166 Joystick3Button13PressedStatus 6739;
BA_ "SigType" SG_ 2365447166 Joystick3Button13PressedStatus 4;
BA_ "SPN" SG_ 2365447166 Joystick3Button14PressedStatus 6740;
BA_ "SigType" SG_ 2365447166 Joystick3Button14PressedStatus 4;
BA_ "SPN" SG_ 2365447166 Joystick3Button15PressedStatus 6741;
BA_ "SigType" SG_ 2365447166 Joystick3Button15PressedStatus 4;
BA_ "SPN" SG_ 2365447166 Joystick3Button16PressedStatus 6742;
BA_ "SigType" SG_ 2365447166 Joystick3Button16PressedStatus 4;
BA_ "SPN" SG_ 2365447166 Jystick3GripXAxisDetentPosStatus 2756;
BA_ "SigType" SG_ 2365447166 Jystick3GripXAxisDetentPosStatus 4;
BA_ "SPN" SG_ 2365447166 Jystick3GripYAxisDetentPosStatus 2757;
BA_ "SigType" SG_ 2365447166 Jystick3GripYAxisDetentPosStatus 4;
BA_ "SPN" SG_ 2365447166 Jystick3ThetaAxisDetentPosStatus 2758;
BA_ "SigType" SG_ 2365447166 Jystick3ThetaAxisDetentPosStatus 4;
BA_ "SPN" SG_ 2365447166 Joystick3ThetaAxisPos 2738;
BA_ "SPN" SG_ 2365447166 Jystck3ThtAxsClckwsPstvPosStatus 2743;
BA_ "SigType" SG_ 2365447166 Jystck3ThtAxsClckwsPstvPosStatus 4;
BA_ "SPN" SG_ 2365447166 Jystck3ThetaAxisNeutralPosStatus 2753;
BA_ "SigType" SG_ 2365447166 Jystck3ThetaAxisNeutralPosStatus 4;
BA_ "SPN" SG_ 2365447166 Joystick3GripYAxisPos 2737;
BA_ "SPN" SG_ 2365447166 Jystck3GrpYAxsLvrFrwrdPstvPsStts 2742;
BA_ "SigType" SG_ 2365447166 Jystck3GrpYAxsLvrFrwrdPstvPsStts 4;
BA_ "SPN" SG_ 2365447166 Jystck3GrpYAxsLvrBckNgtvPsStatus 2747;
BA_ "SigType" SG_ 2365447166 Jystck3GrpYAxsLvrBckNgtvPsStatus 4;
BA_ "SPN" SG_ 2365447166 Jystck3GripYAxisNeutralPosStatus 2752;
BA_ "SigType" SG_ 2365447166 Jystck3GripYAxisNeutralPosStatus 4;
BA_ "SPN" SG_ 2365447166 Joystick3GripXAxisPos 2736;
BA_ "SPN" SG_ 2365447166 Jystck3GrpXAxsLvrRghtPstvPsSttus 2741;
BA_ "SigType" SG_ 2365447166 Jystck3GrpXAxsLvrRghtPstvPsSttus 4;
BA_ "SPN" SG_ 2365447166 Jystck3GrpXAxsLvrLftNgtvPsStatus 2746;
BA_ "SigType" SG_ 2365447166 Jystck3GrpXAxsLvrLftNgtvPsStatus 4;
BA_ "SPN" SG_ 2365447166 Jystck3GripXAxisNeutralPosStatus 2751;
BA_ "SigType" SG_ 2365447166 Jystck3GripXAxisNeutralPosStatus 4;
BA_ "SPN" SG_ 2365447166 Jystck3ThtAxsCntrClckwsNgtvPsStt 2748;
BA_ "SigType" SG_ 2365447166 Jystck3ThtAxsCntrClckwsNgtvPsStt 4;
VAL_ 2631859966 SteerStraightAheadPosReset 3 "Not applicable" 2 "Reserved" 1 "Reset" 0 "Take no action" ;
VAL_ 2631859966 EngBuildHoursReset 3 "Take no action" 2 "Reserved" 1 "Reset" 0 "Do not reset" ;
VAL_ 2631859966 EngIgntCtrlMaintenanceHoursReset 3 "Take no action" 2 "Reserved" 1 "Reset" 0 "Do not reset" ;
VAL_ 2631859966 EngSprkPlgScndVltgeTrackingReset 3 "Take no action" 2 "Reserved" 1 "Reset" 0 "Do not reset" ;
VAL_ 2631859966 TripGroup2Proprietary 3 "Not applicable" 2 "Reserved" 1 "Reset" 0 "Take no action" ;
VAL_ 2631859966 TireSensorInformation 3 "Not applicable" 2 "Reserved" 1 "Reset" 0 "Take no action" ;
VAL_ 2631859966 TireConfigInformation 3 "Not Applicable" 2 "Reserved" 1 "Reset" 0 "Take No Action" ;
VAL_ 2631859966 BinLiftCountReset 3 "Take no action" 2 "Reserved" 1 "Reset" 0 "Do not reset" ;
VAL_ 2631859966 TripGroup1 3 "Not applicable" 2 "Reserved" 1 "Reset" 0 "Take no action" ;
VAL_ 2566840830 RetarderLocation 15 "Not available" 14 "Other" 5 "Trailer" 4 "(Secondary)    Driveline" 3 "(Secondary)    Transmission Output" 2 "(Primary)         Transmission Input" 1 "(Primary)         Engine Exhaust Brake" 0 "(Primary)        Engine Compression Release Brake or Engine Compression Release Brake Combined with Engine Exhaust Brake" ;
VAL_ 2566840830 RetarderType 15 "Not available" 14 "Other" 4 "Exhaust" 3 "Compression Release" 2 "Cooled Friction" 1 "Hydraulic" 0 "Electric/Magnetic" ;
VAL_ 2566844670 OprtrEngPTOGvrnrMmrySelectSwitch 3 "not available" 2 "error" 1 "PTO set speed memory 2 selected" 0 "PTO set speed memory 1 selected" ;
VAL_ 2566844670 EngRmtPTOGvrnrVrblSpedCtrlSwitch 3 "Not available" 2 "Error" 1 "On" 0 "Off" ;
VAL_ 2566844670 EngRmtPTOGvrnrPrprgrmmdSpdCtrlSw 3 "Not available" 2 "Error" 1 "On" 0 "Off" ;
VAL_ 2566844670 EngPTOGvrnrCast_DecelerateSwitch 3 "Not available" 2 "Error" 1 "On" 0 "Off" ;
VAL_ 2566844670 EngPTOGovernorSetSwitch 3 "Not available" 2 "Error" 1 "On" 0 "Off" ;
VAL_ 2566844670 EngPTOGovernorResumeSwitch 3 "Not available" 2 "Error" 1 "On" 0 "Off" ;
VAL_ 2566844670 EngPTOGovernorEnableSwitch 3 "Not available" 2 "Error" 1 "On" 0 "Off" ;
VAL_ 2566844670 EngPTOGovernorAccelerateSwitch 3 "Not available" 2 "Error" 1 "On" 0 "Off" ;
VAL_ 2566844670 RmtPTOGvrnrPrprgrmmdSpdCtrlSwtch 3 "Not Available" 2 "Error" 1 "On" 0 "Off" ;
VAL_ 2566844670 AuxInputIgnoreSwitch 3 "Not Available" 2 "Error" 1 "On" 0 "Off" ;
VAL_ 2566770174 RearWasherFunction 7 "Not available" 3 "High" 2 "Medium" 1 "Low" 0 "Off" ;
VAL_ 2566770174 FrontOperatorWasherSwitch 7 "Not available" 3 "High" 2 "Medium" 1 "Low" 0 "Off" ;
VAL_ 2566770174 FrontNonoperatorWasherSwitch 7 "Not available" 3 "High" 2 "Medium" 1 "Low" 0 "Off" ;
VAL_ 2566770174 RearWiperSwitch 15 "Not available" 6 "Mist" 5 "Delayed 2" 4 "Delayed 1" 3 "High" 2 "Medium" 1 "Low" 0 "Off" ;
VAL_ 2566770174 FrontOperatorWiperSwitch 15 "Not available" 6 "Mist" 5 "Delayed 2" 4 "Delayed 1" 3 "High" 2 "Medium" 1 "Low" 0 "Off" ;
VAL_ 2566770174 FrontNonoperatorWiperSwitch 15 "Not available" 6 "Mist" 5 "Delayed 2" 4 "Delayed 1" 3 "High" 2 "Medium" 1 "Low" 0 "Off" ;
VAL_ 2566769662 EngTorqueCurveSelectionCmd 15 "Not supported" 14 "SAE reserved" 2 "Indicates that Torque Curve 2 is selected" 1 "Indicates that Torque Curve 1 is selected" 0 "Indicates that this parameter is not presently requesting a different torque curve be used" ;
VAL_ 2566769662 EngAltDroopAuxInputSelect 15 "-  Not available" 14 "-  Error condition" 1 "thru 1101" 0 "- Normal Droop Setting is selected" ;
VAL_ 2566769662 EngAltDroopRemoteAccelSelect 15 "-  Not available" 14 "-  Error condition" 1 "thru 1101" 0 "- Normal Droop Setting is selected" ;
VAL_ 2566769662 EngAltDroopAccel2Select 15 "- Not available" 14 "-  Error condition" 1 "thru 1101" 0 "- Normal Droop Setting is selected" ;
VAL_ 2566769662 EngAltDroopAccel1Select 15 "- Not available" 14 "-  Error condition" 1 "thru 1101" 0 "- Normal Droop Setting is selected" ;
VAL_ 2566769662 EngAltRatingSelect 255 "Not available" 254 "Error condition." 3 "indicates that the Alternate Power Fueling 3 is selected" 2 "indicates that the Alternate Power Fueling 2 is selected" 1 "indicates that the Alternate Power Fueling 1 is selected" 0 "indicates that Maximum Power Fueling is selected" ;
VAL_ 2566769662 EngAltLowIdleSwitch 3 "Not available or Unused" 2 "Error" 1 "Alternate low idle point is selected" 0 "Default low idle point is selected" ;
VAL_ 2566769662 EngSynchronizationSwitch 3 "Not available or Unused" 2 "Error" 1 "Functionality is enabled" 0 "Functionality is disabled" ;
VAL_ 2566769662 EngAuxGovernorSwitch 3 "Not available" 2 "Error condition" 1 "Auxiliary Governor is enabled" 0 "Auxiliary Governor is disabled" ;
VAL_ 2566768638 EngTorqueCurveSelection 0 "Indicates that the engine is using a torque that is not presently selected by SPN 6796" 15 "Not supported" 14 "Error" 2 "Indicates that Torque Curve 2 is selected" 1 "Indicates that Torque Curve 1 is selected" ;
VAL_ 2566768638 EngAltDroopAuxInputSelectState 15 "-  Not available" 14 "-  SAE reserved" 1 "thru 1101" 0 "- Control state is Normal Droop Setting" ;
VAL_ 2566768638 EngAltDropRemoteAccelSelectState 15 "-  Not available" 14 "-  SAE reserved" 1 "thru 1101" 0 "- Control state is Normal Droop Setting" ;
VAL_ 2566768638 EngAltDroopAccel2SelectState 15 "-  Not available" 14 "-  SAE reserved" 1 "thru 1101" 0 "- Control's state is Normal Droop Setting" ;
VAL_ 2566768638 EngAltDroopAccel1SelectState 15 "-  Not available" 14 "-  SAE reserved" 1 "thru 1101" 0 "- Control state is Normal Droop Setting" ;
VAL_ 2566768638 EngAltRatingSelectState 255 "Not available" 254 "SAE reserved" 3 "Control state is Alternate Power Fueling 3" 2 "Control state is Alternate Power Fueling 2 " 1 "Control state is Alternate Power Fueling 1 " 0 "Control state is Maximum Power Fueling" ;
VAL_ 2566768638 EngAltLowIdleSelectState 3 "not available" 2 "SAE reserved" 1 "Alternate idle state" 0 "Normal idle state" ;
VAL_ 2566768638 EngMultiUnitSyncState 3 "Not available" 2 "SAE reserved" 1 "Control State is Functionality enabled" 0 "Control State is Functionality disabled" ;
VAL_ 2566768638 EngAuxGovernorState 3 "Not available" 2 "SAE reserved" 1 "Control State is Auxiliary Governor enabled" 0 "Control State is Auxiliary Governor disabled" ;
VAL_ 2365443326 HighLowBeamSwitch 3 "Not available" 2 "Error" 1 "High Beam Selected" 0 "Low Beam Selected" ;
VAL_ 2365443326 HazardLightSwitch 3 "Not available" 2 "Error" 1 "Hazard Lamps to be Flashing" 0 "Hazard Lamps to be Off" ;
VAL_ 2365443326 TurnSignalSwitch 15 "Not available" 14 "Error" 2 "Right turn to be Flashing" 1 "Left Turn to be Flashing" 0 "No Turn being signaled" ;
VAL_ 2365443326 MainLightSwitch 15 "Not available" 14 "Error" 8 "Delayed Off" 3 "Headlight and Park On" 2 "Headlight On" 1 "Park On" 0 "Off" ;
VAL_ 2365443326 WorkLightSwitch 15 "Not available" 14 "Error" 4 "Work Light Combination #4 On" 3 "Work Light Combination #3 On" 2 "Work Light Combination #2 On" 1 "Work Light Combination #1 On" 0 "Off" ;
VAL_ 2566802686 BlackOutWorkLampSelect 3 "Not Supported" 2 "Reserved" 1 "On" 0 "Off" ;
VAL_ 2566802686 NightVisionIlluminatorSelect 3 "Not Supported" 2 "Reserved" 1 "On" 0 "Off" ;
VAL_ 2566802686 BlackOutBrake_StopLampSelect 3 "Not Supported" 2 "Reserved" 1 "On" 0 "Off" ;
VAL_ 2566802686 ConvoyDrivingLampSelect 3 "Not Supported" 2 "Reserved" 1 "On" 0 "Off" ;
VAL_ 2566802686 ConvoyLampSelect 3 "Not Supported" 2 "Reserved" 1 "On" 0 "Off" ;
VAL_ 2566802686 FrontBlackOutMarkerLampSelect 3 "Not Supported" 2 "Reserved" 1 "On" 0 "Off" ;
VAL_ 2566802686 RearBlackOutMarkerSelect 3 "Not Supported" 2 "Reserved" 1 "On" 0 "Off" ;
VAL_ 2566774014 SlowVesselModeStatus 3 "Take no action" 2 "Reserved" 1 "Slow vessel mode is ACTIVE." 0 "Slow vessel mode is OFF." ;
VAL_ 2566774014 TrollingModeStatus 3 "Take no action" 2 "Reserved" 1 "Trolling mode is ACTIVE." 0 "Trolling mode is OFF." ;
VAL_ 2566774014 EngThrttlSynchrnzationModeStatus 15 "Take no action" 4 "Synchronized Master" 3 "Synchronized Starboard" 2 "Synchronized Port" 1 "Synchronized Center" 0 "Not Synchronized" ;
VAL_ 2432595710 DisplayDeadbands 15 "Not Available" 2 "- Wide = +/- 24mm" 1 "- Standard = +/- 12mm" 0 "- Narrow = +/- 4.5mm" ;
VAL_ 2432595710 LEDPatternCtrl 15 "Not Available" 2 "- 7 Channel" 1 "- Offset" 0 "- 5 Channel" ;
VAL_ 2432595710 LEDDisplayDeadbandCtrl 15 "Not Available or Not applicable" 4 "+/- 1 mm    " 3 "+/- 5  mm   " 2 "+/- 24 mm  " 1 "+/- 12 mm  " 0 "+/- 4.5 mm " ;
VAL_ 2432595710 LEDDisplayModeCtrl 15 "Not Available or Not Applicable" 2 "Center On-Grade Display Mode 2" 1 "Offset On-Grade Display Mode " 0 "Center On-Grade Display Mode 1" ;
VAL_ 2432595710 LEDDisplayData1 255 "Not Available" 254 "Error" 159 "No data" 149 "High Coarse" 148 "High Medium/Coarse" 147 "High Medium" 146 "High Medium/Fine" 145 "High Fine" 144 "On Grade" 132 "Low Fine" 131 "Low Medium/Fine" 130 "Low Medium" 129 "Low Medium/Coarse" 128 "Low Coarse" 32 "Low Coarse LED on" 16 "Low Fine LED on" 8 "On-grade LED on" 4 "High Fine LED on" 2 "High Coarse LED on" ;
VAL_ 2365486590 LaserReceiverType 4 "2.5 Meter Survey Receiver" 3 "2 Meter Survey Receiver" 2 "1 Meter Survey Receiver" 1 "Linear Laser Receiver" 0 "Reserved " ;
VAL_ 2365485566 LaserTracerInformation 32 "Curb" 16 "Stringline" 8 "Previous pass" 4 "Valid target" 2 "Laser is ready" 1 "Laser power is on" ;
VAL_ 2365485566 LEDDisplayData2 255 "Not Available" 254 "Error" 159 "No data" 149 "High Coarse" 148 "High Medium/Coarse" 147 "High Medium" 146 "High Medium/Fine" 145 "High Fine" 144 "On Grade" 132 "Low Fine" 131 "Low Medium/Fine" 130 "Low Medium" 129 "Low Medium/Coarse" 128 "Low Coarse" 64 "Right LED on" 32 "Left LED on" 16 "Down LED on" 8 "Up LED on" 4 "On-grade “C” LED on" 2 "On-grade “B” LED on" 1 "On-grade “A” LED on" ;
VAL_ 2364542462 StElvtnSensor2ReferenceElevation 3 "Don't Care / Take No Action" 2 "Reserved" 1 "Set Reference Elevation" 0 "Do not Set Reference Elevation" ;
VAL_ 2364542462 StElvtnSensor1ReferenceElevation 3 "Don't Care / Take No Action" 2 "Reserved" 1 "Set Reference Elevation" 0 "Do not Set Reference Elevation" ;
VAL_ 2364542462 SdshftDsrdBldeOffsetOperatorCtrl 15 "Not Installed" 14 "Error Indicator" 3 "Automatic Operator Control Request" 2 "Manual Operator Control Request" 1 "Momentary Operator Control Request" 0 "No Operator Control Request" ;
VAL_ 2364542462 SdshiftBladeCtrlModeOperatorCtrl 15 "Not installed" 14 "Error Indicator" 2 "Decrement Operator Control Request" 1 "Increment Operator Control Request" 0 "No Operator Control Request" ;
VAL_ 2364542462 RghtDsredBladeOffsetOperatorCtrl 15 "Not installed" 14 "Error Indicator" 2 "Decrement Operator Control Request" 1 "Increment Operator Control Request" 0 "No Operator Control Request" ;
VAL_ 2364542462 LftDsiredBladeOffsetOperatorCtrl 15 "Not installed" 14 "Error Indicator" 2 "Decrement Operator Control Request" 1 "Increment Operator Control Request" 0 "No Operator Control Request" ;
VAL_ 2364542462 RightBladeCtrlModeOperatorCtrl 15 "Not Installed" 14 "Error Indicator" 3 "Automatic Operator Control Request" 2 "Manual Operator Control Request" 1 "Momentary Operator Control Request" 0 "No Change" ;
VAL_ 2364542462 LeftBladeCtrlModeOperatorCtrl 15 "Not Installed" 14 "Error Indicator" 3 "Automatic Operator Control Request" 2 "Manual Operator Control Request" 1 "Momentary Operator Control Request" 0 "No Change" ;
VAL_ 2364542462 BladeAutoModeCmd 15 "Not Supported" 14 "Error Indicator" 4 "Auto Not Allowed" 3 "Service Mode" 2 "Suspend Auto" 1 "Activity Allows Auto" 0 "Auto Allowed" ;
VAL_ 2364542462 DesiredGradeOffsetSwitch 15 "Not installed" 14 "Error Indicator" 2 "Decrement button pressed" 1 "Increment button pressed" 0 "No button pressed" ;
VAL_ 2364542462 BladeCtrlModeSwitch 15 "Not Installed" 14 "Error Indicator" 3 "Automatic button pressed" 2 "Manual button pressed" 1 "Mode button pressed" 0 "No button pressed" ;
VAL_ 2633883646 FrontWheelDriveActuatorStatus 3 "Not Available" 2 "Error" 1 "Front Wheel Drive Actuator engaged" 0 "Front Wheel Drive Actuator not engaged" ;
VAL_ 2633880062 FMSstandardRequestsSupported 3 "Don't care" 2 "Reserved" 1 "On request mode is supported" 0 "On request mode is not supported" ;
VAL_ 2633880062 FMSstandardDiagnosticsSupported 1 "Diagnostics Is Supported" 0 "Diagnostics Is Not Supported" 3 "Don't care" 2 "Reserved" ;
VAL_ 2566806526 DrverAlertnessWarningSystemState 7 "Not Available / Not Installed" 4 "System monitoring driver behavior" 3 "System available" 2 "System temporarily not available" 1 "Initializing" 0 "System installed but disabled" ;
VAL_ 2566806526 LnDpartureIndicationEnableStatus 3 "Not Used" 2 "Reserved" 1 "Lane Departure Indication enabled " 0 "Lane Departure indication disabled" ;
VAL_ 2566806526 LaneTrackingStatusLeftSide 3 "Don't care/Take no action" 2 "Reserved" 1 "Tracking Left side" 0 "Not Tracking Left side" ;
VAL_ 2566806526 LaneTrackingStatusRightSide 3 "Don't Care/take no action" 2 "Reserved" 1 "Tracking Right side" 0 "Not Tracking Right side" ;
VAL_ 2431649790 LaneDepartureImminentLeftSide 3 "Not used" 2 "Reserved" 1 "Imminent" 0 "Not imminent" ;
VAL_ 2431649790 LaneDepartureImminentRightSide 3 "Not Used" 2 "Reserved" 1 "Imminent" 0 "Not imminent" ;
VAL_ 2431649790 LaneDepartureRight 3 "Take no action" 2 "Reserved" 1 "Middle of the vehicle departs the lane to the right side" 0 "Middle of the vehicle does not depart the lane to the right side" ;
VAL_ 2431649790 LaneDepartureLeft 3 "Take no action" 2 "Reserved" 1 "Middle of the vehicle departs the lane to the left side" 0 "Middle of the vehicle does not depart the lane to the left side" ;
VAL_ 2431649790 DriverAlertnessWarning 7 "Not Available" 3 "Level 3" 2 "Level 2" 1 "Level 1" 0 "No distracted driving condition detected" ;
VAL_ 2633929214 EngFuelLeakage2 3 "Not available" 2 "Error" 1 "leakage detected" 0 "no leakage detected" ;
VAL_ 2633929214 EngFuelLeakage1 3 "Not available" 2 "Error" 1 "leakage detected" 0 "no leakage detected" ;
VAL_ 2566831614 FanDriveState 15 "Not available" 14 "Other" 13 "Engine brake" 12 "Timer" 11 "A/C system" 10 "Transmission retarder" 9 "Manual control" 8 "Reverse Operation" 7 "Default Operation" 6 "Excessive hydraulic oil temperature" 5 "Excessive transmission oil temperature" 4 "Excessive engine coolant temperature" 3 "Excessive engine oil temperature" 2 "Excessive engine air temperature" 1 "Engine system-General" 0 "Fan off" ;
VAL_ 2566820094 EngTorqueLimitFeature 7 "Not available" 4 "Current torque rating" 3 "Previous torque rating" 2 "First torque rating" 1 "Highest torque rating" 0 "Reserved" ;
VAL_ 2566820094 TorqueLimitingFeatureStatus 3 "Not available" 2 "Error" 1 "Enabled" 0 "Disabled" ;
VAL_ 2566802174 TransAutoNeutralSt 5 "Reserved" 4 "Auto-Neutral request received,  shift to Auto-Neutral state is inhibited." 3 "Auto-Neutral request received,  shift to Auto-Neutral state has been achieved." 2 "Auto-Neutral request received,  shift to Auto-Neutral state is pending." 7 "Not Available" 6 "Error" 1 "No request received,  conditions are such that an Auto-Neutral request would NOT be honored." 0 "No request received,  conditions are such that an Auto-Neutral request would be honored." ;
VAL_ 2566802174 TransWarningIndicator 3 "Not available" 2 "Transmission Warning Indicator is flashing" 1 "Transmission Warning Indicator is on continuously" 0 "Transmission Warning Indicator is off" ;
VAL_ 2566802174 TrnsRverseGearShiftInhibitStatus 3 "Not Available" 2 "Error" 1 "Reverse gear shifts are currently inhibited" 0 "Reverse gear shifts are currently allowed" ;
VAL_ 2566802174 TransMode8Indicator 3 "Not available" 2 "Error" 1 "Transmission Mode 8 active" 0 "Transmission Mode 8 not active" ;
VAL_ 2566802174 TransMode7Indicator 3 "Not available" 2 "Error" 1 "Transmission Mode 7 active" 0 "Transmission Mode 7 not active" ;
VAL_ 2566802174 TransMode6Indicator 3 "Not available" 2 "Error" 1 "Transmission Mode 6 active" 0 "Transmission Mode 6 not active" ;
VAL_ 2566802174 TransMode5Indicator 3 "Not available" 2 "Error" 1 "Transmission Mode 5 active" 0 "Transmission Mode 5 not active" ;
VAL_ 2566802174 TransMode1Indicator 3 "Not available" 2 "Error" 1 "Transmission Mode 1 Active" 0 "Transmission Mode 1 not active" ;
VAL_ 2566802174 TransMode2Indicator 3 "Not available" 2 "Error" 1 "Transmission Mode 2 Active" 0 "Transmission Mode 2 not active" ;
VAL_ 2566802174 TransMode3Indicator 3 "Not available" 2 "Error" 1 "Transmission Mode 3 Active" 0 "Transmission Mode 3 not active" ;
VAL_ 2566802174 TransMode4Indicator 3 "Not available" 2 "Error" 1 "Transmission Mode 4 Active" 0 "Transmission Mode 4 not active" ;
VAL_ 2566802174 TransShiftInhibitIndicator 3 "Take no action" 2 "Active, flashing)" 1 "Active, on continuously)" 0 "Inactive" ;
VAL_ 2566802174 TransEngCrankEnable 3 "Not available" 2 "Error" 1 "Cranking enabled" 0 "Cranking disabled" ;
VAL_ 2566802174 ActiveShiftConsoleIndicator 3 "Not available" 2 "Reserved" 1 "Secondary shift console is active" 0 "Primary shift console is active" ;
VAL_ 2566802174 TransReadyForBrakeRelease 3 "Not available" 2 "Error" 1 "Transmission Ready for Brake Release" 0 "Transmission Not Ready for Brake Release" ;
VAL_ 2566802174 TrnsRqstedRangeDisplayFlashState 3 "Take no action" 2 "Reserved" 1 "Active" 0 "Inactive" ;
VAL_ 2566802174 TrnsRqstedRangeDisplayBlankState 3 "Take no action" 2 "Reserved" 1 "Active" 0 "Inactive" ;
VAL_ 2566802174 TransServiceIndicator 3 "Not available" 2 "Transmission Service Indicator is flashing" 1 "Transmission Service Indicator is on continuously" 0 "Transmission Service Indicator is off" ;
VAL_ 2566802174 TransAirSupplyPressIndicator 7 "Not available" 6 "Error indicator" 5 "Not defined" 4 "Over pressure" 3 "No pressure" 2 "Very low pressure" 1 "Low pressure" 0 "Normal Pressure Range" ;
VAL_ 2566802174 TransMode10Indicator 3 "Not available" 2 "Error indicator" 1 "Transmission Mode 10 active" 0 "Transmission Mode 10 not active" ;
VAL_ 2566802174 TransMode9Indicator 3 "Not available" 2 "Error indicator" 1 "Transmission Mode 9 active" 0 "Transmission Mode 9 not active" ;
VAL_ 2633942014 TransForwardDirectionSwitch 3 "Not available" 2 "Error" 1 "On" 0 "Off" ;
VAL_ 2633942014 TransNeutralSwitch 3 "Not available" 2 "Error" 1 "On" 0 "Off" ;
VAL_ 2633942014 TransReverseDirectionSwitch 3 "Not available" 2 "Error" 1 "On" 0 "Off" ;
VAL_ 2633942014 TransLowRangeSenseSwitch 3 "Not available" 2 "Error" 1 "On" 0 "Off" ;
VAL_ 2633942014 TransHighRangeSenseSwitch 3 "Not available" 2 "Error" 1 "On" 0 "Off" ;
VAL_ 2633943038 TransInertiaBrakeActuator 3 "Not available" 2 "Error" 1 "On" 0 "Off" ;
VAL_ 2633943038 TransDefuelActuator 3 "Not available" 2 "Error" 1 "On" 0 "Off" ;
VAL_ 2633943038 TransLockupClutchActuator 3 "Not available" 2 "Error" 1 "On" 0 "Off" ;
VAL_ 2633943038 TransClutchActuator 3 "Not available" 2 "Error" 1 "On" 0 "Off" ;
VAL_ 2633943038 TransSplitterIndirectActuator 3 "Not available" 2 "Error" 1 "On" 0 "Off" ;
VAL_ 2633943038 TransSplitterDirectActuator 3 "Not available" 2 "Error" 1 "On" 0 "Off" ;
VAL_ 2633943038 TransRangeLowActuator 3 "Not available" 2 "Error" 1 "On" 0 "Off" ;
VAL_ 2633943038 TransRangeHighActuator 3 "- Not available" 2 "- Error" 1 "-On" 0 "-Off" ;
VAL_ 2633943038 TransShiftFingerGearActuator2 3 "Not available" 2 "Error" 1 "On" 0 "Off" ;
VAL_ 2633943038 TransShiftFingerRailActuator2 3 "Not available" 2 "Error" 1 "On" 0 "Off" ;
VAL_ 2633943038 TransShiftFingerGearActuator1 3 "Not available" 2 "Error" 1 "On" 0 "Off" ;
VAL_ 2633943038 TransShiftFingerRailActuator1 3 "Not available" 2 "Error" 1 "On" 0 "Off" ;
VAL_ 2633943038 TrnsShftFngerCenterRailIndicator 3 "Not available" 2 "Error" 1 "On" 0 "Off" ;
VAL_ 2633943038 TrnsShftFngerEngagementIndicator 3 "Not available" 2 "Error" 1 "On" 0 "Off" ;
VAL_ 2633943038 TransShiftFingerNeutralIndicator 3 "Not available" 2 "Error" 1 "On" 0 "Off" ;
VAL_ 2364539646 MomentaryEngMaxPowerEnable 3 "not available" 2 "fault" 1 "momentarily requesting maximum power available" 0 "not requesting maximum power available" ;
VAL_ 2364539646 ProgressiveShiftDisable 3 "Take no action" 2 "Reserved" 1 "Progressive shift is disabled" 0 "Progressive shift is not disabled" ;
VAL_ 2364539646 EngMomentaryOverspeedEnable 3 "Take no action" 2 "Reserved" 1 "Momentary engine overspeed is enabled" 0 "Momentary engine overspeed is disabled" ;
VAL_ 2364539646 TrnsTrqCnvrtrLckpTrnstnInProcess 3 "Not available" 2 "Error" 1 "Transition is in process" 0 "Transition is not in process" ;
VAL_ 2364539646 TransShiftInProcess 3 "-  Not available" 2 "-  Error" 1 "-  Shift in process" 0 "-  Shift is not in process " ;
VAL_ 2364539646 TrnsTorqueConverterLockupEngaged 3 "Not available" 2 "Error" 1 "Torque converter lockup engaged" 0 "Torque converter lockup disengaged" ;
VAL_ 2364539646 TransDrivelineEngaged 3 "Not available" 2 "Error" 1 "Driveline engaged" 0 "Driveline disengaged" ;
VAL_ 2565868542 TypeOfSteerTrans 15 "Not available" 3 "Hybrid steering transmission" 2 "Purely electric steering transmission" 1 "Purely hydraulic steering transmission" 0 "Purely mechanical steering transmission" ;
VAL_ 2565868542 TypeOfSteerForces 15 "Not Available" 3 "Self tracking steering equipment" 2 "Full power steering equipment" 1 "Power assisted steering equipment" 0 "Manual steering equipment" ;
VAL_ 2565868542 SteerType 15 "Not Available" 1 "Auxiliary steering equipment" 0 "Main steering system" ;
VAL_ 2565868542 SteerableLiftAxleLoweringInhibit 1 "Lowering inhibited" 0 "Lowering allowed" 3 "Not available" 2 "Reserved" ;
VAL_ 2565868542 StatusOfSteerAxle 15 "Not available" 5 "Axle steering in special mode" 4 "Axle not active because of an error" 3 "Axle centered,  because of an error" 2 "Axle centered" 1 "Axle steering active" 0 "Axle steering not active" ;
VAL_ 2633941758 TransOutputRetarder 3 "Not available" 2 "Error" 1 "On" 0 "Off" ;
VAL_ 2565865726 RetarderRoadSpeedExceededStatus 3 "Don't care/Take no action" 2 "Reserved" 1 "Road speed is above threshold and retarder is allowed to be activated" 0 "Road speed is below threshold " ;
VAL_ 2565865726 RetarderRoadSpeedLimitSwitch 3 "Not Available" 2 "Error Indicator" 1 "Road speed limiting by retarder is enabled" 0 "Road speed limiting by retarder is disabled" ;
VAL_ 2565865726 RetarderRequestingBrakeLight 0 "Retarder is not requesting that the brake lights are illuminated" 3 "Not available/Take no action" 2 "Reserved" 1 "Retarder is requesting that the brake lights are illuminated" ;
VAL_ 2565865726 EngCoolantLoadIncrease 3 "Not available" 2 "Error" 1 "Coolant load increase possible" 0 "No coolant load increase" ;
VAL_ 2565865726 RetarderEnableShiftAssistSwitch 3 "Not available" 2 "Error" 1 "Retarder, shift assist enabled" 0 "Retarder, shift assist disabled" ;
VAL_ 2565865726 RetarderEnableBrakeAssistSwitch 3 "Not available" 2 "Error" 1 "Retarder, brake assist enabled" 0 "Retarder, brake assist disabled" ;
VAL_ 2633935358 EngExhstGsOxygnSnsrClsdLpOprtion 3 "Don't Care/take no action" 2 "Reserved" 1 "Engine using the exhaust oxygen sensor for a closed loop operation" 0 "Engine not using the exhaust oxygen sensor" ;
VAL_ 2365447166 Joystick3Button13PressedStatus 3 "Not Available" 2 "Error Indicator" 1 "Button pressed" 0 "Button not pressed" ;
VAL_ 2365447166 Joystick3Button14PressedStatus 3 "Not Available" 2 "Error Indicator" 1 "Button pressed" 0 "Button not pressed" ;
VAL_ 2365447166 Joystick3Button15PressedStatus 3 "Not Available" 2 "Error Indicator" 1 "Button pressed" 0 "Button not pressed" ;
VAL_ 2365447166 Joystick3Button16PressedStatus 3 "Not Available" 2 "Error Indicator" 1 "Button pressed" 0 "Button not pressed" ;
VAL_ 2365447166 Jystick3GripXAxisDetentPosStatus 3 "Not Available" 2 "Error Indicator" 1 "In the Detent Position" 0 "Not in the Detent Position" ;
VAL_ 2365447166 Jystick3GripYAxisDetentPosStatus 3 "Not Available" 2 "Error Indicator" 1 "In the Detent Position" 0 "Not in the Detent Position" ;
VAL_ 2365447166 Jystick3ThetaAxisDetentPosStatus 3 "Not Available" 2 "Error Indicator" 1 "In the Detent Position" 0 "Not in the Detent Position" ;
VAL_ 2365447166 Jystck3ThtAxsClckwsPstvPosStatus 3 "Not Available" 2 "Error Indicator" 1 "On positive side of Neutral" 0 "Not on Positive side of Neutral" ;
VAL_ 2365447166 Jystck3ThetaAxisNeutralPosStatus 3 "Not Available" 2 "Error Indicator" 1 "In Neutral Position" 0 "Not in Neutral Position" ;
VAL_ 2365447166 Jystck3GrpYAxsLvrFrwrdPstvPsStts 3 "Not Available" 2 "Error Indicator" 1 "On positive side of Neutral" 0 "Not on Positive side of Neutral" ;
VAL_ 2365447166 Jystck3GrpYAxsLvrBckNgtvPsStatus 3 "Not Available" 2 "Error Indicator" 1 "On negative side of Neutral" 0 "Not on negative side of Neutral" ;
VAL_ 2365447166 Jystck3GripYAxisNeutralPosStatus 3 "Not Available" 2 "Error Indicator" 1 "In Neutral Position" 0 "Not in Neutral Position" ;
VAL_ 2365447166 Jystck3GrpXAxsLvrRghtPstvPsSttus 3 "Not Available" 2 "Error Indicator" 1 "On positive side of Neutral" 0 "Not on Positive side of Neutral" ;
VAL_ 2365447166 Jystck3GrpXAxsLvrLftNgtvPsStatus 3 "Not Available" 2 "Error Indicator" 1 "On negative side of Neutral" 0 "Not on negative side of Neutral" ;
VAL_ 2365447166 Jystck3GripXAxisNeutralPosStatus 3 "Not Available" 2 "Error Indicator" 1 "On negative side of Neutral" 0 "Not on negative side of Neutral" ;
VAL_ 2365447166 Jystck3ThtAxsCntrClckwsNgtvPsStt 3 "Not Available" 2 "Error Indicator" 1 "On negative side of Neutral" 0 "Not on negative side of Neutral" ;
